VERSION ""

NS_ :

BS_:

BU_: BAP_Tester BedienDisp_vo BedienSG_hi CGS DDA Gateway Gateway_PAG GurtMikrofon OTA_FC ZR_High ZR_LIMU ZR_MIB_TOP_ab_Gen3 ZR_Standard

BO_ 987 Gateway_72: 8 Gateway_MQB
 SG_ BCM_01_Old : 0|1@1+ (1,0) [0|1] "" Airbag_MQB
 SG_ SMLS_01_Old : 1|1@1+ (1,0) [0|1] "" Motor_Diesel_MQB,Motor_Otto_MQB
 SG_ ZV_02_Old : 2|1@1+ (1,0) [0|1] "" Getriebe_DQ_Hybrid_MQB,Getriebe_DQ_MQB,Motor_Diesel_MQB,Motor_Hybrid_MQB,Motor_Otto_MQB
 SG_ Wiper_01_Old : 3|1@1+ (1,0) [0|1] "" Motor_Diesel_MQB,Motor_Hybrid_MQB,Motor_Otto_MQB
 SG_ Trailer_01_Old : 4|1@1+ (1,0) [0|1] "" Getriebe_DQ_Hybrid_MQB,Getriebe_DQ_MQB
 SG_ Climate_Sensor_02_Old : 5|1@1+ (1,0) [0|1] "" Getriebe_DQ_Hybrid_MQB,Getriebe_DQ_MQB,Motor_Diesel_MQB,Motor_Hybrid_MQB,Motor_Otto_MQB
 SG_ VSG_01_Old : 6|1@1+ (1,0) [0|1] "" Airbag_MQB
 SG_ Climate_01_Old : 7|1@1+ (1,0) [0|1] "" Vector__XXX
 SG_ WFS_01_Old : 8|1@1+ (1,0) [0|1] "" Vector__XXX
 SG_ Light_Req_01_Old : 9|1@1+ (1,0) [0|1] "" Vector__XXX
 SG_ ZV_HFS_Open : 20|1@1+ (1,0) [0|1] "" Vector__XXX
 SG_ ZV_HBFS_Open : 21|1@1+ (1,0) [0|1] "" Vector__XXX
 SG_ VS_VD_Open_ver : 22|1@1+ (1,0) [0|1] "" Airbag_MQB
 SG_ VS_VD_Closed_ver : 23|1@1+ (1,0) [0|1] "" Vector__XXX
 SG_ ZV_BT_Open : 24|1@1+ (1,0) [0|1] "" Vector__XXX
 SG_ BCM1_ReversingLight_Switch : 25|1@1+ (1,0) [0|1] "" Airbag_MQB
 SG_ ZV_FT_Open : 26|1@1+ (1,0) [0|1] "" Getriebe_DQ_Hybrid_MQB,Getriebe_DQ_MQB,Motor_Diesel_MQB,Motor_Hybrid_MQB,Motor_Otto_MQB
 SG_ Wiper_Front_Active : 27|1@1+ (1,0) [0|1] "" Motor_Diesel_MQB,Motor_Hybrid_MQB,Motor_Otto_MQB
 SG_ AAG_Trailer_Detected : 28|1@1+ (1,0) [0|1] "" Getriebe_DQ_Hybrid_MQB,Getriebe_DQ_MQB
 SG_ BCM1_MH_Switch : 29|1@1+ (1,0) [0|1] "" Vector__XXX
 SG_ ZV_HD_Open : 30|1@1+ (1,0) [0|1] "" Vector__XXX
 SG_ Wash_Front_Active : 31|1@1+ (1,0) [0|1] "" Vector__XXX
 SG_ TERM_ThermalManagement : 32|2@1+ (1,0) [0|3] "" Vector__XXX
 SG_ WFS_Key_DriveAuthorisation : 34|4@1+ (1,0) [0|15] "" Vector__XXX
 SG_ BCM1_RHeadlights_Veh_Req : 38|1@1+ (1,0) [0|1] "" Vector__XXX
 SG_ BCM1_RHeadlights_Ahg_Req : 39|1@1+ (1,0) [0|1] "" Vector__XXX
 SG_ BH_HighBeam : 49|1@1+ (1,0) [0|1] "" Vector__XXX
 SG_ BH_Indicator_Left : 50|1@1+ (1,0) [0|1] "" Motor_Diesel_MQB,Motor_Otto_MQB
 SG_ BH_Indicator_Right : 51|1@1+ (1,0) [0|1] "" Motor_Diesel_MQB,Motor_Otto_MQB
 SG_ BCM1_OBD_FStatus_ATemp : 52|4@1+ (1,0) [0|15] "" Getriebe_DQ_Hybrid_MQB,Getriebe_DQ_MQB,Motor_Diesel_MQB,Motor_Hybrid_MQB,Motor_Otto_MQB
 SG_ BCM1_Outside_Temp_Unfilt : 56|8@1+ (0.5,-50) [-50|76] "Unit_DegreCelsi" Getriebe_DQ_Hybrid_MQB,Getriebe_DQ_MQB,Motor_Diesel_MQB,Motor_Hybrid_MQB,Motor_Otto_MQB

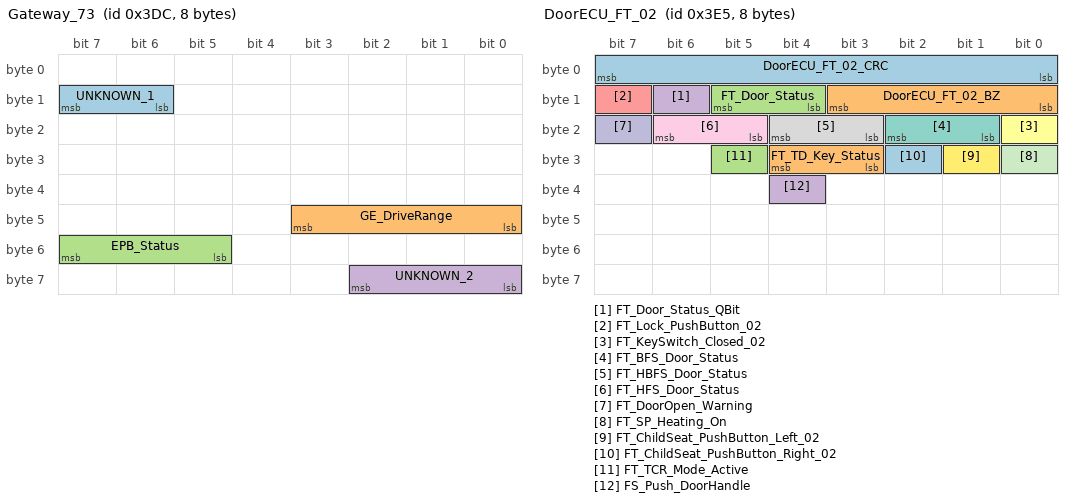
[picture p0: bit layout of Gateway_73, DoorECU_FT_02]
BO_ 988 Gateway_73: 8 XXX
 SG_ UNKNOWN_1 : 15|2@0+ (1,0) [0|3] "" XXX
 SG_ GE_DriveRange : 40|4@1+ (1,0) [0|15] "" XXX
 SG_ EPB_Status : 53|3@1+ (1,0) [0|7] "" XXX
 SG_ UNKNOWN_2 : 58|3@0+ (1,0) [0|7] "" XXX

BO_ 997 DoorECU_FT_02: 8 Gateway
 SG_ DoorECU_FT_02_CRC : 0|8@1+ (1,0) [0|255] "" Vector__XXX
 SG_ DoorECU_FT_02_BZ : 8|4@1+ (1,0) [0|15] "" Vector__XXX
 SG_ FT_Door_Status : 12|2@1+ (1,0) [0|3] "" OTA_FC,ZR_High
 SG_ FT_Door_Status_QBit : 14|1@1+ (1,0) [0|1] "" ZR_High
 SG_ FT_Lock_PushButton_02 : 15|1@1+ (1,0) [0|1] "" ZR_High
 SG_ FT_KeySwitch_Closed_02 : 16|1@1+ (1,0) [0|1] "" ZR_High
 SG_ FT_BFS_Door_Status : 17|2@1+ (1,0) [0|3] "" ZR_High
 SG_ FT_HBFS_Door_Status : 19|2@1+ (1,0) [0|3] "" ZR_High
 SG_ FT_HFS_Door_Status : 21|2@1+ (1,0) [0|3] "" ZR_High
 SG_ FT_DoorOpen_Warning : 23|1@1+ (1,0) [0|1] "" Vector__XXX
 SG_ FT_SP_Heating_On : 24|1@1+ (1,0) [0|1] "" Vector__XXX
 SG_ FT_ChildSeat_PushButton_Left_02 : 25|1@1+ (1,0) [0|1] "" ZR_High
 SG_ FT_ChildSeat_PushButton_Right_02 : 26|1@1+ (1,0) [0|1] "" ZR_High
 SG_ FT_TD_Key_Status : 27|2@1+ (1,0) [0|3] "" ZR_High
 SG_ FT_TCR_Mode_Active : 29|1@1+ (1,0) [0|1] "" Vector__XXX
 SG_ FS_Push_DoorHandle : 36|1@1+ (1,0) [0|1] "" Vector__XXX

BO_ 1004 MEB_TSK_01: 8 XXX
 SG_ TSK_State : 53|3@1+ (1,0) [0|7] "" XXX

BO_ 1031 PLA_04: 8 XXX

BO_ 1122 PSD_04: 8 ZR_High
 SG_ PSD_Segment_ID : 0|6@1+ (1,0) [2|63] "" Gateway,Gateway_PAG
 SG_ PSD_Predecessor_Segment_ID : 6|6@1+ (1,0) [2|63] "" Gateway,Gateway_PAG
 SG_ PSD_SegmentLength : 12|7@1+ (2,0) [0|254] "Unit_Meter" Gateway,Gateway_PAG,OTA_FC
 SG_ PSD_Strassenkategorie : 19|3@1+ (1,0) [0|7] "" Gateway,Gateway_PAG,OTA_FC
 SG_ PSD_EndCurvature : 22|8@1+ (1,0) [0|254] "Unit_None" Gateway,Gateway_PAG
 SG_ PSD_EndCurvature_Sign : 30|1@1+ (1,0) [0|1] "" Gateway,Gateway_PAG
 SG_ PSD_Idenditaets_ID : 31|6@1+ (1,0) [2|63] "" Gateway,Gateway_PAG
 SG_ PSD_ADAS_Quality : 37|1@1+ (1,0) [0|1] "" Gateway,Gateway_PAG
 SG_ PSD_MostLikely_Path : 38|1@1+ (1,0) [0|1] "" Gateway,Gateway_PAG
 SG_ PSD_Straightest_Path : 39|1@1+ (1,0) [0|1] "" Gateway,Gateway_PAG
 SG_ PSD_Lanes_Count : 40|3@1+ (1,0) [0|7] "" Gateway,Gateway_PAG,OTA_FC
 SG_ PSD_Bebauung : 43|1@1+ (1,0) [0|1] "" Gateway,Gateway_PAG
 SG_ PSD_Segment_Complete : 44|1@1+ (1,0) [0|1] "" Gateway,Gateway_PAG
 SG_ PSD_Ramp : 45|2@1+ (1,0) [0|3] "" Gateway,Gateway_PAG
 SG_ PSD_StartCurvature : 47|8@1+ (1,0) [0|254] "" Gateway,Gateway_PAG
 SG_ PSD_StartCurvature_Sign : 55|1@1+ (1,0) [0|1] "" Gateway,Gateway_PAG
 SG_ PSD_Abzweigerichtung : 56|1@1+ (1,0) [0|1] "" Gateway,Gateway_PAG
 SG_ PSD_Abzweigewinkel : 57|7@1+ (1.417323,0) [0|180.000021] "" Gateway,Gateway_PAG

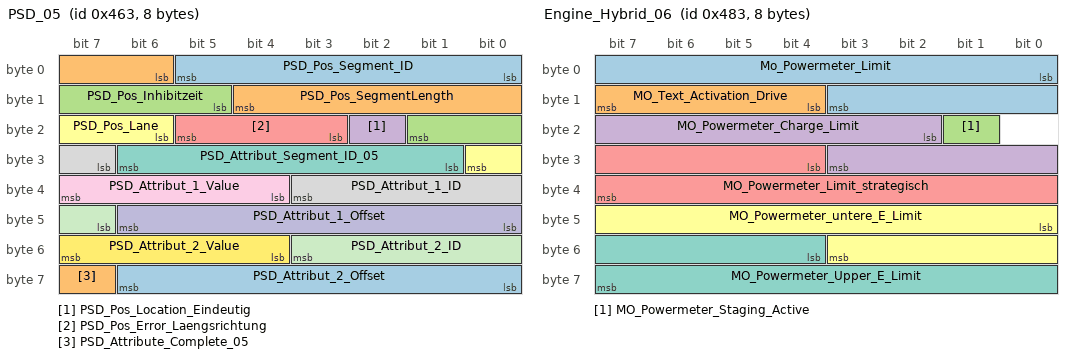
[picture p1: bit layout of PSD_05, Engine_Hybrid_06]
BO_ 1123 PSD_05: 8 ZR_High
 SG_ PSD_Pos_Segment_ID : 0|6@1+ (1,0) [2|63] "" Gateway,Gateway_PAG
 SG_ PSD_Pos_SegmentLength : 6|7@1+ (2,0) [0|254] "Unit_Meter" Gateway,Gateway_PAG
 SG_ PSD_Pos_Inhibitzeit : 13|5@1+ (10,0) [0|310] "Unit_MilliSecon" Gateway,Gateway_PAG
 SG_ PSD_Pos_Location_Eindeutig : 18|1@1+ (1,0) [0|1] "" Gateway,Gateway_PAG
 SG_ PSD_Pos_Error_Laengsrichtung : 19|3@1+ (1,0) [0|7] "" Gateway,Gateway_PAG
 SG_ PSD_Pos_Lane : 22|3@1+ (1,0) [0|7] "" Gateway,Gateway_PAG,OTA_FC
 SG_ PSD_Attribut_Segment_ID_05 : 25|6@1+ (1,0) [2|63] "" Gateway,Gateway_PAG
 SG_ PSD_Attribut_1_ID : 31|5@1+ (1,0) [1|31] "" Gateway,Gateway_PAG
 SG_ PSD_Attribut_1_Value : 36|4@1+ (1,0) [0|15] "" Gateway,Gateway_PAG
 SG_ PSD_Attribut_1_Offset : 40|7@1+ (2,0) [0|254] "Unit_Meter" Gateway,Gateway_PAG
 SG_ PSD_Attribut_2_ID : 47|5@1+ (1,0) [1|31] "" Gateway,Gateway_PAG
 SG_ PSD_Attribut_2_Value : 52|4@1+ (1,0) [0|15] "" Gateway,Gateway_PAG
 SG_ PSD_Attribut_2_Offset : 56|7@1+ (2,0) [0|254] "Unit_Meter" Gateway,Gateway_PAG
 SG_ PSD_Attribute_Complete_05 : 63|1@1+ (1,0) [0|1] "" Gateway,Gateway_PAG

BO_ 1124 PSD_06: 8 ZR_High
 SG_ PSD_06_Mux M : 0|3@1+ (1,0) [0|7] "" Gateway,Gateway_PAG
 SG_ PSD_Sys_Segment_ID m0 : 3|6@1+ (1,0) [2|63] "" Gateway,Gateway_PAG
 SG_ PSD_Sys_Laendercode m0 : 9|8@1+ (1,0) [0|255] "" Gateway,Gateway_PAG
 SG_ PSD_Sys_Speed_Unit m0 : 17|1@1+ (1,0) [0|1] "" Gateway,Gateway_PAG
 SG_ PSD_Sys_Verkehrsrichtung m0 : 18|1@1+ (1,0) [0|1] "" Gateway,Gateway_PAG
 SG_ PSD_Sys_Geometrieguete m0 : 19|2@1+ (1,0) [0|3] "" Gateway,Gateway_PAG
 SG_ PSD_Sys_Mapmatchingguete m0 : 21|2@1+ (1,0) [0|3] "" Gateway,Gateway_PAG
 SG_ PSD_Sys_Age_Map m0 : 23|3@1+ (1,0) [0|7] "" Gateway,Gateway_PAG
 SG_ PSD_Sys_RouteGuidance m0 : 26|1@1+ (1,0) [0|1] "" Gateway,Gateway_PAG,OTA_FC
 SG_ PSD_Sys_US_State m0 : 27|6@1+ (1,0) [0|63] "" Gateway,Gateway_PAG
 SG_ PSD_Sys_Quali_Geometrien m0 : 33|3@1+ (1,0) [0|7] "Unit_None" Gateway,Gateway_PAG
 SG_ PSD_Sys_Quali_LocationInfo m0 : 36|2@1+ (1,0) [0|3] "Unit_None" Gateway,Gateway_PAG
 SG_ PSD_Sys_Quali_Available m0 : 38|1@1+ (1,0) [0|1] "" Gateway,Gateway_PAG
 SG_ PSD_Sys_RouteGuidance_Changed m0 : 39|1@1+ (1,0) [0|1] "" Gateway,Gateway_PAG
 SG_ PSD_Sys_Geometrieguete_Extended m0 : 40|8@1+ (1,0) [0|255] "" Gateway,Gateway_PAG
 SG_ PSD_Sys_Quali_Other_Attribute m0 : 48|3@1+ (1,0) [0|7] "Unit_None" Gateway,Gateway_PAG
 SG_ PSD_Sys_Quali_Gradients m0 : 51|3@1+ (1,0) [0|7] "" Gateway,Gateway_PAG
 SG_ PSD_Sys_Quali_Strassenkennz m0 : 54|3@1+ (1,0) [0|7] "Unit_None" Gateway,Gateway_PAG
 SG_ PSD_Sys_Quali_Tempolimits m0 : 57|3@1+ (1,0) [0|7] "Unit_None" Gateway,Gateway_PAG
 SG_ PSD_Sys_Quali_BeforeJourneyControl m0 : 60|3@1+ (1,0) [0|7] "Unit_None" Gateway,Gateway_PAG
 SG_ PSD_Attribut_Segment_ID m1 : 3|6@1+ (1,0) [2|63] "" Gateway,Gateway_PAG
 SG_ PSD_Attribut_3_ID m1 : 9|5@1+ (1,0) [1|31] "" Gateway,Gateway_PAG
 SG_ PSD_Attribut_3_Offset m1 : 14|7@1+ (2,0) [0|254] "Unit_Meter" Gateway,Gateway_PAG
 SG_ PSD_Attribut_3_Value m1 : 21|4@1+ (1,0) [0|15] "" Gateway,Gateway_PAG
 SG_ PSD_Attribut_4_ID m1 : 25|5@1+ (1,0) [1|31] "" Gateway,Gateway_PAG
 SG_ PSD_Attribut_4_Value m1 : 30|4@1+ (1,0) [0|15] "" Gateway,Gateway_PAG
 SG_ PSD_Attribut_4_Offset m1 : 34|7@1+ (2,0) [0|254] "Unit_Meter" Gateway,Gateway_PAG
 SG_ PSD_Attribut_5_ID m1 : 41|5@1+ (1,0) [1|31] "" Gateway,Gateway_PAG
 SG_ PSD_Attribut_5_Offset m1 : 46|7@1+ (2,0) [0|254] "Unit_Meter" Gateway,Gateway_PAG
 SG_ PSD_Attribut_5_Value m1 : 53|4@1+ (1,0) [0|15] "" Gateway,Gateway_PAG
 SG_ PSD_Attribute_Complete_06 m1 : 57|1@1+ (1,0) [0|1] "" Gateway,Gateway_PAG
 SG_ PSD_Total_Segment_ID m2 : 3|6@1+ (1,0) [2|63] "" Gateway,Gateway_PAG
 SG_ PSD_Total_Offset m2 : 9|7@1+ (2,0) [0|254] "Unit_Meter" Gateway,Gateway_PAG
 SG_ PSD_Total_Speed m2 : 16|5@1+ (1,0) [0|31] "" Gateway,Gateway_PAG,OTA_FC
 SG_ PSD_Total_Type m2 : 21|2@1+ (1,0) [0|3] "" Gateway,Gateway_PAG
 SG_ PSD_Total_Lane_Speed_Limit m2 : 23|6@1+ (1,0) [0|63] "" Gateway,Gateway_PAG
 SG_ PSD_Total_Speed_TrailerCombo m2 : 29|2@1+ (1,0) [0|3] "" Gateway,Gateway_PAG
 SG_ PSD_Total_Speed_Witter m2 : 31|2@1+ (1,0) [0|3] "" Gateway,Gateway_PAG
 SG_ PSD_Total_Speed_Tag_Req m2 : 33|3@1+ (1,0) [0|7] "" Gateway,Gateway_PAG
 SG_ PSD_Total_Speed_Tag_End m2 : 36|3@1+ (1,0) [0|7] "" Gateway,Gateway_PAG
 SG_ PSD_Total_Speed_Std_Req m2 : 39|5@1+ (1,0) [0|24] "Unit_Hours" Gateway,Gateway_PAG
 SG_ PSD_Total_Speed_Std_End m2 : 44|5@1+ (1,0) [0|24] "Unit_Hours" Gateway,Gateway_PAG
 SG_ PSD_Total_NoOvertaking m2 : 49|2@1+ (1,0) [0|3] "" Gateway,Gateway_PAG
 SG_ PSD_Total_VariableTrafficSign m2 : 51|3@1+ (1,0) [0|7] "" Gateway,Gateway_PAG
 SG_ PSD_VariableTrafficSign_Type m2 : 54|2@1+ (1,0) [0|3] "" Gateway,Gateway_PAG
 SG_ PSD_Total_Gesetzlich_Kategorie m2 : 56|3@1+ (1,0) [0|7] "" Gateway,Gateway_PAG
 SG_ PSD_Total_Gesetzlich_Additional m2 : 59|2@1+ (1,0) [0|3] "" Gateway,Gateway_PAG
 SG_ PSD_Total_TrafficSign_Source m2 : 61|2@1+ (1,0) [0|3] "" Gateway,Gateway_PAG
 SG_ PSD_Total_Attribute_Complete m2 : 63|1@1+ (1,0) [0|1] "" Gateway,Gateway_PAG
 SG_ PSD_Tree_Length_VZ m3 : 3|1@1+ (1,0) [0|1] "" Gateway,Gateway_PAG
 SG_ PSD_Tree_Length m3 : 4|25@1+ (1e-05,0) [0|180] "Unit_DegreOfArc" Gateway,Gateway_PAG
 SG_ PSD_Tree_Width_VZ m3 : 29|1@1+ (1,0) [0|1] "" Gateway,Gateway_PAG
 SG_ PSD_Tree_Width m3 : 30|24@1+ (1e-05,0) [0|90] "Unit_DegreOfArc" Gateway,Gateway_PAG
 SG_ PSD_Tree_OffDirection m3 : 54|10@1+ (0.3515625,0) [0|359.6484375] "Unit_DegreOfArc" Gateway,Gateway_PAG
 SG_ PSD_Gradient_1_Segment_ID m4 : 3|6@1+ (1,0) [2|63] "" Gateway,Gateway_PAG
 SG_ PSD_Gradient_1_A_Gradient m4 : 9|7@1+ (0.12,0) [0|15] "Unit_PerCent" Gateway,Gateway_PAG
 SG_ PSD_Gradient_1_A_Sign m4 : 16|1@1+ (1,0) [0|1] "" Gateway,Gateway_PAG
 SG_ PSD_Gradient_1_A_Offset m4 : 17|7@1+ (2,0) [0|254] "Unit_Meter" Gateway,Gateway_PAG
 SG_ PSD_Gradient_1_B_Gradient m4 : 24|7@1+ (0.12,0) [0|15] "Unit_PerCent" Gateway,Gateway_PAG
 SG_ PSD_Gradient_1_B_Sign m4 : 31|1@1+ (1,0) [0|1] "" Gateway,Gateway_PAG
 SG_ PSD_Gradient_1_B_Offset m4 : 32|7@1+ (2,0) [0|254] "Unit_Meter" Gateway,Gateway_PAG
 SG_ PSD_Gradient_1_Attribute_kompl m4 : 39|1@1+ (1,0) [0|1] "" Gateway,Gateway_PAG
 SG_ PSD_Gradient_2_Segment_ID m4 : 40|6@1+ (1,0) [2|63] "" Gateway,Gateway_PAG
 SG_ PSD_Gradient_2_Gradient m4 : 46|7@1+ (0.12,0) [0|15] "Unit_PerCent" Gateway,Gateway_PAG
 SG_ PSD_Gradient_2_Sign m4 : 53|1@1+ (1,0) [0|1] "" Gateway,Gateway_PAG
 SG_ PSD_Gradient_2_Offset m4 : 54|7@1+ (2,0) [0|254] "Unit_Meter" Gateway,Gateway_PAG
 SG_ PSD_Gradient_2_Attribute_kompl m4 : 61|1@1+ (1,0) [0|1] "" Gateway,Gateway_PAG

BO_ 1153 MainUnit_01: 8 ZR_High
 SG_ ZR_LoGeWa_Event_ClusterWarning : 0|4@1+ (1,0) [0|15] "" Gateway,Gateway_PAG
 SG_ Nav_FoD_Status : 4|3@1+ (1,0) [0|7] "" Gateway,Gateway_PAG
 SG_ MIB_ToneAlternator_PH_Available : 9|3@1+ (1,0) [0|7] "" Gateway,Gateway_PAG
 SG_ MMI_Counter_Bedienevent : 12|4@1+ (1,0) [0|15] "" Gateway,Gateway_PAG
 SG_ DSSS_Warning : 16|5@1+ (1,0) [0|31] "" Gateway,Gateway_PAG
 SG_ ZR_Kindersicherung_RSE : 21|1@1+ (1,0) [0|1] "" Gateway,Gateway_PAG
 SG_ ZR_RSE_Activate : 22|1@1+ (1,0) [0|1] "" Gateway,Gateway_PAG
 SG_ MMI_SDS_Active : 23|1@1+ (1,0) [0|1] "" Gateway,Gateway_PAG
 SG_ MU_SecondDisplay : 24|3@1+ (1,0) [0|7] "" Gateway,Gateway_PAG
 SG_ MMI_Phone_Active : 27|1@1+ (1,0) [0|1] "" Gateway,Gateway_PAG
 SG_ MMI_Belt_Mic_ref : 28|1@1+ (1,0) [0|1] "" Gateway,Gateway_PAG,GurtMikrofon
 SG_ ZR_Status_Staging : 29|2@1+ (1,0) [0|3] "" Gateway,Gateway_PAG
 SG_ MMI_Gauges_active : 31|1@1+ (1,0) [0|1] "" BedienDisp_vo,Gateway,Gateway_PAG
 SG_ MU_Update_Time : 32|8@1+ (0.1,0) [0|25.5] "Unit_Hours" Gateway,Gateway_PAG
 SG_ ZR_MXB_Manoever_Announcement : 42|2@1+ (1,0) [0|3] "" Gateway,Gateway_PAG
 SG_ ZR_LAPP_SpecialMode_Status : 44|2@1+ (1,0) [0|3] "" DDA,Gateway,Gateway_PAG
 SG_ MMI_StartStop_Info : 46|2@1+ (1,0) [0|3] "" Gateway,Gateway_PAG
 SG_ ZR_Parking_SpecialMode : 48|4@1+ (1,0) [0|15] "" DDA,Gateway,Gateway_PAG
 SG_ ZR_Rundenbewertung : 52|4@1+ (1,0) [0|15] "" Gateway,Gateway_PAG
 SG_ ZR_Rundenfortschritt : 56|8@1+ (0.5,0) [0|100] "Unit_PerCent" Gateway,Gateway_PAG

BO_ 1155 Engine_Hybrid_06: 8 Gateway
 SG_ Mo_Powermeter_Limit : 0|12@1+ (1,0) [0|4092] "" ZR_High,ZR_LIMU,ZR_MIB_TOP_ab_Gen3
 SG_ MO_Text_Activation_Drive : 12|4@1+ (1,0) [0|15] "" Vector__XXX
 SG_ MO_Powermeter_Staging_Active : 17|1@1+ (1,0) [0|1] "" Vector__XXX
 SG_ MO_Powermeter_Charge_Limit : 18|10@1+ (1,0) [0|1021] "Unit_None" Vector__XXX
 SG_ MO_Powermeter_Limit_strategisch : 28|12@1+ (1,0) [0|4093] "Unit_None" Vector__XXX
 SG_ MO_Powermeter_untere_E_Limit : 40|12@1+ (1,0) [0|4093] "Unit_None" Vector__XXX
 SG_ MO_Powermeter_Upper_E_Limit : 52|12@1+ (1,0) [0|4093] "Unit_None" Vector__XXX

BO_ 1163 BEM_06: 8 XXX
 SG_ CRC : 0|8@1+ (1,0) [0|255] "" XXX
 SG_ CHK : 8|4@1+ (1,0) [0|15] "" XXX

BO_ 1175 ParkAssist_01: 8 Gateway
 SG_ PH_Visualisierung : 0|3@1+ (1,0) [0|7] "" AWC
 SG_ PDC_Tonausgabe_Front : 4|4@1+ (1,0) [0|15] "" Vector__XXX
 SG_ PDC_Tonausgabe_Rear : 8|4@1+ (1,0) [0|15] "" Vector__XXX
 SG_ PH_Retrofit_Stop_Req : 12|1@1+ (1,0) [0|1] "" Vector__XXX
 SG_ PH_ShutoffCause : 13|3@1+ (1,0) [0|7] "" AWC
 SG_ PH_Opt_Display_V_On : 16|1@1+ (1,0) [0|1] "" Vector__XXX
 SG_ PH_Opt_Display_H_On : 17|1@1+ (1,0) [0|1] "" Vector__XXX
 SG_ PH_Opt_Disp_V_Obstacle : 18|1@1+ (1,0) [0|1] "" Vector__XXX
 SG_ PH_Opt_Disp_H_Obstacle : 19|1@1+ (1,0) [0|1] "" Vector__XXX
 SG_ PH_ToneSender_V_Active : 20|1@1+ (1,0) [0|1] "" Vector__XXX
 SG_ PH_ToneSender_H_Active : 21|1@1+ (1,0) [0|1] "" Vector__XXX
 SG_ PH_ToneSender_Mute : 22|1@1+ (1,0) [0|1] "" Vector__XXX
 SG_ PH_Req_AudioDucking : 23|1@1+ (1,0) [0|1] "" Vector__XXX
 SG_ PH_ToneSender_H_Available : 24|1@1+ (1,0) [0|1] "" Vector__XXX
 SG_ PLA_Req_OpenShift_RVC : 25|1@1+ (1,0) [0|1] "" Vector__XXX
 SG_ PH_PushButton : 28|2@1+ (1,0) [0|3] "" Vector__XXX
 SG_ PH_Req_Roof : 30|2@1+ (1,0) [0|3] "" Vector__XXX
 SG_ PH_Frequency_Rear : 32|4@1+ (1,0) [0|15] "" Vector__XXX
 SG_ PH_Volume_Rear : 36|4@1+ (1,0) [0|15] "" Vector__XXX
 SG_ PH_Frequency_Front : 40|4@1+ (1,0) [0|15] "" Vector__XXX
 SG_ PH_Volume_Front : 44|4@1+ (1,0) [0|15] "" Vector__XXX
 SG_ PH_StartStop_Info : 49|2@1+ (1,0) [0|3] "" Vector__XXX
 SG_ PH_Stoermeldung : 52|4@1+ (1,0) [0|15] "" Vector__XXX
 SG_ PH_Defective : 56|1@1+ (1,0) [0|1] "" Vector__XXX
 SG_ PH_Disturbed : 57|1@1+ (1,0) [0|1] "" Vector__XXX
 SG_ PH_Systemzustand : 58|3@1+ (1,0) [0|7] "" AWC
 SG_ PH_Display_Kundenwunsch : 61|2@1+ (1,0) [0|3] "" Vector__XXX

BO_ 1283 HVK_01: 8 Gateway
 SG_ HVK_01_CRC : 0|8@1+ (1,0) [0|255] "" BMC_MLBevo,DCDC_800V_PAG,DCDC_HV,DCDC_HV_02,FCU_MLBevo_FCEV,Ladegeraet_2,Ladegeraet_Konzern,LE1,LE2,LE_MLBevo,TME
 SG_ HVK_01_BZ : 8|4@1+ (1,0) [0|15] "" BMC_MLBevo,DCDC_800V_PAG,DCDC_HV,DCDC_HV_02,FCU_MLBevo_FCEV,Ladegeraet_2,Ladegeraet_Konzern,LE1,LE2,LE_MLBevo,TME
 SG_ HVK_ActualMode_Req : 12|1@1+ (1,0) [0|1] "" BMC_MLBevo,DCDC_HV,FCU_MLBevo_FCEV,Ladegeraet_2,Ladegeraet_Konzern,LE1,LE2,LE_MLBevo
 SG_ HVK_TN1_TargetMode : 13|2@1+ (1,0) [0|3] "" DCDC_HV_02,FCU_MLBevo_FCEV
 SG_ HVK_MO_EmTargetState : 16|8@1+ (1,0) [0|255] "" FCU_MLBevo_FCEV
 SG_ HVK_BMS_TargetMode : 24|3@1+ (1,0) [0|7] "" BMC_MLBevo,FCU_MLBevo_FCEV
 SG_ HVK_DCDC_TargetMode : 27|3@1+ (1,0) [0|7] "" DCDC_800V_PAG,DCDC_HV,FCU_MLBevo_FCEV,LE_MLBevo
 SG_ HVK_EKK_TargetMode : 30|3@1+ (1,0) [0|7] "" FCU_MLBevo_FCEV,TME
 SG_ HVK_HVPTC_TargetMode : 33|3@1+ (1,0) [0|7] "" FCU_MLBevo_FCEV,TME
 SG_ HVK_HVLM_TargetMode : 36|3@1+ (1,0) [0|7] "" DCDC_HV_02,FCU_MLBevo_FCEV,Ladegeraet_Konzern
 SG_ HVK_HV_Network_Warnings : 39|2@1+ (1,0) [0|3] "" FCU_MLBevo_FCEV
 SG_ HV_VehicleElectrics_Active : 41|1@1+ (1,0) [0|1] "" DCDC_HV_02,FCU_MLBevo_FCEV,Ladegeraet_Konzern,LE1,LE2,LE_MLBevo
 SG_ HV_VehicleElectrics_Error : 42|1@1+ (1,0) [0|1] "" FCU_MLBevo_FCEV,Ladegeraet_Konzern,TME
 SG_ HVK_Gesamtst_Spgfreiheit : 43|2@1+ (1,0) [0|3] "" FCU_MLBevo_FCEV
 SG_ HVK_ActiveEntladung_Req : 45|1@1+ (1,0) [0|1] "" DCDC_800V_PAG,DCDC_HV,DCDC_HV_02,FCU_MLBevo_FCEV,LE1,LE2,LE_MLBevo
 SG_ HVK_Iso_Measurement_Start : 50|3@1+ (1,0) [0|7] "" BMC_MLBevo,FCU_MLBevo_FCEV
 SG_ HVK_DCDC_EKK_TargetMode : 62|2@1+ (1,0) [0|3] "" DCDC_800V_PAG,FCU_MLBevo_FCEV

BO_ 1312 Airbag_02: 8 Gateway
 SG_ LoGeWa_Event_ClusterWarning : 12|4@1+ (1,0) [0|15] "" ZR_High
 SG_ FROM_Request_eCall : 16|1@1+ (1,0) [0|1] "" ZR_High
 SG_ FROM_Impact_Side_Passenger : 17|1@1+ (1,0) [0|1] "" Vector__XXX
 SG_ FROM_Impact_Rollover : 18|1@1+ (1,0) [0|1] "" Vector__XXX
 SG_ FROM_Impact_FGS : 19|1@1+ (1,0) [0|1] "" Vector__XXX
 SG_ FROM_Impact_Front_Passenger : 20|1@1+ (1,0) [0|1] "" Vector__XXX
 SG_ FROM_Impact_Front_Driver : 21|1@1+ (1,0) [0|1] "" Vector__XXX
 SG_ FROM_Impact_Rear_Passenger : 22|1@1+ (1,0) [0|1] "" Vector__XXX
 SG_ FROM_Impact_Rear_Driver : 23|1@1+ (1,0) [0|1] "" Vector__XXX
 SG_ FROM_WrapFold_Row2_MI : 24|2@1+ (1,0) [0|3] "" Vector__XXX
 SG_ FROM_Occupancy_VB : 26|2@1+ (1,0) [0|3] "" BedienSG_hi,GurtMikrofon,ZR_High,ZR_LIMU,ZR_MIB_TOP_ab_Gen3
 SG_ FROM_ShutoffReq_SIH_BF : 28|1@1+ (1,0) [0|1] "" ZR_High
 SG_ FROM_Impact_Side_Driver : 29|1@1+ (1,0) [0|1] "" Vector__XXX
 SG_ SC_PAO_Schriftzug_Req : 30|2@1+ (1,0) [0|3] "" ZR_High
 SG_ SC_PAO_ON_Req : 32|2@1+ (1,0) [0|3] "" ZR_High
 SG_ SC_PAO_OFF_Req : 34|2@1+ (1,0) [0|3] "" ZR_High
 SG_ FROM_CrashSeverity : 36|3@1+ (1,0) [0|7] "" Vector__XXX
 SG_ FROM_Request_USM : 39|1@1+ (1,0) [0|1] "" ZR_Standard
 SG_ FROM_BeltBuckle_FA : 40|2@1+ (1,0) [0|3] "" BedienSG_hi,GurtMikrofon,ZR_High
 SG_ FROM_BeltBuckle_BF : 42|2@1+ (1,0) [0|3] "" BedienSG_hi,GurtMikrofon,ZR_High,ZR_LIMU,ZR_MIB_TOP_ab_Gen3
 SG_ FROM_BeltBuckle_Row2_FA : 44|2@1+ (1,0) [0|3] "" BedienSG_hi,ZR_High,ZR_LIMU,ZR_MIB_TOP_ab_Gen3
 SG_ FROM_BeltBuckle_Row2_MI : 46|2@1+ (1,0) [0|3] "" BedienSG_hi,ZR_High,ZR_LIMU,ZR_MIB_TOP_ab_Gen3
 SG_ FROM_BeltBuckle_Row2_BF : 48|2@1+ (1,0) [0|3] "" BedienSG_hi,ZR_High,ZR_LIMU,ZR_MIB_TOP_ab_Gen3
 SG_ FROM_BeltBuckle_Row3_FA : 50|2@1+ (1,0) [0|3] "" BedienSG_hi,ZR_High
 SG_ FROM_BeltBuckle_Row3_MI : 52|2@1+ (1,0) [0|3] "" BedienSG_hi,ZR_High
 SG_ FROM_BeltBuckle_Row3_BF : 54|2@1+ (1,0) [0|3] "" BedienSG_hi,ZR_High
 SG_ FROM_SeatPos_Sens_FA : 56|2@1+ (1,0) [0|3] "" ZR_High
 SG_ FROM_SeatPos_Sens_BF : 58|2@1+ (1,0) [0|3] "" ZR_High
 SG_ FROM_WrapFold_Row2_BF : 60|2@1+ (1,0) [0|3] "" ZR_High
 SG_ FROM_WrapFold_Row2_FA : 62|2@1+ (1,0) [0|3] "" ZR_High

BO_ 1349 Airbag_04: 8 Gateway
 SG_ FROM_BeltWarn_Row2_FA : 20|2@1+ (1,0) [0|3] "" Vector__XXX
 SG_ FROM_BeltWarn_Row2_BF : 22|2@1+ (1,0) [0|3] "" Vector__XXX
 SG_ AbstWarn_MV_FAS_Func_Status : 24|2@1+ (1,0) [0|3] "" ZR_High
 SG_ WarnBrake_Charisma_Status : 26|2@1+ (1,0) [0|3] "" Vector__XXX
 SG_ WarnBrake_Charisma_DrivePr : 28|4@1+ (1,0) [0|15] "" Vector__XXX
 SG_ FROM_BeltWarn_Row2_MI : 32|2@1+ (1,0) [0|3] "" Vector__XXX
 SG_ FROM_BeltWarn_Row3_FA : 34|2@1+ (1,0) [0|3] "" Vector__XXX
 SG_ FROM_BeltWarn_Row3_MI : 36|2@1+ (1,0) [0|3] "" Vector__XXX
 SG_ FROM_BeltWarn_Row3_BF : 38|2@1+ (1,0) [0|3] "" Vector__XXX
 SG_ LGI_FAS_Func_Status : 40|2@1+ (1,0) [0|3] "" ZR_High
 SG_ PreCrash_FAS_Func_Status : 42|3@1+ (1,0) [0|7] "" ZR_High
 SG_ FROM_SBR_Rear_Fitment : 48|2@1+ (1,0) [0|3] "" Vector__XXX
 SG_ AWV_OnPosition_System_ASG : 51|1@1+ (1,0) [0|1] "" Vector__XXX
 SG_ AWV_OnPosition_Warning_ASG : 52|3@1+ (1,0) [0|7] "" Vector__XXX
 SG_ SC_PreSense_Mode_Warning_NV : 55|3@1+ (1,0) [0|7] "" Vector__XXX
 SG_ SC_PreSense_Mode_Warning_MV : 58|3@1+ (1,0) [0|7] "" Vector__XXX
 SG_ SC_PreSense_Mode_System_MV : 61|1@1+ (1,0) [0|1] "" Vector__XXX
 SG_ SC_PreSense_Mode_System_NV : 62|1@1+ (1,0) [0|1] "" Vector__XXX
 SG_ SC_PreSense_Mode_System_KAS : 63|1@1+ (1,0) [0|1] "" Vector__XXX

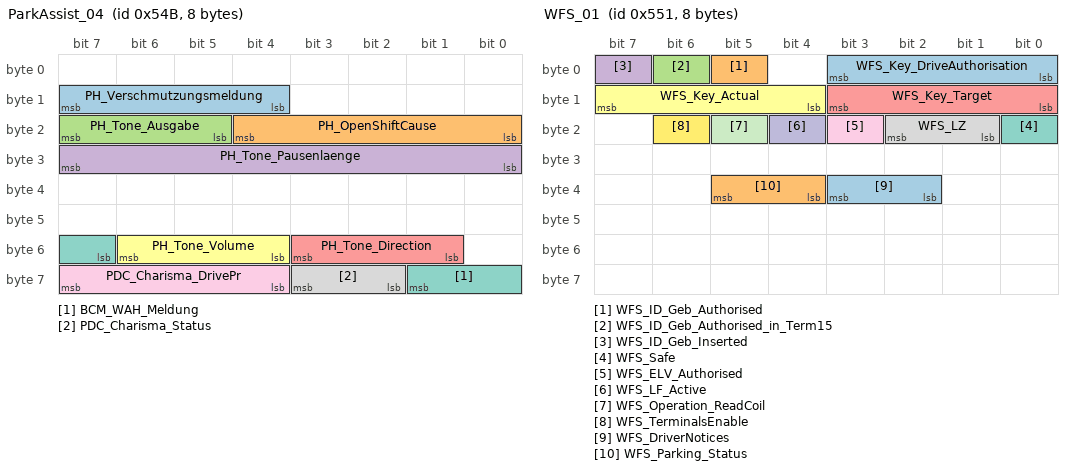
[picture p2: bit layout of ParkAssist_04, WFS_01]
BO_ 1355 ParkAssist_04: 8 Gateway
 SG_ PH_Verschmutzungsmeldung : 12|4@1+ (1,0) [0|15] "" Vector__XXX
 SG_ PH_OpenShiftCause : 16|5@1+ (1,0) [0|31] "" AWC
 SG_ PH_Tone_Ausgabe : 21|3@1+ (1,0) [0|7] "" Vector__XXX
 SG_ PH_Tone_Pausenlaenge : 24|8@1+ (1,0) [0|255] "" Vector__XXX
 SG_ PH_Tone_Direction : 49|3@1+ (1,0) [0|7] "" Vector__XXX
 SG_ PH_Tone_Volume : 52|3@1+ (1,0) [0|7] "" Vector__XXX
 SG_ BCM_WAH_Meldung : 55|3@1+ (1,0) [0|7] "" Vector__XXX
 SG_ PDC_Charisma_Status : 58|2@1+ (1,0) [0|3] "" Vector__XXX
 SG_ PDC_Charisma_DrivePr : 60|4@1+ (1,0) [0|15] "" Vector__XXX

BO_ 1361 WFS_01: 8 Gateway
 SG_ WFS_Key_DriveAuthorisation : 0|4@1+ (1,0) [0|15] "" ZR_High,ZR_LIMU,ZR_MIB_TOP_ab_Gen3,ZR_Standard
 SG_ WFS_ID_Geb_Authorised : 5|1@1+ (1,0) [0|1] "" ZR_High
 SG_ WFS_ID_Geb_Authorised_in_Term15 : 6|1@1+ (1,0) [0|1] "" Vector__XXX
 SG_ WFS_ID_Geb_Inserted : 7|1@1+ (1,0) [0|1] "" ZR_High
 SG_ WFS_Key_Target : 8|4@1+ (1,0) [0|15] "" ZR_High,ZR_LIMU,ZR_MIB_TOP_ab_Gen3,ZR_Standard
 SG_ WFS_Key_Actual : 12|4@1+ (1,0) [0|15] "" ZR_High,ZR_LIMU,ZR_MIB_TOP_ab_Gen3,ZR_Standard
 SG_ WFS_Safe : 16|1@1+ (1,0) [0|1] "" Vector__XXX
 SG_ WFS_LZ : 17|2@1+ (1,0) [0|3] "" Vector__XXX
 SG_ WFS_ELV_Authorised : 19|1@1+ (1,0) [0|1] "" Vector__XXX
 SG_ WFS_LF_Active : 20|1@1+ (1,0) [0|1] "" Vector__XXX
 SG_ WFS_Operation_ReadCoil : 21|1@1+ (1,0) [0|1] "" Vector__XXX
 SG_ WFS_TerminalsEnable : 22|1@1+ (1,0) [0|1] "" Vector__XXX
 SG_ WFS_DriverNotices : 34|2@1+ (1,0) [0|3] "" Vector__XXX
 SG_ WFS_Parking_Status : 36|2@1+ (1,0) [0|3] "" Vector__XXX

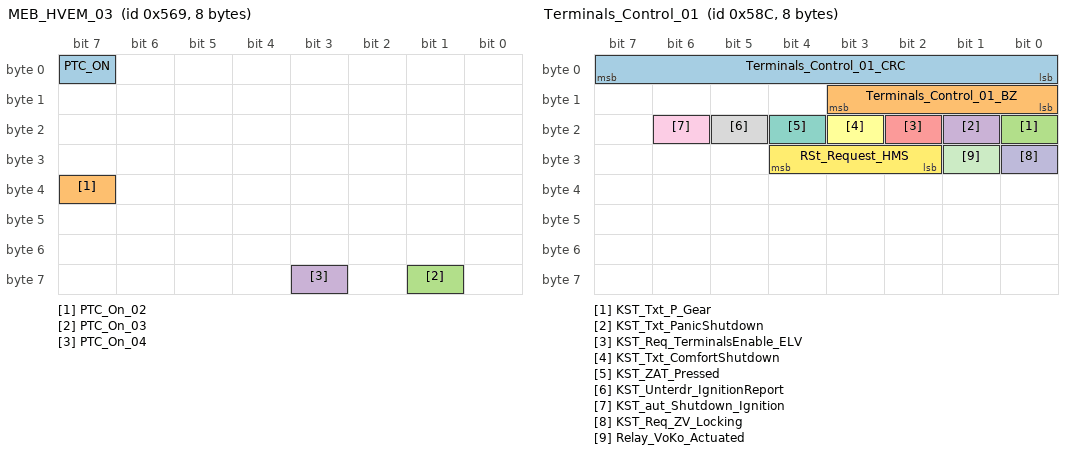
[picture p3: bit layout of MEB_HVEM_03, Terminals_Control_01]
BO_ 1385 MEB_HVEM_03: 8 XXX
 SG_ PTC_ON : 7|1@0+ (1,0) [0|1] "" XXX
 SG_ PTC_On_02 : 39|1@0+ (1,0) [0|1] "" XXX
 SG_ PTC_On_03 : 57|1@0+ (1,0) [0|1] "" XXX
 SG_ PTC_On_04 : 59|1@0+ (1,0) [0|1] "" XXX

BO_ 1411 ZV_02: 8 Gateway
 SG_ BCM_FH_Enable : 12|1@1+ (1,0) [0|1] "" BedienDisp_vo
 SG_ BCM_ComfortFunc_Enable : 13|1@1+ (1,0) [0|1] "" Vector__XXX
 SG_ BCM_HSK_Enable : 14|1@1+ (1,0) [0|1] "" Vector__XXX
 SG_ BCM_Roof_Enable : 15|1@1+ (1,0) [0|1] "" ZR_High
 SG_ ZV_Locked_Internal_Actual : 16|1@1+ (1,0) [0|1] "" DDA,OTA_FC,ZR_High
 SG_ ZV_Locked_External_Actual : 17|1@1+ (1,0) [0|1] "" DDA,OTA_FC,ZR_High
 SG_ ZV_Locked_Internal_Target : 18|1@1+ (1,0) [0|1] "" ZR_High
 SG_ ZV_Locked_External_Target : 19|1@1+ (1,0) [0|1] "" OTA_FC,ZR_High,ZR_LIMU,ZR_MIB_TOP_ab_Gen3,ZR_Standard
 SG_ ZV_Safed_External_Actual : 20|1@1+ (1,0) [0|1] "" ZR_High
 SG_ ZV_Safed_External_Target : 21|1@1+ (1,0) [0|1] "" ZR_High,ZR_LIMU,ZR_MIB_TOP_ab_Gen3
 SG_ ZV_Einzeltuerentriegelung : 22|1@1+ (1,0) [0|1] "" Vector__XXX
 SG_ ZV_Heckeinzelentriegelung : 23|1@1+ (1,0) [0|1] "" Vector__XXX
 SG_ ZV_FT_Open : 24|1@1+ (1,0) [0|1] "" DDA,OTA_FC,ZR_High,ZR_LIMU,ZR_MIB_TOP_ab_Gen3,ZR_Standard
 SG_ ZV_BT_Open : 25|1@1+ (1,0) [0|1] "" DDA,OTA_FC,ZR_High,ZR_LIMU,ZR_MIB_TOP_ab_Gen3,ZR_Standard
 SG_ ZV_HFS_Open : 26|1@1+ (1,0) [0|1] "" DDA,OTA_FC,ZR_High,ZR_LIMU,ZR_MIB_TOP_ab_Gen3,ZR_Standard
 SG_ ZV_HBFS_Open : 27|1@1+ (1,0) [0|1] "" DDA,OTA_FC,ZR_High,ZR_LIMU,ZR_MIB_TOP_ab_Gen3,ZR_Standard
 SG_ ZV_HD_Open : 28|1@1+ (1,0) [0|1] "" DDA,OTA_FC,ZR_High,ZR_LIMU,ZR_MIB_TOP_ab_Gen3,ZR_Standard
 SG_ ZV_HS_Open : 29|1@1+ (1,0) [0|1] "" OTA_FC,ZR_High
 SG_ IRUE_Active : 30|1@1+ (1,0) [0|1] "" ZR_High
 SG_ DWA_Active : 31|1@1+ (1,0) [0|1] "" ZR_High
 SG_ HD_MainDetent : 32|1@1+ (1,0) [0|1] "" OTA_FC,ZR_High
 SG_ HD_PreDetent : 33|1@1+ (1,0) [0|1] "" OTA_FC,ZR_High
 SG_ FFB_CarFinder : 38|1@1+ (1,0) [0|1] "" Vector__XXX
 SG_ FFB_ComfortOpen : 39|1@1+ (1,0) [0|1] "" Vector__XXX
 SG_ FFB_ComfortClose : 40|1@1+ (1,0) [0|1] "" Vector__XXX
 SG_ ZV_Key_Zugang : 42|4@1+ (1,0) [0|15] "" ZR_High
 SG_ ZV_SafeFunction_Active : 46|1@1+ (1,0) [0|1] "" ZR_High
 SG_ FBS_Warn_Key_Batt : 47|1@1+ (1,0) [0|1] "" ZR_High
 SG_ ZV_OpeningMode : 48|2@1+ (1,0) [0|3] "" Vector__XXX
 SG_ HFS_Locked : 50|1@1+ (1,0) [0|1] "" OTA_FC
 SG_ HFS_Safed : 51|1@1+ (1,0) [0|1] "" Vector__XXX
 SG_ HBFS_Locked : 52|1@1+ (1,0) [0|1] "" OTA_FC
 SG_ HBFS_Safed : 53|1@1+ (1,0) [0|1] "" Vector__XXX
 SG_ ZV_Actual_State_Available : 54|1@1+ (1,0) [0|1] "" OTA_FC,ZR_High
 SG_ IRUE_PushButton_Fkts_LED : 55|1@1+ (1,0) [0|1] "" ZR_High
 SG_ ZV_FuelFlap_Open : 56|1@1+ (1,0) [0|1] "" ZR_High
 SG_ ZV_Blind_Open : 57|1@1+ (1,0) [0|1] "" ZR_High
 SG_ ZV_Blind_Closed : 58|1@1+ (1,0) [0|1] "" ZR_High
 SG_ ZV_SAD_Open : 59|1@1+ (1,0) [0|1] "" ZR_High
 SG_ ZV_SAD_Closed : 60|1@1+ (1,0) [0|1] "" ZR_High
 SG_ BCM_FuelFlapActuator_Error : 61|1@1+ (1,0) [0|1] "" ZR_High
 SG_ ZV_Locked_Target : 62|2@1+ (1,0) [0|3] "" Vector__XXX

BO_ 1413 SystemInfo_01: 8 Gateway
 SG_ SI_Collective_ECU_Error : 0|6@1+ (1,0) [0|60] "" ZR_High,ZR_LIMU,ZR_MIB_TOP_ab_Gen3,ZR_Standard
 SG_ SI_Diagnostics_Active : 7|1@1+ (1,0) [0|1] "" ZR_High,ZR_LIMU,ZR_MIB_TOP_ab_Gen3,ZR_Standard
 SG_ SI_QRS_Mode : 8|1@1+ (1,0) [0|1] "" BedienSG_hi,ZR_High,ZR_LIMU,ZR_MIB_TOP_ab_Gen3,ZR_Standard
 SG_ SI_T_Mode : 9|1@1+ (1,0) [0|1] "" BedienDisp_vo,BedienSG_hi,DDA,ZR_High,ZR_LIMU,ZR_MIB_TOP_ab_Gen3,ZR_Standard
 SG_ SI_NWDF : 10|1@1+ (1,0) [0|1] "" BedienDisp_vo,BedienSG_hi,DDA,ZR_High,ZR_LIMU,ZR_MIB_TOP_ab_Gen3,ZR_Standard
 SG_ SI_NWDF_Valid : 11|1@1+ (1,0) [0|1] "" BedienDisp_vo,BedienSG_hi,DDA,ZR_High,ZR_LIMU,ZR_MIB_TOP_ab_Gen3,ZR_Standard
 SG_ SI_GeneralFault : 12|1@1+ (1,0) [0|1] "" ZR_High,ZR_LIMU,ZR_MIB_TOP_ab_Gen3,ZR_Standard
 SG_ GW_KD_Error : 13|1@1+ (1,0) [0|1] "" ZR_High,ZR_MIB_TOP_ab_Gen3,ZR_Standard
 SG_ SI_T_Protection : 14|1@1+ (1,0) [0|1] "" BedienSG_hi,ZR_High,ZR_LIMU,ZR_MIB_TOP_ab_Gen3,ZR_Standard
 SG_ SI_BUS_01 : 16|1@1+ (1,0) [0|1] "" ZR_High,ZR_LIMU,ZR_MIB_TOP_ab_Gen3,ZR_Standard
 SG_ SI_BUS_02 : 17|1@1+ (1,0) [0|1] "" ZR_High,ZR_LIMU,ZR_MIB_TOP_ab_Gen3,ZR_Standard
 SG_ SI_BUS_03 : 18|1@1+ (1,0) [0|1] "" BedienSG_hi,DDA,ZR_High,ZR_LIMU,ZR_MIB_TOP_ab_Gen3,ZR_Standard
 SG_ SI_BUS_04 : 19|1@1+ (1,0) [0|1] "" BedienSG_hi,ZR_High,ZR_LIMU,ZR_MIB_TOP_ab_Gen3,ZR_Standard
 SG_ SI_BUS_05 : 20|1@1+ (1,0) [0|1] "" ZR_High,ZR_LIMU,ZR_MIB_TOP_ab_Gen3,ZR_Standard
 SG_ SI_BUS_06 : 21|1@1+ (1,0) [0|1] "" ZR_High,ZR_LIMU,ZR_MIB_TOP_ab_Gen3,ZR_Standard
 SG_ SI_BUS_07 : 22|1@1+ (1,0) [0|1] "" ZR_High,ZR_LIMU,ZR_MIB_TOP_ab_Gen3,ZR_Standard
 SG_ SI_BUS_08 : 23|1@1+ (1,0) [0|1] "" ZR_High,ZR_LIMU,ZR_MIB_TOP_ab_Gen3,ZR_Standard
 SG_ SI_BUS_09 : 24|1@1+ (1,0) [0|1] "" ZR_High,ZR_LIMU,ZR_MIB_TOP_ab_Gen3,ZR_Standard
 SG_ SI_BUS_10 : 25|1@1+ (1,0) [0|1] "" BedienSG_hi,DDA,ZR_High,ZR_LIMU,ZR_MIB_TOP_ab_Gen3,ZR_Standard
 SG_ SI_BUS_11 : 26|1@1+ (1,0) [0|1] "" ZR_High,ZR_LIMU,ZR_MIB_TOP_ab_Gen3,ZR_Standard
 SG_ SI_BUS_12 : 27|1@1+ (1,0) [0|1] "" DDA,ZR_High,ZR_LIMU,ZR_MIB_TOP_ab_Gen3,ZR_Standard
 SG_ SI_BUS_13 : 28|1@1+ (1,0) [0|1] "" ZR_High,ZR_LIMU,ZR_MIB_TOP_ab_Gen3,ZR_Standard
 SG_ SI_BUS_14 : 29|1@1+ (1,0) [0|1] "" ZR_High,ZR_LIMU,ZR_MIB_TOP_ab_Gen3,ZR_Standard
 SG_ SI_BUS_15 : 30|1@1+ (1,0) [0|1] "" ZR_High,ZR_LIMU,ZR_MIB_TOP_ab_Gen3,ZR_Standard
 SG_ SI_Bus_Identifikation : 32|8@1+ (1,0) [0|255] "" OTA_FC,ZR_High,ZR_LIMU,ZR_MIB_TOP_ab_Gen3,ZR_Standard
 SG_ SI_CAB : 40|24@1+ (1,0) [0|16777215] "" BedienSG_hi,OTA_FC,ZR_High,ZR_LIMU,ZR_MIB_TOP_ab_Gen3,ZR_Standard

BO_ 1420 Terminals_Control_01: 8 Gateway
 SG_ Terminals_Control_01_CRC : 0|8@1+ (1,0) [0|255] "" Vector__XXX
 SG_ Terminals_Control_01_BZ : 8|4@1+ (1,0) [0|15] "" Vector__XXX
 SG_ KST_Txt_P_Gear : 16|1@1+ (1,0) [0|1] "" Vector__XXX
 SG_ KST_Txt_PanicShutdown : 17|1@1+ (1,0) [0|1] "" Vector__XXX
 SG_ KST_Req_TerminalsEnable_ELV : 18|1@1+ (1,0) [0|1] "" Vector__XXX
 SG_ KST_Txt_ComfortShutdown : 19|1@1+ (1,0) [0|1] "" Vector__XXX
 SG_ KST_ZAT_Pressed : 20|1@1+ (1,0) [0|1] "" ZR_High
 SG_ KST_Unterdr_IgnitionReport : 21|1@1+ (1,0) [0|1] "" Vector__XXX
 SG_ KST_aut_Shutdown_Ignition : 22|1@1+ (1,0) [0|1] "" Vector__XXX
 SG_ KST_Req_ZV_Locking : 24|1@1+ (1,0) [0|1] "" Vector__XXX
 SG_ Relay_VoKo_Actuated : 25|1@1+ (1,0) [0|1] "" Vector__XXX
 SG_ RSt_Request_HMS : 26|3@1+ (1,0) [0|7] "" Vector__XXX

BO_ 1426 Kessy_04: 8 XXX

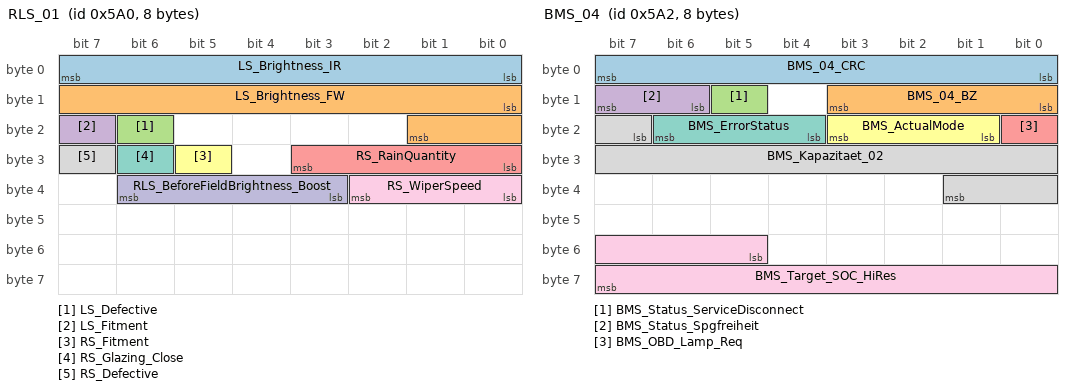
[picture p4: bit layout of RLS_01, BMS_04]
BO_ 1440 RLS_01: 8 Gateway
 SG_ LS_Brightness_IR : 0|8@1+ (400,0) [0|101200] "Unit_Lux" ZR_High
 SG_ LS_Brightness_FW : 8|10@1+ (6,0) [0|6126] "Unit_Lux" ZR_High
 SG_ LS_Defective : 22|1@1+ (1,0) [0|1] "" ZR_High
 SG_ LS_Fitment : 23|1@1+ (1,0) [0|1] "" ZR_High
 SG_ RS_RainQuantity : 24|4@1+ (10,0) [0|100] "Unit_PerCent" OTA_FC,ZR_High
 SG_ RS_Fitment : 29|1@1+ (1,0) [0|1] "" ZR_High
 SG_ RS_Glazing_Close : 30|1@1+ (1,0) [0|1] "" ZR_High
 SG_ RS_Defective : 31|1@1+ (1,0) [0|1] "" ZR_High
 SG_ RS_WiperSpeed : 32|3@1+ (1,0) [0|7] "" OTA_FC,ZR_High
 SG_ RLS_BeforeFieldBrightness_Boost : 35|4@1+ (1,0) [0|15] "" ZR_High

BO_ 1442 BMS_04: 8 BMC_MLBevo
 SG_ BMS_04_CRC : 0|8@1+ (1,0) [0|255] "" Gateway,Gateway_PAG,Sub_Gateway
 SG_ BMS_04_BZ : 8|4@1+ (1,0) [0|15] "" Gateway,Gateway_PAG,Sub_Gateway
 SG_ BMS_Status_ServiceDisconnect : 13|1@1+ (1,0) [0|1] "" DCDC_800V_PAG,DCDC_HV,Gateway,Gateway_PAG,Sub_Gateway
 SG_ BMS_Status_Spgfreiheit : 14|2@1+ (1,0) [0|3] "" Gateway,Gateway_PAG,Sub_Gateway
 SG_ BMS_OBD_Lamp_Req : 16|1@1+ (1,0) [0|1] "" Gateway,Gateway_PAG,Sub_Gateway
 SG_ BMS_ActualMode : 17|3@1+ (1,0) [0|7] "" AWC,Gateway,Gateway_PAG,Ladegeraet_Konzern,LE1,LE2,LE2_3_MLBevo_LB,Sub_Gateway,TME
 SG_ BMS_ErrorStatus : 20|3@1+ (1,0) [0|7] "" AWC,DCDC_800V_PAG,DCDC_HV,Gateway,Gateway_PAG,Ladegeraet_Konzern,Sub_Gateway
 SG_ BMS_Kapazitaet_02 : 23|11@1+ (0.2,0) [0|409.2] "Unit_AmperHour" Gateway,Gateway_PAG,Ladegeraet_Konzern,Sub_Gateway
 SG_ BMS_Target_SOC_HiRes : 53|11@1+ (0.05,0) [0|100] "Unit_PerCent" Gateway,Gateway_PAG,Sub_Gateway

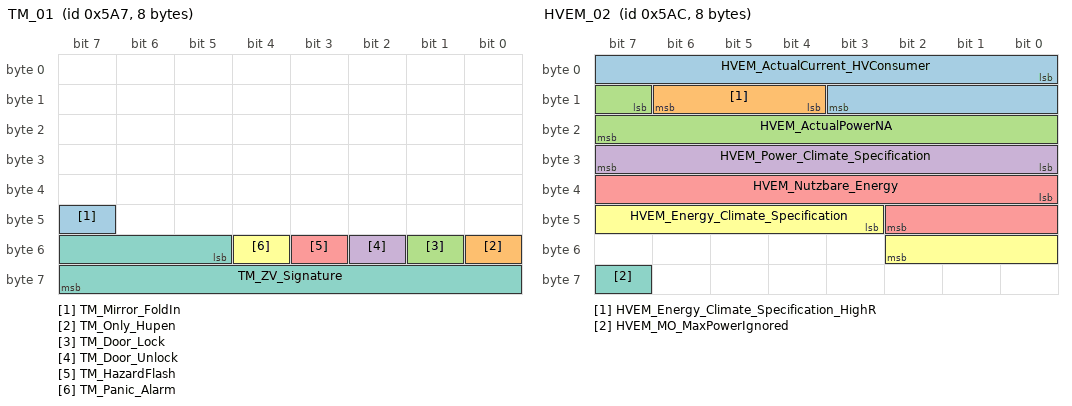
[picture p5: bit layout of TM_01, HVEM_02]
BO_ 1447 TM_01: 8 Gateway
 SG_ TM_Mirror_FoldIn : 47|1@1+ (1,0) [0|1] "" ZR_High
 SG_ TM_Only_Hupen : 48|1@1+ (1,0) [0|1] "" ZR_High
 SG_ TM_Door_Lock : 49|1@1+ (1,0) [0|1] "" Vector__XXX
 SG_ TM_Door_Unlock : 50|1@1+ (1,0) [0|1] "" Vector__XXX
 SG_ TM_HazardFlash : 51|1@1+ (1,0) [0|1] "" ZR_High
 SG_ TM_Panic_Alarm : 52|1@1+ (1,0) [0|1] "" ZR_High
 SG_ TM_ZV_Signature : 53|11@1+ (1,0) [1|2047] "Unit_None" Vector__XXX

BO_ 1452 HVEM_02: 8 Gateway
 SG_ HVEM_ActualCurrent_HVConsumer : 0|12@1+ (0.1,-204.7) [-204.7|204.6] "Unit_Amper" Vector__XXX
 SG_ HVEM_Energy_Climate_Specification_HighR : 12|3@1+ (10,0) [0|50] "Unit_WattHour" TME
 SG_ HVEM_ActualPowerNA : 15|9@1+ (50,0) [0|25450] "Unit_Watt" Vector__XXX
 SG_ HVEM_Power_Climate_Specification : 24|8@1+ (50,0) [0|12650] "Unit_Watt" TME
 SG_ HVEM_Nutzbare_Energy : 32|11@1+ (50,0) [0|102200] "Unit_WattHour" Ladegeraet_Konzern
 SG_ HVEM_Energy_Climate_Specification : 43|8@1+ (50,0) [0|12650] "Unit_WattHour" TME
 SG_ HVEM_MO_MaxPowerIgnored : 63|1@1+ (1,0) [0|1] "" Vector__XXX

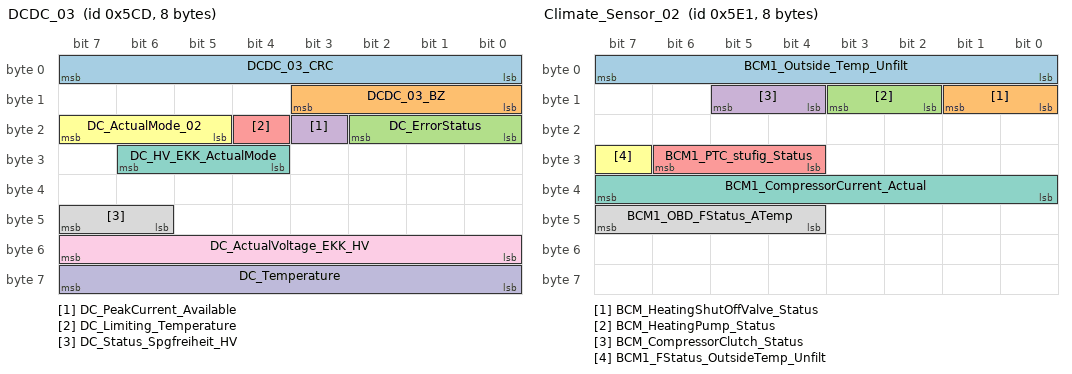
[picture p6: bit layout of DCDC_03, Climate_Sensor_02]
BO_ 1485 DCDC_03: 8 DCDC_800V_PAG
 SG_ DCDC_03_CRC : 0|8@1+ (1,0) [0|255] "" Gateway,Gateway_PAG,Sub_Gateway
 SG_ DCDC_03_BZ : 8|4@1+ (1,0) [0|15] "" Gateway,Gateway_PAG,Sub_Gateway
 SG_ DC_ErrorStatus : 16|3@1+ (1,0) [0|7] "" Gateway,Gateway_PAG,Sub_Gateway
 SG_ DC_PeakCurrent_Available : 19|1@1+ (1,0) [0|1] "" Gateway,Gateway_PAG,Sub_Gateway
 SG_ DC_Limiting_Temperature : 20|1@1+ (1,0) [0|1] "" Gateway_PAG,Sub_Gateway,TME
 SG_ DC_ActualMode_02 : 21|3@1+ (1,0) [0|7] "" DCDC_HV_02,Gateway,Gateway_PAG,Ladegeraet_Konzern,Sub_Gateway,TME
 SG_ DC_HV_EKK_ActualMode : 28|3@1+ (1,0) [0|7] "" Gateway,Gateway_PAG,Sub_Gateway,TME
 SG_ DC_Status_Spgfreiheit_HV : 46|2@1+ (1,0) [0|3] "" Gateway,Gateway_PAG,Sub_Gateway
 SG_ DC_ActualVoltage_EKK_HV : 48|8@1+ (2,0) [0|508] "Unit_Volt" Gateway,Gateway_PAG,Sub_Gateway
 SG_ DC_Temperature : 56|8@1+ (1,-40) [-40|213] "Unit_DegreCelsi" Gateway,Gateway_PAG,Sub_Gateway,TME

BO_ 1505 Climate_Sensor_02: 8 Gateway
 SG_ BCM1_Outside_Temp_Unfilt : 0|8@1+ (0.5,-50) [-50|76] "Unit_DegreCelsi" BMC_MLBevo,BMS_NV,FCU_MLBevo_FCEV,Ladegeraet_Konzern,TME
 SG_ BCM_HeatingShutOffValve_Status : 8|2@1+ (1,0) [0|3] "" Vector__XXX
 SG_ BCM_HeatingPump_Status : 10|2@1+ (1,0) [0|3] "" Vector__XXX
 SG_ BCM_CompressorClutch_Status : 12|2@1+ (1,0) [0|3] "" Vector__XXX
 SG_ BCM1_PTC_stufig_Status : 28|3@1+ (1,0) [0|7] "" Vector__XXX
 SG_ BCM1_FStatus_OutsideTemp_Unfilt : 31|1@1+ (1,0) [0|1] "" TME
 SG_ BCM1_CompressorCurrent_Actual : 32|8@1+ (4,0) [0|1000] "Unit_MilliAmper" Vector__XXX
 SG_ BCM1_OBD_FStatus_ATemp : 44|4@1+ (1,0) [0|15] "" BMC_MLBevo,Ladegeraet_Konzern,TME

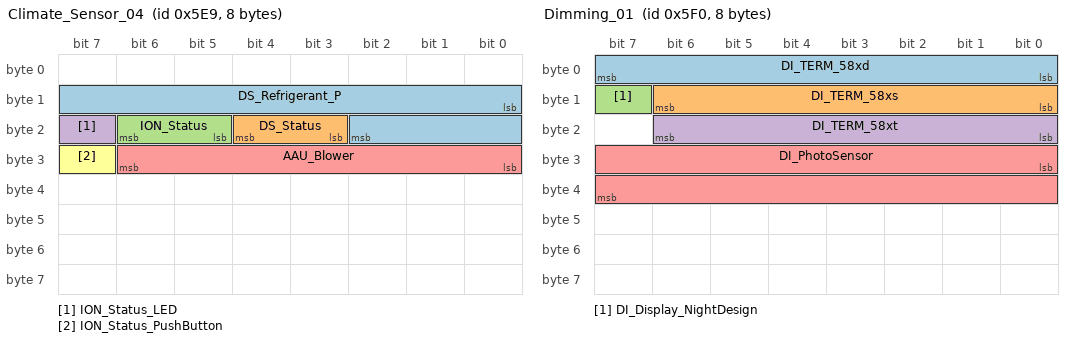
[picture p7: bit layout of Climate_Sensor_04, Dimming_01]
BO_ 1513 Climate_Sensor_04: 8 Gateway
 SG_ DS_Refrigerant_P : 8|11@1+ (0.0161,0) [0|32.9245] "Unit_Bar" TME
 SG_ DS_Status : 19|2@1+ (1,0) [0|3] "" TME
 SG_ ION_Status : 21|2@1+ (1,0) [0|3] "" Vector__XXX
 SG_ ION_Status_LED : 23|1@1+ (1,0) [0|1] "" Vector__XXX
 SG_ AAU_Blower : 24|7@1+ (1,0) [0|100] "Unit_PerCent" Vector__XXX
 SG_ ION_Status_PushButton : 31|1@1+ (1,0) [0|1] "" Vector__XXX

BO_ 1520 Dimming_01: 8 Gateway_MQB
 SG_ DI_TERM_58xd : 0|8@1+ (1,0) [0|253] "" Airbag_MQB
 SG_ DI_TERM_58xs : 8|7@1+ (1,0) [0|100] "Unit_PerCent" Vector__XXX
 SG_ DI_Display_NightDesign : 15|1@1+ (1,0) [0|1] "" Vector__XXX
 SG_ DI_TERM_58xt : 16|7@1+ (1,0) [0|100] "Unit_PerCent" Vector__XXX
 SG_ DI_PhotoSensor : 24|16@1+ (1,0) [0|65535] "" Vector__XXX

BO_ 1524 InsideLight_11: 8 Gateway
 SG_ IL_Dimming_V_Tuerkontur : 0|8@1+ (1,0) [0|100] "Unit_PerCent" ZR_High
 SG_ IL_Dimming_H_Tuerkontur : 8|8@1+ (1,0) [0|100] "Unit_PerCent" ZR_High
 SG_ IL_Dimming_DoorInsideHandle : 16|8@1+ (1,0) [0|100] "Unit_PerCent" ZR_High
 SG_ IL_Dimming_Umfeldbel : 24|8@1+ (1,0) [0|100] "Unit_PerCent" ZR_High
 SG_ IL_Bel_FS_Exit : 32|1@1+ (1,0) [0|1] "" ZR_High
 SG_ IL_Bel_BFS_Exit : 33|1@1+ (1,0) [0|1] "" ZR_High
 SG_ IL_Bel_HFS_Exit : 34|1@1+ (1,0) [0|1] "" ZR_High
 SG_ IL_Bel_HBFS_Exit : 35|1@1+ (1,0) [0|1] "" ZR_High
 SG_ BCM1_InsideLight_gedimmt_V : 36|1@1+ (1,0) [0|1] "" ZR_High
 SG_ BCM1_InsideLight_gedimmt_H : 37|1@1+ (1,0) [0|1] "" ZR_High
 SG_ IL_InsideLight_Active : 38|1@1+ (1,0) [0|1] "" ZR_High
 SG_ IL_Terminal_30G_Active : 39|1@1+ (1,0) [0|1] "" Vector__XXX
 SG_ BCM1_DI_Ramp_InsideLight : 40|1@1+ (1,0) [0|1] "" ZR_High
 SG_ BCM1_DI_Ramp_ReadingLight : 41|1@1+ (1,0) [0|1] "" ZR_High
 SG_ BCM1_InsideLight_H : 42|1@1+ (1,0) [0|1] "" ZR_High
 SG_ BCM1_InsideLight_V : 43|1@1+ (1,0) [0|1] "" ZR_High
 SG_ BCM1_ReadingLight_Req_hl : 44|1@1+ (1,0) [0|1] "" ZR_High
 SG_ BCM1_ReadingLight_Req_hr : 45|1@1+ (1,0) [0|1] "" ZR_High
 SG_ BCM1_ReadingLight_Req_vl : 46|1@1+ (1,0) [0|1] "" ZR_High
 SG_ BCM1_ReadingLight_Req_vr : 47|1@1+ (1,0) [0|1] "" ZR_High
 SG_ BCM1_Leuchten_Off : 48|1@1+ (1,0) [0|1] "" ZR_High
 SG_ AMB_Charisma_DrivePr : 49|4@1+ (1,0) [0|15] "" Vector__XXX
 SG_ AMB_Charisma_Status : 53|2@1+ (1,0) [0|3] "" Vector__XXX
 SG_ IL_Dimming_Lautspr : 56|8@1+ (1,0) [0|100] "Unit_PerCent" ZR_High

BO_ 1600 Engine_07: 8 Motor_Diesel_MQB
 SG_ MO_QBit_IntakeAir_Temp : 0|1@1+ (1,0) [0|1] "" Gateway_MQB
 SG_ MO_QBit_Oil_Temp : 1|1@1+ (1,0) [0|1] "" Gateway_MQB,Getriebe_DQ_Hybrid_MQB,Getriebe_DQ_MQB
 SG_ MO_QBit_Coolant_Temp : 2|1@1+ (1,0) [0|1] "" Gateway_MQB,Getriebe_DQ_Hybrid_MQB,Getriebe_DQ_MQB,LEH_MQB
 SG_ MO_ActuatorTest_SoundActuator : 3|1@1+ (1,0) [0|1] "" Gateway_MQB
 SG_ MO_HYB_Error_HV_Network : 4|1@1+ (1,0) [0|1] "" Gateway_MQB
 SG_ MO_Active_GearboxHeat : 5|1@1+ (1,0) [0|1] "" Gateway_MQB,Getriebe_DQ_Hybrid_MQB,Getriebe_DQ_MQB
 SG_ MO_ShutOffValve_Open : 6|2@1+ (1,0) [0|3] "" Gateway_MQB
 SG_ MO_IntakeAir_Temp : 8|8@1+ (0.75,-48) [-48|141.75] "Unit_DegreCelsi" Gateway_MQB
 SG_ MO_Oil_Temp : 16|8@1+ (1,-60) [-60|192] "Unit_DegreCelsi" Gateway_MQB,Getriebe_DQ_Hybrid_MQB,Getriebe_DQ_MQB
 SG_ MO_Coolant_Temp : 24|8@1+ (0.75,-48) [-48|141.75] "Unit_DegreCelsi" Gateway_MQB,Getriebe_DQ_Hybrid_MQB,Getriebe_DQ_MQB,LEH_MQB
 SG_ MO_AltitudeInfo : 32|8@1+ (0.00781,0) [0|1.98374] "" Gateway_MQB,Getriebe_DQ_Hybrid_MQB,Getriebe_DQ_MQB
 SG_ MO_Kennfeldk : 40|1@1+ (1,0) [0|1] "" Gateway_MQB
 SG_ MO_VersionInfo : 41|6@1+ (1,0) [0|63] "" Gateway_MQB
 SG_ MO_Gearbox_Cool : 47|1@1+ (1,0) [0|1] "" Gateway_MQB,Getriebe_DQ_Hybrid_MQB,Getriebe_DQ_MQB
 SG_ MO_Torque_Inertia_02 : 48|5@1+ (0.01,0) [0|0.31] "Unit_KiloGramMeterSquar" Gateway_MQB,Getriebe_DQ_Hybrid_MQB,Getriebe_DQ_MQB
 SG_ MO_HeatingPumpActuation : 53|4@1+ (10,0) [0|100] "Unit_PerCent" Gateway_MQB
 SG_ MO_VoltageReq : 57|1@1+ (1,0) [0|1] "" Gateway_MQB
 SG_ MO_RunOnTime_HeatingPump : 58|6@1+ (15,0) [0|945] "Unit_Secon" Gateway_MQB

BO_ 1601 Engine_Code_01: 8 Motor_Diesel_MQB
 SG_ Engine_Code_01_CRC : 0|8@1+ (1,0) [0|255] "" Gateway_MQB
 SG_ Engine_Code_01_BZ : 8|4@1+ (1,0) [0|15] "" Gateway_MQB
 SG_ MO_Factor_Torques_02 : 12|2@1+ (1,0) [0|3] "" Gateway_MQB,Getriebe_DQ_Hybrid_MQB,Getriebe_DQ_MQB
 SG_ MO_HybridVehicle : 14|2@1+ (1,0) [0|3] "" Gateway_MQB
 SG_ MO_Code : 16|8@1+ (1,0) [0|255] "" Gateway_MQB,SAK_MQB
 SG_ MO_Gearbox_Code : 24|6@1+ (1,0) [0|63] "" Gateway_MQB
 SG_ MO_StartStop_Coded : 30|1@1+ (1,0) [0|1] "" Gateway_MQB
 SG_ MO_Count_Cyl : 32|4@1+ (1,0) [0|15] "" Gateway_MQB
 SG_ MO_FuelType : 36|4@1+ (1,0) [0|15] "" Gateway_MQB,Getriebe_DQ_Hybrid_MQB,Getriebe_DQ_MQB
 SG_ MO_Displacement : 40|7@1+ (0.1,0) [0|12.7] "Unit_Liter" Gateway_MQB
 SG_ MO_IntakeSystem : 47|1@1+ (1,0) [0|1] "" Gateway_MQB
 SG_ MO_Power : 48|9@1+ (1,0) [0|511] "Unit_KiloWatt" Gateway_MQB
 SG_ MO_ExhaustType_EOBD : 57|1@1+ (1,0) [0|1] "" BMS_MQB,Gateway_MQB,LEH_MQB
 SG_ MO_ExhaustType_OBD : 58|1@1+ (1,0) [0|1] "" BMS_MQB,Gateway_MQB,LEH_MQB
 SG_ MO_DPF_Fitted : 59|1@1+ (1,0) [0|1] "" Gateway_MQB
 SG_ TSK_Coding : 60|3@1+ (1,0) [0|7] "" Gateway_MQB,Getriebe_DQ_Hybrid_MQB,Getriebe_DQ_MQB
 SG_ MO_InjectionType : 63|1@1+ (1,0) [0|1] "" Gateway_MQB

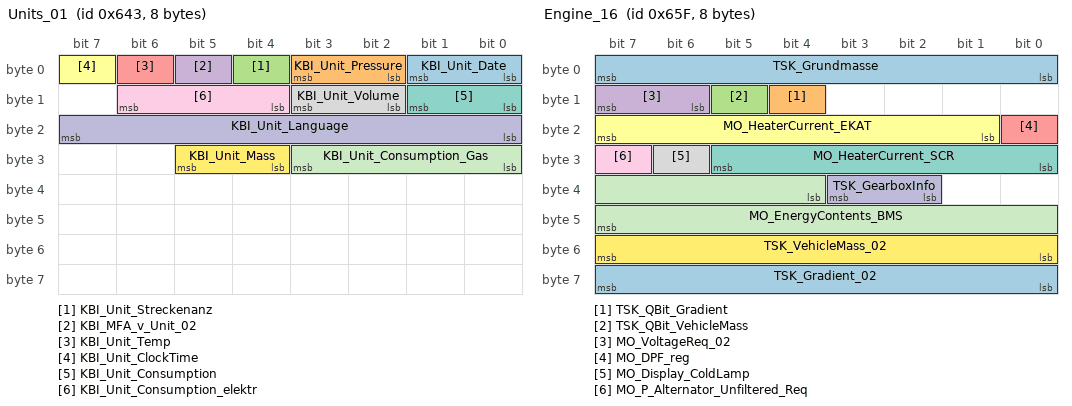
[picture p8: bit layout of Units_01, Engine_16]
BO_ 1603 Units_01: 8 Gateway
 SG_ KBI_Unit_Date : 0|2@1+ (1,0) [0|3] "" Vector__XXX
 SG_ KBI_Unit_Pressure : 2|2@1+ (1,0) [0|3] "" Vector__XXX
 SG_ KBI_Unit_Streckenanz : 4|1@1+ (1,0) [0|1] "" Ladegeraet_Konzern
 SG_ KBI_MFA_v_Unit_02 : 5|1@1+ (1,0) [0|1] "" Vector__XXX
 SG_ KBI_Unit_Temp : 6|1@1+ (1,0) [0|1] "" TME
 SG_ KBI_Unit_ClockTime : 7|1@1+ (1,0) [0|1] "" Ladegeraet_Konzern
 SG_ KBI_Unit_Consumption : 8|2@1+ (1,0) [0|3] "" Vector__XXX
 SG_ KBI_Unit_Volume : 10|2@1+ (1,0) [0|3] "" Vector__XXX
 SG_ KBI_Unit_Consumption_elektr : 12|3@1+ (1,0) [0|7] "" Vector__XXX
 SG_ KBI_Unit_Language : 16|8@1+ (1,0) [0|255] "" Vector__XXX
 SG_ KBI_Unit_Consumption_Gas : 24|4@1+ (1,0) [0|15] "" Vector__XXX
 SG_ KBI_Unit_Mass : 28|2@1+ (1,0) [0|3] "" Vector__XXX

BO_ 1622 ELV_01: 8 Gateway
 SG_ ELV_01_CRC : 0|8@1+ (1,0) [0|255] "" Vector__XXX
 SG_ ELV_01_BZ : 8|4@1+ (1,0) [0|15] "" Vector__XXX
 SG_ ELV_Req_Terminal_S : 12|1@1+ (1,0) [0|1] "" Vector__XXX
 SG_ ELV_Req_Terminal_15 : 13|1@1+ (1,0) [0|1] "" Vector__XXX
 SG_ ELV_Req_Terminal_50 : 14|1@1+ (1,0) [0|1] "" Vector__XXX
 SG_ ELV_01_SendStatus : 15|1@1+ (1,0) [0|1] "" Vector__XXX
 SG_ ELV_Locked : 16|1@1+ (1,0) [0|1] "" ZR_High
 SG_ ELV_Unlocked : 17|1@1+ (1,0) [0|1] "" ZR_High
 SG_ ELV_ZAT_Pressed : 18|1@1+ (1,0) [0|1] "" Vector__XXX
 SG_ ELV_LifeState : 19|1@1+ (1,0) [0|1] "" Vector__XXX
 SG_ ELV_Anlernmodus : 20|1@1+ (1,0) [0|1] "" Vector__XXX
 SG_ ELV_TerminalsEnable : 22|1@1+ (1,0) [0|1] "" Vector__XXX
 SG_ ELV_Abort_Req_TerminalsEnable : 23|1@1+ (1,0) [0|1] "" Vector__XXX
 SG_ ELV_LED_Red : 24|1@1+ (1,0) [0|1] "" ZR_High
 SG_ ELV_LED_Yellow : 25|1@1+ (1,0) [0|1] "" Vector__XXX
 SG_ ELV_Txt_PanicShutdown : 27|1@1+ (1,0) [0|1] "" Vector__XXX
 SG_ ELV_Txt_Lkg_Bewegen : 28|1@1+ (1,0) [0|1] "" ZR_High
 SG_ ELV_Txt_Workshop : 29|1@1+ (1,0) [0|1] "" ZR_High
 SG_ ELV_Txt_Defective : 30|1@1+ (1,0) [0|1] "" ZR_High
 SG_ ELV_Txt_P_Gear : 31|1@1+ (1,0) [0|1] "" Vector__XXX
 SG_ ELV_Txt_PN_Gear : 32|1@1+ (1,0) [0|1] "" Vector__XXX
 SG_ ELV_Txt_Clutch : 33|1@1+ (1,0) [0|1] "" Vector__XXX
 SG_ ELV_Txt_Brake : 34|1@1+ (1,0) [0|1] "" Vector__XXX
 SG_ ELV_P_Locked : 35|1@1+ (1,0) [0|1] "" Vector__XXX

BO_ 1624 Light_Front_01: 8 Gateway
 SG_ Light_Front_01_CRC : 0|8@1+ (1,0) [0|255] "" Vector__XXX
 SG_ Light_Front_01_BZ : 8|4@1+ (1,0) [0|15] "" Vector__XXX
 SG_ LV_SideLight_Display : 12|1@1+ (1,0) [0|1] "" OTA_FC,ZR_High
 SG_ LV_LowBeam_Display : 13|1@1+ (1,0) [0|1] "" OTA_FC,ZR_High
 SG_ LV_HighBeam_Display : 14|1@1+ (1,0) [0|1] "" OTA_FC,ZR_High
 SG_ LV_FogLight_Display : 15|1@1+ (1,0) [0|1] "" OTA_FC,ZR_High
 SG_ LV_RearFogLight_Display : 16|1@1+ (1,0) [0|1] "" OTA_FC,ZR_High
 SG_ LV_DaytimeRunningLight_Display : 17|1@1+ (1,0) [0|1] "" BedienSG_hi,OTA_FC,ZR_High
 SG_ LV_AFL_Active_Display : 18|1@1+ (1,0) [0|1] "" BedienSG_hi,OTA_FC,ZR_High
 SG_ LV_AFL_Defective : 19|1@1+ (1,0) [0|1] "" ZR_High
 SG_ LV_Indicator_Left_def : 20|1@1+ (1,0) [0|1] "" ZR_High
 SG_ LV_SideLight_Left_def : 21|1@1+ (1,0) [0|1] "" ZR_High
 SG_ LV_LowBeam_Left_def : 22|1@1+ (1,0) [0|1] "" ZR_High
 SG_ LV_HighBeam_Left_def : 23|1@1+ (1,0) [0|1] "" ZR_High
 SG_ LV_FogLight_Left_def : 24|1@1+ (1,0) [0|1] "" ZR_High
 SG_ LV_Blk_Left_Side_def : 25|1@1+ (1,0) [0|1] "" ZR_High
 SG_ LV_DaytimeRunningLight_Left_def : 26|1@1+ (1,0) [0|1] "" ZR_High
 SG_ LV_FLA_Active_Display : 27|1@1+ (1,0) [0|1] "" OTA_FC,ZR_High
 SG_ LV_FLA_Defective : 28|1@1+ (1,0) [0|1] "" ZR_High
 SG_ LV_FLA_Sensor_Blocked : 29|1@1+ (1,0) [0|1] "" OTA_FC,ZR_High
 SG_ LV_Indicator_Right_def : 30|1@1+ (1,0) [0|1] "" ZR_High
 SG_ LV_SideLight_Right_def : 31|1@1+ (1,0) [0|1] "" ZR_High
 SG_ LV_LowBeam_Right_def : 32|1@1+ (1,0) [0|1] "" ZR_High
 SG_ LV_HighBeam_Right_def : 33|1@1+ (1,0) [0|1] "" ZR_High
 SG_ LV_FogLight_Right_def : 34|1@1+ (1,0) [0|1] "" ZR_High
 SG_ LV_Blk_Right_Side_def : 35|1@1+ (1,0) [0|1] "" ZR_High
 SG_ LV_DaytimeRunningLight_Right_def : 36|1@1+ (1,0) [0|1] "" ZR_High
 SG_ LV_OutsideLight_def : 37|1@1+ (1,0) [0|1] "" ZR_High
 SG_ LV_LowBeam_TFL_Left_def : 38|1@1+ (1,0) [0|1] "" ZR_High
 SG_ LV_FogLight_TFL_Left_def : 39|1@1+ (1,0) [0|1] "" ZR_High
 SG_ LV_SideLight_TFL_Left_def : 40|1@1+ (1,0) [0|1] "" ZR_High
 SG_ LV_Abblend_HighBeam_Left_def : 41|1@1+ (1,0) [0|1] "" ZR_High
 SG_ LV_LowBeam_TFL_Right_def : 42|1@1+ (1,0) [0|1] "" ZR_High
 SG_ LV_FogLight_TFL_Right_def : 43|1@1+ (1,0) [0|1] "" ZR_High
 SG_ LV_SideLight_TFL_Right_def : 44|1@1+ (1,0) [0|1] "" ZR_High
 SG_ LV_Abblend_HighBeam_Right_def : 45|1@1+ (1,0) [0|1] "" ZR_High
 SG_ LV_TurnLight_Left_def : 46|1@1+ (1,0) [0|1] "" Vector__XXX
 SG_ LV_TurnLight_Right_def : 47|1@1+ (1,0) [0|1] "" Vector__XXX
 SG_ BCM1_LeftHandTraffic : 48|1@1+ (1,0) [0|1] "" OTA_FC,ZR_High
 SG_ BCM1_Light_Darkness_Active : 49|1@1+ (1,0) [0|1] "" OTA_FC,ZR_High
 SG_ LV_LED_Scheinwerfer_Left_def : 50|1@1+ (1,0) [0|1] "" Vector__XXX
 SG_ LV_LED_Scheinwerfer_Right_def : 51|1@1+ (1,0) [0|1] "" Vector__XXX
 SG_ LV_Indicator_VL_Active : 52|1@1+ (1,0) [0|1] "" OTA_FC,ZR_High
 SG_ LV_Indicator_VR_Active : 53|1@1+ (1,0) [0|1] "" OTA_FC,ZR_High
 SG_ LV_MXB_Status_Display : 54|2@1+ (1,0) [0|3] "" Vector__XXX

BO_ 1629 ESP_20: 8 Gateway
 SG_ ESP_20_CRC : 0|8@1+ (1,0) [0|255] "" Vector__XXX
 SG_ ESP_20_BZ : 8|4@1+ (1,0) [0|15] "" Vector__XXX
 SG_ BR_SystemType : 12|2@1+ (1,0) [0|3] "" Vector__XXX
 SG_ ESP_VoltageReq_02 : 14|2@1+ (1,0) [0|3] "" Vector__XXX
 SG_ ESP_ToothCount : 16|8@1+ (1,0) [0|255] "" Vector__XXX
 SG_ ESP_Charisma_DrivePr : 24|4@1+ (1,0) [0|15] "" Vector__XXX
 SG_ ESP_Charisma_Status : 28|2@1+ (1,0) [0|3] "" Vector__XXX
 SG_ ESP_Restart_Disp_01 : 30|1@1+ (1,0) [0|1] "" Vector__XXX
 SG_ ESP_Restart_Disp_02 : 31|1@1+ (1,0) [0|1] "" Vector__XXX
 SG_ ESP_Restart_Disp_03 : 32|1@1+ (1,0) [0|1] "" Vector__XXX
 SG_ ESP_Restart_Disp_04 : 33|1@1+ (1,0) [0|1] "" Vector__XXX
 SG_ ESP_StopInhibit_Disp_01 : 34|1@1+ (1,0) [0|1] "" Vector__XXX
 SG_ ESP_StopInhibit_Disp_02 : 35|1@1+ (1,0) [0|1] "" Vector__XXX
 SG_ ESP_StopInhibit_Disp_03 : 36|1@1+ (1,0) [0|1] "" Vector__XXX
 SG_ ESP_StopInhibit_Disp_04 : 37|1@1+ (1,0) [0|1] "" Vector__XXX
 SG_ ESP_StopInhibit_Disp_05 : 38|1@1+ (1,0) [0|1] "" Vector__XXX
 SG_ ESP_StopInhibit_Disp_06 : 39|1@1+ (1,0) [0|1] "" Vector__XXX
 SG_ ESP_StopInhibit_Disp_07 : 40|1@1+ (1,0) [0|1] "" Vector__XXX
 SG_ ESP_StopInhibit_Disp_Std : 41|1@1+ (1,0) [0|1] "" Vector__XXX
 SG_ ESP_Dachrelingsensor : 42|2@1+ (1,0) [0|3] "" Vector__XXX
 SG_ ESP_StopInhibit_Disp_08 : 44|1@1+ (1,0) [0|1] "" Vector__XXX
 SG_ HDC_Charisma_DrivePr : 45|4@1+ (1,0) [0|15] "" Vector__XXX
 SG_ HDC_Charisma_Status : 49|2@1+ (1,0) [0|3] "" Vector__XXX
 SG_ BR_QBit_TyreCircumference : 51|1@1+ (1,0) [0|1] "" AWC
 SG_ BR_TyreCircumference : 52|12@1+ (1,0) [0|4095] "Unit_MilliMeter" AWC

BO_ 1631 Engine_16: 8 Gateway
 SG_ TSK_Grundmasse : 0|8@1+ (32,0) [0|8128] "Unit_KiloGram" ZR_High
 SG_ TSK_QBit_Gradient : 12|1@1+ (1,0) [0|1] "" Vector__XXX
 SG_ TSK_QBit_VehicleMass : 13|1@1+ (1,0) [0|1] "" ZR_High
 SG_ MO_VoltageReq_02 : 14|2@1+ (1,0) [0|3] "" Vector__XXX
 SG_ MO_DPF_reg : 16|1@1+ (1,0) [0|1] "" ZR_High
 SG_ MO_HeaterCurrent_EKAT : 17|7@1+ (1,0) [0|126] "Unit_Amper" Vector__XXX
 SG_ MO_HeaterCurrent_SCR : 24|6@1+ (1,0) [0|62] "Unit_Amper" Vector__XXX
 SG_ MO_Display_ColdLamp : 30|1@1+ (1,0) [0|1] "" Vector__XXX
 SG_ MO_P_Alternator_Unfiltered_Req : 31|1@1+ (1,0) [0|1] "" Vector__XXX
 SG_ TSK_GearboxInfo : 34|2@1+ (1,0) [0|3] "" Vector__XXX
 SG_ MO_EnergyContents_BMS : 36|12@1+ (25,0) [0|102325] "Unit_WattHour" Vector__XXX
 SG_ TSK_VehicleMass_02 : 48|8@1+ (32,0) [0|8128] "Unit_KiloGram" OTA_FC,ZR_High
 SG_ TSK_Gradient_02 : 56|8@1+ (0.8,-101.6) [-100.8|101.6] "Unit_PerCent" OTA_FC

BO_ 1640 Climate_12: 8 Gateway
 SG_ TERM_LRH_PushButton : 0|1@1+ (1,0) [0|1] "" Vector__XXX
 SG_ TERM_LRH_Stage : 1|2@1+ (1,0) [0|3] "" Vector__XXX
 SG_ HSH_PushButton : 3|2@1+ (1,0) [0|3] "" Vector__XXX
 SG_ FSH_PushButton : 5|1@1+ (1,0) [0|1] "" Vector__XXX
 SG_ TERM_AuxHeater_Enable : 6|1@1+ (1,0) [0|1] "" TME
 SG_ TERM_FoggingRisk : 7|1@1+ (1,0) [0|1] "" TME
 SG_ TERM_SIH_Target_Left : 8|3@1+ (1,0) [0|7] "" TME
 SG_ TERM_SIH_Target_Right : 11|3@1+ (1,0) [0|7] "" TME
 SG_ KRH_Target_Left : 14|2@1+ (1,0) [0|3] "" Vector__XXX
 SG_ TERM_SIL_Target_Left : 16|3@1+ (1,0) [0|7] "" TME
 SG_ TERM_SIL_Target_Right : 19|3@1+ (1,0) [0|7] "" TME
 SG_ KRH_Target_Right : 22|2@1+ (1,0) [0|3] "" Vector__XXX
 SG_ TERM_Geblspng_Target : 24|8@1+ (0.05,1.45) [1.5|14] "Unit_Volt" Vector__XXX
 SG_ TERM_Geblspng_Fond_Target : 32|8@1+ (0.05,1.45) [1.5|14] "Unit_Volt" Vector__XXX
 SG_ TERM_I_Blower : 40|8@1+ (0.25,0) [0|63.5] "Unit_Amper" Vector__XXX
 SG_ TERM_CompressorCurrent_Target : 48|10@1+ (1,0) [0|1021] "" TME
 SG_ TERM_RecirculationFlap_Status : 58|4@1+ (1,0) [0|15] "" TME
 SG_ TERM_PTC_FitmentInfo : 62|2@1+ (1,0) [0|3] "" Vector__XXX

BO_ 1648 Engine_18: 8 Gateway
 SG_ MO_max_BoostPressure : 0|6@1+ (0.1,0) [0|6.3] "Unit_Bar" Sub_Gateway
 SG_ MO_ANC_Map_Req : 6|2@1+ (1,0) [0|3] "" Sub_Gateway
 SG_ MO_BrakeLight_Recup : 8|1@1+ (1,0) [0|1] "" Sub_Gateway
 SG_ MO_StartStop_PopUp : 9|2@1+ (1,0) [0|3] "" Sub_Gateway
 SG_ MO1_Lock_Info_WFS : 11|1@1+ (1,0) [0|1] "" Sub_Gateway
 SG_ MO1_Enable_Info_WFS : 12|1@1+ (1,0) [0|1] "" Sub_Gateway
 SG_ MO_EPCL : 13|3@1+ (1,0) [0|7] "" Sub_Gateway
 SG_ MO_CylDeact_Texte_02 : 16|4@1+ (1,0) [0|15] "" Sub_Gateway
 SG_ MO_VehicleType : 20|3@1+ (1,0) [0|7] "" BMS_NV,Sub_Gateway
 SG_ MO_NMAX_ShiftDisplay : 23|9@1+ (25,0) [0|12775] "Unit_MinutInver" Sub_Gateway
 SG_ MO_ParkedTime : 32|8@1+ (8,0) [0|2024] "Unit_Minut" BMS_NV,Sub_Gateway,TME
 SG_ MO_ParkedTime_Status : 40|2@1+ (1,0) [0|3] "" BMS_NV,Sub_Gateway,TME
 SG_ MO1_Enable_ExpiryInfo_WFS : 42|1@1+ (1,0) [0|1] "" Sub_Gateway
 SG_ MO_Hybrid_StartStop_LED : 43|2@1+ (1,0) [0|3] "" Sub_Gateway
 SG_ MO_Error_CylDeact : 45|2@1+ (1,0) [0|3] "" Sub_Gateway
 SG_ MO_Count_Abgesch_Cyl : 47|3@1+ (1,0) [0|7] "" Sub_Gateway
 SG_ MO_CylDeact_Texte : 50|2@1+ (1,0) [0|3] "" Sub_Gateway
 SG_ MO_Ethanol_BS_Texte : 52|3@1+ (1,0) [0|7] "" Sub_Gateway
 SG_ MO_Rpm_Warning : 55|1@1+ (1,0) [0|1] "" Sub_Gateway
 SG_ MO_Upper_RpmLimit : 56|8@1+ (50,0) [50|12750] "Unit_MinutInver" Sub_Gateway

BO_ 1710 Mirror_01: 8 Gateway
 SG_ SP_FT_Top : 0|1@1+ (1,0) [0|1] "" OTA_FC,ZR_High
 SG_ SP_FT_Bottom : 1|1@1+ (1,0) [0|1] "" OTA_FC,ZR_High
 SG_ SP_FT_Left : 2|1@1+ (1,0) [0|1] "" OTA_FC,ZR_High
 SG_ SP_FT_Right : 3|1@1+ (1,0) [0|1] "" OTA_FC,ZR_High
 SG_ SP_BT_Top : 4|1@1+ (1,0) [0|1] "" OTA_FC,ZR_High
 SG_ SP_BT_Bottom : 5|1@1+ (1,0) [0|1] "" OTA_FC,ZR_High
 SG_ SP_BT_Left : 6|1@1+ (1,0) [0|1] "" OTA_FC,ZR_High
 SG_ SP_BT_Right : 7|1@1+ (1,0) [0|1] "" OTA_FC,ZR_High
 SG_ SP_FoldDown : 8|1@1+ (1,0) [0|1] "" OTA_FC,ZR_High
 SG_ SP_FoldIn : 9|1@1+ (1,0) [0|1] "" OTA_FC,ZR_High
 SG_ SP_normieren : 10|1@1+ (1,0) [0|1] "" OTA_FC,ZR_High
 SG_ SP_Hzg_PushButton : 12|1@1+ (1,0) [0|1] "" OTA_FC,ZR_High
 SG_ SP_S_Top : 16|1@1+ (1,0) [0|1] "" ZR_High
 SG_ SP_S_Bottom : 17|1@1+ (1,0) [0|1] "" ZR_High
 SG_ SP_S_Left : 18|1@1+ (1,0) [0|1] "" ZR_High
 SG_ SP_S_Right : 19|1@1+ (1,0) [0|1] "" ZR_High
 SG_ SP_Selection_Left : 20|1@1+ (1,0) [0|1] "" ZR_High
 SG_ SP_Selection_Right : 21|1@1+ (1,0) [0|1] "" ZR_High
 SG_ SP_ARA_Status : 22|1@1+ (1,0) [0|1] "" ZR_High
 SG_ SP_S_Fold : 23|1@1+ (1,0) [0|1] "" ZR_High
 SG_ SP_Verstellschalter_Error : 24|1@1+ (1,0) [0|1] "" ZR_High

BO_ 1711 Rear_View_01: 8 Gateway
 SG_ RV_Video_on : 0|1@1+ (1,0) [0|1] "" ZR_High,ZR_Standard
 SG_ RV_Dark_Screen : 1|1@1+ (1,0) [0|1] "" ZR_High,ZR_Standard
 SG_ RV_HMI_Mode : 2|2@1+ (1,0) [0|3] "" ZR_High,ZR_Standard
 SG_ RV_GL_side : 4|2@1+ (1,0) [0|3] "" ZR_High,ZR_Standard
 SG_ RV_System_Active : 6|1@1+ (1,0) [0|1] "" ZR_High,ZR_Standard
 SG_ RV_Reinigung_Req : 7|1@1+ (1,0) [0|1] "" OTA_FC,ZR_High
 SG_ RV_Settings_enabled : 8|1@1+ (1,0) [0|1] "" ZR_High
 SG_ RV_Menu_Item : 9|2@1+ (1,0) [0|3] "" ZR_High
 SG_ SV_Video_on : 11|1@1+ (1,0) [0|1] "" ZR_High,ZR_Standard
 SG_ RV_Calib_Error : 12|1@1+ (1,0) [0|1] "" ZR_High
 SG_ RV_GL_Trailer_connect : 13|1@1+ (1,0) [0|1] "" ZR_High,ZR_Standard
 SG_ RV_GL_Trunk_open : 14|1@1+ (1,0) [0|1] "" ZR_High,ZR_Standard
 SG_ RV_GL_LWS_Error : 15|1@1+ (1,0) [0|1] "" ZR_High
 SG_ RV_Brightness : 16|7@1+ (1,0) [0|100] "Unit_PerCent" ZR_High,ZR_Standard
 SG_ ZFAS_Umfeldbeleuchtung_Req : 23|1@1+ (1,0) [0|1] "" Vector__XXX
 SG_ RV_Kontrast : 24|7@1+ (1,0) [0|100] "Unit_PerCent" ZR_High,ZR_Standard
 SG_ RV_Colour : 32|7@1+ (1,0) [0|100] "Unit_PerCent" ZR_High,ZR_Standard

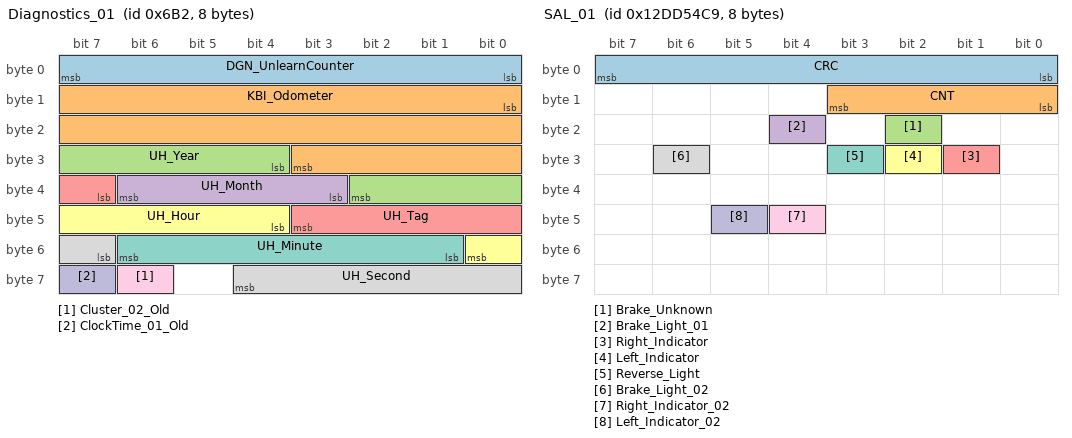
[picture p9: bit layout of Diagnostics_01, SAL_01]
BO_ 1714 Diagnostics_01: 8 Gateway_MQB
 SG_ DGN_UnlearnCounter : 0|8@1+ (1,0) [0|254] "" Airbag_MQB,BMS_MQB,Getriebe_DQ_Hybrid_MQB,Getriebe_DQ_MQB,LEH_MQB,SAK_MQB
 SG_ KBI_Odometer : 8|20@1+ (1,0) [0|1048573] "Unit_KiloMeter" Airbag_MQB,BMS_MQB,Getriebe_DQ_Hybrid_MQB,Getriebe_DQ_MQB,LEH_MQB,Motor_Diesel_MQB,Motor_Hybrid_MQB,Motor_Otto_MQB,SAK_MQB
 SG_ UH_Year : 28|7@1+ (1,2000) [2000|2127] "Unit_Year" Airbag_MQB,BMS_MQB,Getriebe_DQ_Hybrid_MQB,Getriebe_DQ_MQB,LEH_MQB,Motor_Diesel_MQB,Motor_Hybrid_MQB,Motor_Otto_MQB,SAK_MQB
 SG_ UH_Month : 35|4@1+ (1,0) [1|12] "Unit_Month" Airbag_MQB,BMS_MQB,Getriebe_DQ_Hybrid_MQB,Getriebe_DQ_MQB,LEH_MQB,Motor_Diesel_MQB,Motor_Hybrid_MQB,Motor_Otto_MQB,SAK_MQB
 SG_ UH_Tag : 39|5@1+ (1,0) [1|31] "Unit_Day" Airbag_MQB,BMS_MQB,Getriebe_DQ_Hybrid_MQB,Getriebe_DQ_MQB,LEH_MQB,Motor_Diesel_MQB,Motor_Hybrid_MQB,Motor_Otto_MQB,SAK_MQB
 SG_ UH_Hour : 44|5@1+ (1,0) [0|23] "Unit_Hours" Airbag_MQB,BMS_MQB,Getriebe_DQ_Hybrid_MQB,Getriebe_DQ_MQB,LEH_MQB,Motor_Diesel_MQB,Motor_Hybrid_MQB,Motor_Otto_MQB,SAK_MQB
 SG_ UH_Minute : 49|6@1+ (1,0) [0|59] "Unit_Minut" Airbag_MQB,BMS_MQB,Getriebe_DQ_Hybrid_MQB,Getriebe_DQ_MQB,LEH_MQB,Motor_Diesel_MQB,Motor_Hybrid_MQB,Motor_Otto_MQB,SAK_MQB
 SG_ UH_Second : 55|6@1+ (1,0) [0|59] "Unit_Secon" Airbag_MQB,BMS_MQB,Getriebe_DQ_Hybrid_MQB,Getriebe_DQ_MQB,LEH_MQB,Motor_Diesel_MQB,Motor_Hybrid_MQB,Motor_Otto_MQB,SAK_MQB
 SG_ Cluster_02_Old : 62|1@1+ (1,0) [0|1] "" Airbag_MQB,BMS_MQB,LEH_MQB
 SG_ ClockTime_01_Old : 63|1@1+ (1,0) [0|1] "" Airbag_MQB,BMS_MQB,LEH_MQB

BO_ 1716 VIN_01: 8 Gateway_MQB
 SG_ VIN_01_MUX M : 0|2@1+ (1,0) [0|3] "" Airbag_MQB
 SG_ KS_Secret_1 m0 : 8|8@1+ (1,0) [0|255] "" Vector__XXX
 SG_ KS_Secret_2 m0 : 16|8@1+ (1,0) [0|255] "" Vector__XXX
 SG_ KS_Secret_3 m0 : 24|8@1+ (1,0) [0|255] "" Vector__XXX
 SG_ KS_Secret_4 m0 : 32|8@1+ (1,0) [0|255] "" Vector__XXX
 SG_ VIN_1 m0 : 40|8@1+ (1,0) [0|255] "" Airbag_MQB
 SG_ VIN_2 m0 : 48|8@1+ (1,0) [0|255] "" Airbag_MQB
 SG_ VIN_3 m0 : 56|8@1+ (1,0) [0|255] "" Airbag_MQB
 SG_ VIN_4 m1 : 8|8@1+ (1,0) [0|255] "" Airbag_MQB
 SG_ VIN_5 m1 : 16|8@1+ (1,0) [0|255] "" Airbag_MQB
 SG_ VIN_6 m1 : 24|8@1+ (1,0) [0|255] "" Airbag_MQB
 SG_ VIN_7 m1 : 32|8@1+ (1,0) [0|255] "" Airbag_MQB
 SG_ VIN_8 m1 : 40|8@1+ (1,0) [0|255] "" Airbag_MQB
 SG_ VIN_9 m1 : 48|8@1+ (1,0) [0|255] "" Airbag_MQB
 SG_ VIN_10 m1 : 56|8@1+ (1,0) [0|255] "" Airbag_MQB
 SG_ VIN_11 m2 : 8|8@1+ (1,0) [0|255] "" Airbag_MQB
 SG_ VIN_12 m2 : 16|8@1+ (1,0) [0|255] "" Airbag_MQB
 SG_ VIN_13 m2 : 24|8@1+ (1,0) [0|255] "" Airbag_MQB
 SG_ VIN_14 m2 : 32|8@1+ (1,0) [0|255] "" Airbag_MQB
 SG_ VIN_15 m2 : 40|8@1+ (1,0) [0|255] "" Airbag_MQB
 SG_ VIN_16 m2 : 48|8@1+ (1,0) [0|255] "" Airbag_MQB
 SG_ VIN_17 m2 : 56|8@1+ (1,0) [0|255] "" Airbag_MQB

BO_ 316495015 VZE_04: 32 XXX
 SG_ VZE_DisplayMode : 0|2@1+ (1,0) [0|3] "" ZR_High,ZR_LIMU,ZR_MIB_TOP_ab_Gen3
 SG_ Detected_01 : 8|1@0+ (1,0) [0|1] "" XXX
 SG_ VZE_DisplaySuppress_Sign_3 : 9|1@1+ (1,0) [0|1] "" Vector__XXX
 SG_ VZE_DisplaySuppress_Sign_2 : 10|1@1+ (1,0) [0|1] "" Vector__XXX
 SG_ VZE_TrafficSign_1 : 11|8@1+ (5,0) [1|520] "" OTA_FC,ZR_High,ZR_LIMU,ZR_MIB_TOP_ab_Gen3
 SG_ VZE_TrafficSign_2 : 19|8@1+ (5,0) [1|255] "" OTA_FC,ZR_High,ZR_LIMU,ZR_MIB_TOP_ab_Gen3
 SG_ VZE_TrafficSign_3 : 27|8@1+ (5,0) [1|255] "" OTA_FC,ZR_High,ZR_LIMU,ZR_MIB_TOP_ab_Gen3
 SG_ VZE_Warning_TrafficSign_1 : 35|1@1+ (1,0) [0|1] "" ZR_High,ZR_LIMU,ZR_MIB_TOP_ab_Gen3
 SG_ VZE_Warning_TrafficSign_2 : 36|1@1+ (1,0) [0|1] "" ZR_High,ZR_LIMU,ZR_MIB_TOP_ab_Gen3
 SG_ VZE_Warning_TrafficSign_3 : 37|1@1+ (1,0) [0|1] "" ZR_High,ZR_LIMU,ZR_MIB_TOP_ab_Gen3
 SG_ VZE_SupplementarySign_1 : 38|4@1+ (1,0) [1|15] "" ZR_High,ZR_LIMU,ZR_MIB_TOP_ab_Gen3
 SG_ VZE_SupplementarySign_2 : 42|4@1+ (1,0) [1|15] "" ZR_High,ZR_LIMU,ZR_MIB_TOP_ab_Gen3
 SG_ VZE_SupplementarySign_3 : 46|4@1+ (1,0) [1|15] "" ZR_High,ZR_LIMU,ZR_MIB_TOP_ab_Gen3
 SG_ VZE_DisplaySuppress_Sign_1 : 50|1@1+ (1,0) [0|1] "" Vector__XXX
 SG_ VZE_Sign_01_CameraWied : 51|1@1+ (1,0) [0|1] "" ZR_High,ZR_LIMU,ZR_MIB_TOP_ab_Gen3
 SG_ VZE_Sign_02_CameraWied : 52|1@1+ (1,0) [0|1] "" ZR_High,ZR_LIMU,ZR_MIB_TOP_ab_Gen3
 SG_ VZE_Sign_03_CameraWied : 53|1@1+ (1,0) [0|1] "" ZR_High,ZR_LIMU,ZR_MIB_TOP_ab_Gen3
 SG_ VZE_Sign_01_Camera : 54|1@1+ (1,0) [0|1] "" ZR_High,ZR_LIMU,ZR_MIB_TOP_ab_Gen3
 SG_ VZE_Sign_01_Map : 55|1@1+ (1,0) [0|1] "" ZR_High,ZR_LIMU,ZR_MIB_TOP_ab_Gen3
 SG_ VZE_Sign_01_Law : 56|1@1+ (1,0) [0|1] "" ZR_High,ZR_LIMU,ZR_MIB_TOP_ab_Gen3
 SG_ VZE_Sign_02_Camera : 57|1@1+ (1,0) [0|1] "" ZR_High,ZR_LIMU,ZR_MIB_TOP_ab_Gen3
 SG_ VZE_Sign_02_Map : 58|1@1+ (1,0) [0|1] "" ZR_High,ZR_LIMU,ZR_MIB_TOP_ab_Gen3
 SG_ VZE_Sign_02_Law : 59|1@1+ (1,0) [0|1] "" ZR_High,ZR_LIMU,ZR_MIB_TOP_ab_Gen3
 SG_ VZE_Sign_03_Camera : 60|1@1+ (1,0) [0|1] "" ZR_High,ZR_LIMU,ZR_MIB_TOP_ab_Gen3
 SG_ VZE_Sign_03_Map : 61|1@1+ (1,0) [0|1] "" ZR_High,ZR_LIMU,ZR_MIB_TOP_ab_Gen3
 SG_ VZE_Sign_03_Law : 62|1@1+ (1,0) [0|1] "" ZR_High,ZR_LIMU,ZR_MIB_TOP_ab_Gen3
 SG_ VZE_Chime : 63|1@1+ (1,0) [0|1] "" ZR_High,ZR_LIMU,ZR_MIB_TOP_ab_Gen3
 SG_ VZE_TrafficSign_4 : 75|8@1+ (1,0) [0|31] "" XXX
 SG_ VZE_TrafficSign_6 : 92|7@1+ (1,0) [0|7] "" XXX
 SG_ VZE_Roadworks : 110|1@0+ (1,0) [0|1] "" XXX

BO_ 316495049 SAL_01: 8 XXX
 SG_ CRC : 0|8@1+ (1,0) [0|255] "" XXX
 SG_ CNT : 8|4@1+ (1,0) [0|15] "" XXX
 SG_ Brake_Unknown : 18|1@0+ (1,0) [0|1] "" XXX
 SG_ Brake_Light_01 : 20|1@0+ (1,0) [0|1] "" XXX
 SG_ Right_Indicator : 25|1@0+ (1,0) [0|1] "" XXX
 SG_ Left_Indicator : 26|1@1+ (1,0) [0|3] "" XXX
 SG_ Reverse_Light : 27|1@0+ (1,0) [0|1] "" XXX
 SG_ Brake_Light_02 : 30|1@0+ (1,0) [0|1] "" XXX
 SG_ Right_Indicator_02 : 44|1@1+ (1,0) [0|3] "" XXX
 SG_ Left_Indicator_02 : 45|1@0+ (1,0) [0|1] "" XXX

BO_ 316495056 Charging_Dynamics: 8 XXX
 SG_ Max_Charge_Power : 51|13@1+ (0.1,0) [0|819.1] "kW" XXX
 SG_ Max_Charge_Current : 25|13@1+ (0.2,0) [0|1638.2] "A" XXX

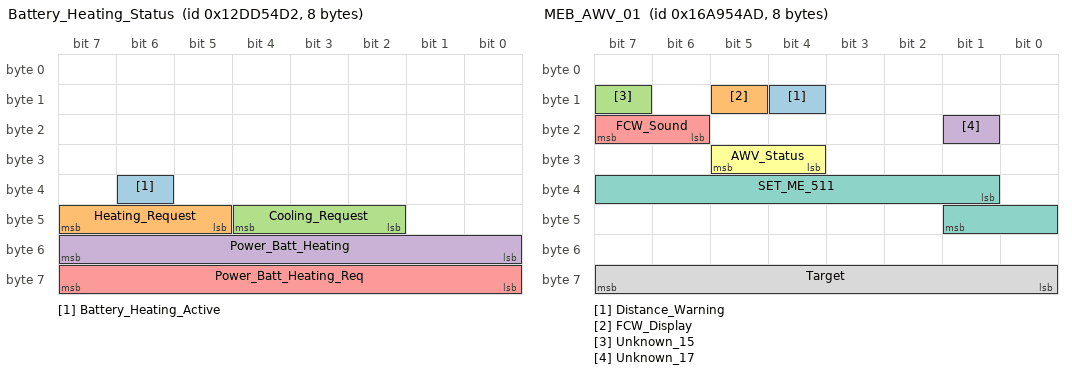
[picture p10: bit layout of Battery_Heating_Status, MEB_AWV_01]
BO_ 316495058 Battery_Heating_Status: 8 XXX
 SG_ Battery_Heating_Active : 38|1@1+ (1,0) [0|1] "" XXX
 SG_ Heating_Request : 45|3@1+ (1,0) [0|7] "" XXX
 SG_ Cooling_Request : 42|3@1+ (1,0) [0|7] "" XXX
 SG_ Power_Batt_Heating : 48|8@1+ (1,0) [0|255] "W" XXX
 SG_ Power_Batt_Heating_Req : 56|8@1+ (1,0) [0|255] "W" XXX

BO_ 316495081 MEB_Camera_05: 8 XXX

BO_ 316495106 AAA_01: 8 XXX
 SG_ CRC : 0|8@1+ (1,0) [0|255] "" XXX
 SG_ CHK : 8|4@1+ (1,0) [0|15] "" XXX

BO_ 316495140 MEB_Camera_06: 64 XXX

BO_ 316495165 HVL_01: 8 XXX
 SG_ CRC : 0|8@1+ (1,0) [0|255] "" XXX
 SG_ CHK : 8|4@1+ (1,0) [0|15] "" XXX

BO_ 380195935 IPA_02: 8 XXX

BO_ 380196006 Battery_Temperatures: 8 XXX
 SG_ Battery_Max_Temp : 24|8@1+ (0.5,-40) [-40|87.5] "degC" XXX
 SG_ Battery_Min_Temp : 32|8@1+ (0.5,-40) [-40|87.5] "degC" XXX

BO_ 380196013 MEB_AWV_01: 8 XXX
 SG_ Distance_Warning : 12|1@0+ (1,0) [0|1] "" XXX
 SG_ FCW_Display : 13|1@0+ (1,0) [0|1] "" XXX
 SG_ Unknown_15 : 15|1@0+ (1,0) [0|1] "" XXX
 SG_ Unknown_17 : 17|1@0+ (1,0) [0|1] "" XXX
 SG_ FCW_Sound : 22|2@1+ (1,0) [0|3] "" XXX
 SG_ AWV_Status : 28|2@1+ (1,0) [0|3] "" XXX
 SG_ SET_ME_511 : 33|9@1+ (1,0) [0|127] "" XXX
 SG_ Target : 56|8@1+ (1,0) [0|255] "" XXX

BO_ 380196019 MEB_Camera_07: 16 XXX

BO_ 380196034 MEB_Radar_Unknown_01: 8 XXX

BO_ 380196036 MEB_Camera_08: 8 XXX

BO_ 389241616 MEB_Camera_09: 8 XXX

BO_ 389241617 MEB_Camera_10: 8 XXX

BO_ 401604687 MEB_Camera_11: 8 XXX

BO_ 401604695 MEB_PACC_01: 8 XXX
 SG_ Dynamic_in_Drive : 63|1@0+ (1,0) [0|1] "" XXX

BO_ 402522959 MEB_Camera_14: 8 XXX

BO_ 441800001 EML_02: 8 XXX
 SG_ CRC : 0|8@1+ (1,0) [0|255] "" XXX
 SG_ CHK : 8|4@1+ (1,0) [0|15] "" XXX

BO_ 441800082 MEB_Camera_12: 8 XXX

BO_ 441800114 Charging_Optimization: 8 XXX
 SG_ Temperature_Status_Charge : 15|3@1+ (1,0) [0|7] "" XXX

BO_ 452984911 MEB_Camera_13: 8 XXX

BO_ 452984919 MEB_Unknown_01: 8 XXX

CM_ SG_ 380196013 AWV_Status "Mirrors AWV_03.AWV_Unavailable, at a higher rate";
CM_ BO_ 1622 "Steuergerät für Lenkungsverriegelung";
CM_ BO_ 316495165 "Steuergerät ICAS1";
CM_ BO_ 441800001 "Steuergerät für Fahrzeugbewegung";
VAL_ 190 Engine_Status 1 "Ready" 2 "Online";
VAL_ 267 TSK_Status 0 "init" 1 "disabled" 2 "enabled" 3 "regulating" 4 "accel_pedal_override" 5 "brake_only" 6 "temp_fault" 7 "perm_fault";
VAL_ 496 EA_Texte 0 "No_Display" 1 "EmergencyStopAssist_fehlende_DriverActivity" 2 "EmergencyStopAssist_Active_Fahrzeugfuehrung_TakeOver" 3 "EmergencyStopAssist_automatischer_Nothalt_Is_Performed" 4 "EmergencyStopAssist_automatischer_Nothalt_Performed" 5 "EmergencyStopAssist_Verbindung_To_Notruf_Is_aufgebaut" 6 "EmergencyStopAssist_Deactivated" 7 "EmergencyStopAssist_Intervention_Aborted" 8 "EmergencyStopAssist_fehlende_DriverActivity_2" 9 "Sekundenschlaf_Detected" 10 "LaneAssist_Steering_TakeOver" 11 "ACA_Fahrzeugfuehrung_TakeOver" 12 "EA_Drive_Standstreifenwechsel" 14 "EmergencyStopAssist_Not_Available_Reversible" 15 "EmergencyStopAssist_Malfunction_Irreversible";
VAL_ 496 ACF_Lamp_Hands_Off 0 "No_Display" 1 "Hands_Off_Detected";
VAL_ 496 EA_Infotainment_Req 0 "Init" 1 "No_Lowering" 2 "Lowering" 3 "Mute";
VAL_ 496 EA_Doors_Req 0 "No_Request" 1 "Doors_entriegeln";
VAL_ 496 EA_Innenraumlicht_Req 0 "Innenraumbeleuchtung_SwitchOff" 1 "Innenraumbeleuchtung_SwitchOn";
VAL_ 496 zFAS_HazardFlash 0 "Off" 1 "Static" 2 "PushButton" 3 "Static_Without_WBT";
VAL_ 496 STP_PrimaryDisplay 0 "No_Display" 1 "Available" 2 "Active" 3 "Uebernahme" 4 "Active_Warning" 5 "Not_Available";
VAL_ 496 EA_BrakeLightFlash 0 "No_Flash" 1 "Request_BrakeLightFlash";
VAL_ 496 EA_Flash 0 "No_Flash" 1 "Wechselblinken_Left" 2 "Wechselblinken_Right" 3 "HazardFlash" 4 "HazardFlash_PushButton";
VAL_ 619 Travel_Assist_Status 4 "enabled" 0 "disabled" 2 "ready" 3 "pre_ready";
VAL_ 619 Travel_Assist_Request 4 "enable" 3 "disable" 0 "no_request" 1 "error";
VAL_ 619 Travel_Assist_Available 0 "not_available" 1 "available";
VAL_ 768 ACC_SpeedLimit 0 "No_Display" 1 "5_AllowedMaxSpeed" 2 "7_AllowedMaxSpeed" 3 "10_AllowedMaxSpeed" 4 "15_AllowedMaxSpeed" 5 "20_AllowedMaxSpeed" 6 "25_AllowedMaxSpeed" 7 "30_AllowedMaxSpeed" 8 "35_AllowedMaxSpeed" 9 "40_AllowedMaxSpeed" 10 "45_AllowedMaxSpeed" 11 "50_AllowedMaxSpeed" 12 "55_AllowedMaxSpeed" 13 "60_AllowedMaxSpeed" 14 "65_AllowedMaxSpeed" 15 "70_AllowedMaxSpeed" 16 "75_AllowedMaxSpeed" 17 "80_AllowedMaxSpeed" 18 "85_AllowedMaxSpeed" 19 "90_AllowedMaxSpeed" 20 "95_AllowedMaxSpeed" 21 "100_AllowedMaxSpeed" 22 "110_AllowedMaxSpeed" 23 "120_AllowedMaxSpeed" 24 "130_AllowedMaxSpeed" 25 "140_AllowedMaxSpeed" 26 "150_AllowedMaxSpeed" 27 "160_AllowedMaxSpeed" 28 "200_AllowedMaxSpeed" 30 "250_AllowedMaxSpeed" 31 "End_AllowedMaxSpeed";
VAL_ 768 ACC_SetSpeed_Colour 0 "Grundfarbe" 1 "Colour_1";
VAL_ 768 ACC_Warning_TrafficSign_1 0 "No_Warning_InitialValue" 1 "Warning";
VAL_ 768 ACA_LateralGuidance 0 "No_Display_Or_init" 1 "Passive" 2 "Active" 3 "Warning";
VAL_ 768 ACC_Control_AIO 0 "Control_TrafficLight_Not_Active" 1 "Control_TrafficLight_Active";
VAL_ 768 ACC_SetSpeed_02 1023 "No_Display";
VAL_ 768 ACC_DistanceIndex_02 0 "Audi (Init), VW (Passive/Active_FreeJourney)" 1022 "Off_Passive" 1023 "Active_FreeJourney";
VAL_ 768 ACC_Display_Prio 0 "Highest_Prio" 1 "Average_Prio" 2 "Low_Prio" 3 "No_Prio";
VAL_ 768 ACC_rel_Object_AuxDisplay 0 "No Display" 1 "Relevant_Object_Detected" 2 "Relevant_Object_DistanceWarning";
VAL_ 768 ACC_Set_TimeGap 0 "No_Display" 1 "TimeGap_1" 2 "TimeGap_2" 3 "TimeGap_3" 4 "TimeGap_4" 5 "TimeGap_5" 6 "Not_Defined" 7 "Not_Defined";
VAL_ 768 ACC_Optical_DriverNotice 0 "Optical_DriverNotice_OFF" 1 "Optical_DriverNotice_ON";
VAL_ 768 ACC_WarningNote 0 "No_WarningNote" 1 "WarningNote";
VAL_ 768 ACC_EGO_Vehicle 0 "No_Display" 1 "Active" 2 "Warning" 3 "Active_stop" 4 "Passive";
VAL_ 768 ACC_Relevant_Object_02 0 "No_Display" 1 "Relevant_Object_Detected" 2 "Relevant_Object_Warning" 3 "Passive";
VAL_ 768 ACC_SetSpeed_Reached 0 "SetSpeed_Not_Reached" 1 "SetSpeed_Reached";
VAL_ 768 ACC_Display_TimeGap 0 "Display_TimeGap_Not_Requested" 1 "Display_TimeGap_Requested";
VAL_ 768 ACC_Texte_PrimaryDisplay_02 0 "No Display" 1 "VDA_ACC_Symbol_YYY_kmh_mph" 2 "Kurven_Symbol_YYY_kmh_mph" 3 "SpeedLimit_Symbol_YYY_kmh_mph" 4 "ACC_PullAwayReady" 5 "eingestellte_TimeGap" 6 "Door Open !" 7 "Stationary Object Ahead" 8 "o  o  o" 9 "ACC Off" 10 "ACC Starting" 11 "ACC Sensor View !" 12 "ACC Not Available" 13 "ACC Error" 14 "ESP Intervention" 15 "ESP Passive !" 16 "ParkingBrake !" 17 "SpeedLimit" 18 "SelectorLeverPosition !" 19 "Driver BeltBuckle Open !" 20 "ShiftLeverPosition !" 21 "Rpm !" 22 "HDC Active" 23 "Clutch Pressed" 24 "Gear Engage !" 25 "Brake Overheated !" 26 "Gradient_Downgrade_Closed_Large" 27 "Distance" 28 "RightOvertake_Prevented" 29 "LeftOvertake_Prevented" 30 "Kreuzungs_Symbol" 31 "Roundabout_Symbol" 32 "Downgrade_Symbol" 33 "SpeedLimit_CurveAssist_On" 34 "CurveAssist_On" 35 "SpeedLimitAssist_On" 36 "Caution_SpeedExceedance" 37 "SpeedLimit_And_CurveAssist_Not_Available" 38 "SpeedLimit_Not_Available" 39 "CurveAssist_Not_Available" 40 "MotorwayOffJourney_Symbol" 41 "TrafficJamEnd_Symbol" 42 "Engstelle_Symbol" 43 "STP_Available" 44 "TrafficLight_vertikal" 45 "TrafficLight_horizontal" 46 "Status_Available";
VAL_ 768 ACC_Texte_AuxDisplay_02 0 "No_Display" 1 "ACC_OFF" 2 "Standby" 3 "Override" 4 "Distance" 5 "Distance_1" 6 "Distance_2" 7 "Distance_3" 8 "Distance_4" 9 "Distance_5" 10 "Distance_1__Dyn" 11 "Distance_2__Dyn" 12 "Distance_3__Dyn" 13 "Distance_4__Dyn" 14 "Distance_5__Dyn" 15 "Distance_1__comf" 16 "Distance_2__comf" 17 "Distance_3__comf" 18 "Distance_4__comf" 19 "Distance_5__comf" 20 "Distance_1__efficiency" 21 "Distance_2__efficiency" 22 "Distance_3__efficiency" 23 "Distance_4__efficiency" 24 "Distance_5__efficiency" 25 "Distance_1__TrafficJam" 26 "Distance_2__TrafficJam" 27 "Distance_3__TrafficJam" 28 "Distance_4__TrafficJam" 29 "Distance_5__TrafficJam" 30 "Caution" 31 "DistanceDisplay" 32 "DistanceDisplay_Warning_Activated" 33 "Status_Available" 34 "Engstelle" 35 "RUV_Active_RightHandTraffic" 36 "RUV_Active_LeftHandTraffic" 37 "STP_Available" 38 "AW_WarnThreshold_1" 39 "AW_WarnThreshold_2" 40 "AW_WarnThreshold_3" 41 "AW_Warning_1" 42 "AW_Warning_2" 43 "AW_Warning_3";
VAL_ 768 Status_PrimaryDisplay 0 "No_Display" 1 "Status_standby" 2 "Status_Active" 3 "Status_Warning";
VAL_ 768 Heartbeat 1 "ACC_Init_Low" 420 "ACC_Init_High" 221 "ACC_Available_Low" 360 "ACC_Available_High";
VAL_ 768 ACC_Status_ACC 0 "ACC_OFF_MainSwitch_Off" 1 "ACC_INIT" 2 "ACC_STANDBY" 3 "ACC_Active_Controls" 4 "ACC_OVERRIDE" 5 "ACC_ShutdownReaction" 6 "Reversible_Error_In_ACC_System" 7 "Irreversible_Error_In_ACC_System";
VAL_ 768 Lead_Type_Detected 1 "Lead_Detected" 0 "No_Lead_Detected";
VAL_ 768 Lead_Type 5 "Bicycle" 3 "Car" 0 "None" 2 "Truck" 4 "Motorcycle";
VAL_ 768 TimeGap_1 0 "No Display";
VAL_ 768 TimeGap_2 0 "No Display" 32 "Minimum";
VAL_ 768 TimeGap_3 0 "No Display";
VAL_ 768 TimeGap_4 0 "No Display" 40 "Minimum";
VAL_ 768 TimeGap_5 0 "No Display";
VAL_ 988 EPB_Status 0 "Open" 1 "Closed_Parking" 2 "PartlyTensioned_Hold" 3 "In_Run_Open" 4 "In_Run_Close" 5 "tbd" 6 "Init" 7 "Unknown";
VAL_ 988 GE_DriveRange 0 "BetweenPosition" 1 "Init" 5 "P" 6 "R" 7 "N" 8 "D" 9 "D" 10 "E" 13 "T" 14 "T" 15 "Error";
VAL_ 997 FT_Door_Status 0 "Init" 1 "Door_Closed" 2 "Door_Open" 3 "Error";
VAL_ 997 FT_Door_Status_QBit 0 "Status_DoorContact_Safe" 1 "Status_DoorContact_Uncertain";
VAL_ 997 FT_Lock_PushButton_02 0 "Not_Pressed" 1 "Pressed";
VAL_ 997 FT_KeySwitch_Closed_02 0 "Not_Pressed" 1 "Pressed";
VAL_ 997 FT_BFS_Door_Status 0 "Init" 1 "Door_Closed" 2 "Door_Open" 3 "Error";
VAL_ 997 FT_HBFS_Door_Status 0 "Init" 1 "Door_Closed" 2 "Door_Open" 3 "Error";
VAL_ 997 FT_HFS_Door_Status 0 "Init" 1 "Door_Closed" 2 "Door_Open" 3 "Error";
VAL_ 997 FT_DoorOpen_Warning 0 "DoorWarning_Not_Active" 1 "DoorWarning_Active";
VAL_ 997 FT_SP_Heating_On 0 "Off" 1 "On";
VAL_ 997 FT_ChildSeat_PushButton_Left_02 0 "Not_Pressed" 1 "Pressed";
VAL_ 997 FT_ChildSeat_PushButton_Right_02 0 "Not_Pressed" 1 "Pressed";
VAL_ 997 FT_TD_Key_Status 0 "No_Error" 1 "ShortCircuit_After_Minus" 2 "ShortCircuit_After_Plus" 3 "WireBreak";
VAL_ 997 FT_TCR_Mode_Active 0 "TCR_Mode_Deactivated" 1 "TCR_Mode_Active";
VAL_ 997 FS_Push_DoorHandle 0 "Not_Detected" 1 "Detected";
VAL_ 1004 TSK_State 0 "init" 1 "disabled" 2 "enabled" 3 "regulating" 4 "accel_pedal_override" 5 "brake_only" 6 "temp_fault" 7 "perm_fault";
VAL_ 1122 PSD_Segment_ID 0 "No SegmentInfo Present" 1 "ErrorValue";
VAL_ 1122 PSD_Predecessor_Segment_ID 0 "No SegmentInformation Present" 1 "ErrorValue";
VAL_ 1122 PSD_Strassenkategorie 0 "Rest_FieldTrack_Schotterweg_PrivateRoad" 1 "LocationRoadߥ" 2 "CircuitRoadߥ" 3 "Landstraߥ" 4 "Bundesstraߥ" 5 "Motorway" 7 "Init";
VAL_ 1122 PSD_EndCurvature 255 "Straight";
VAL_ 1122 PSD_EndCurvature_Sign 0 "Curvature_Positive" 1 "Curvature_Negative";
VAL_ 1122 PSD_Idenditaets_ID 0 "No_Segment_Information_Present" 1 "Error";
VAL_ 1122 PSD_ADAS_Quality 0 "No_ADAS_Quality" 1 "ADAS_Quality";
VAL_ 1122 PSD_MostLikely_Path 0 "Path_With_Lower_Probability" 1 "MostLikely_Path";
VAL_ 1122 PSD_Straightest_Path 0 "Not_Straightest_Path" 1 "Straightest_Path";
VAL_ 1122 PSD_Lanes_Count 0 "OneWayStreet_in_falsche_Direction" 1 "A_Lane" 2 "Two_Lanes" 3 "Three_Lanes" 4 "vier_Lanes" 5 "fuenf_Lanes" 6 "sechs_Lanes" 7 "More_As_sechs_Lanes";
VAL_ 1122 PSD_Bebauung 0 "Outside_bebauten_Gebietes" 1 "Within_bebauten_Gebietes";
VAL_ 1122 PSD_Segment_Complete 0 "Segment_Attribute_Not_Complete" 1 "Segment_Attribute_Complete";
VAL_ 1122 PSD_Ramp 0 "Road_With_OncomingTraffic" 1 "OpenJourney_OneWayStreet" 2 "Exit_OneWayStreet" 3 "OneWayStreet";
VAL_ 1122 PSD_StartCurvature 255 "Straight";
VAL_ 1122 PSD_StartCurvature_Sign 0 "Positive" 1 "Negative";
VAL_ 1122 PSD_Abzweigerichtung 0 "rects_Branching_Road" 1 "Left_Branching_Road";
VAL_ 1123 PSD_Pos_Segment_ID 0 "No Position gegeben" 1 "ErrorValue";
VAL_ 1123 PSD_Pos_Location_Eindeutig 0 "mehrdeutiger_Location" 1 "eindeutiger_Location";
VAL_ 1123 PSD_Pos_Error_Laengsrichtung 0 "Init" 1 "< 2m" 2 "< 5m" 3 "< 10m" 4 "< 20m" 5 "< 50m" 6 "> 50m" 7 "Off-Road";
VAL_ 1123 PSD_Pos_Lane 0 "Unknown" 1 "First_Lane_From_Right" 2 "Zweite_Lane_From_Right" 3 "Dritte_Lane_From_Right" 4 "Vierte_Lane_From_Right" 5 "Fuenfte_Lane_From_Right" 6 "Sechte_Lane_From_Right" 7 "Siebte_Or_Further_Lane_From_Right";
VAL_ 1123 PSD_Attribut_Segment_ID_05 0 "No_Segment_Information" 1 "Error";
VAL_ 1123 PSD_Attribut_1_ID 0 "No_Information";
VAL_ 1123 PSD_Attribut_2_ID 0 "No_Information";
VAL_ 1123 PSD_Attribute_Complete_05 0 "Attribute_Not_Complete" 1 "Attribute_Complete";
VAL_ 1124 PSD_06_Mux 0 "Init";
VAL_ 1124 PSD_Sys_Segment_ID 0 "No SegmentInfo Present" 1 "Not Permitted";
VAL_ 1124 PSD_Sys_Speed_Unit 0 "km/h" 1 "mph";
VAL_ 1124 PSD_Sys_Verkehrsrichtung 0 "RightHandTraffic" 1 "LeftHandTraffic";
VAL_ 1124 PSD_Sys_Geometrieguete 0 "Low_Quality" 1 "tbd" 2 "tbd" 3 "High_Quality";
VAL_ 1124 PSD_Sys_Mapmatchingguete 0 "Low_Quality" 1 "res" 2 "res" 3 "High_Quality";
VAL_ 1124 PSD_Sys_Age_Map 0 "Smaller_1_Year" 1 "1_Year" 2 "2_Years" 3 "3_Years" 4 "4_Years" 5 "5_Years" 6 "6_Years" 7 "Greater_7_Years";
VAL_ 1124 PSD_Sys_RouteGuidance 0 "RouteGuidance Not Active" 1 "RouteGuidance Active";
VAL_ 1124 PSD_Sys_US_State 0 "No_US_State" 1 "Alabama" 2 "Alaska" 3 "Arkansas" 4 "Arizona" 5 "California" 6 "Colorado" 7 "Conneticut" 8 "District_of_Columbia" 9 "Delaware" 10 "Florida" 11 "Georgia" 12 "Hawaii" 13 "Idaho" 14 "Illinois" 15 "Iowa" 16 "Indiana" 17 "Kansas" 18 "Kentucky" 19 "Louisiana" 20 "Massachusetts" 21 "Maryland" 22 "Maine" 23 "Michigan" 24 "Minnesota" 25 "Missouri" 26 "Mississippi" 27 "Montana" 28 "North_Carolina" 29 "North_Dakota" 30 "Nebraska" 31 "Nevada" 32 "New_Hampshire" 33 "New_Jersey" 34 "New_Mexico" 35 "New_York" 36 "Ohio" 37 "Oklahoma" 38 "Oregon" 39 "Pennsylvania" 40 "Puerto_Rico" 41 "Rhode_Island" 42 "South_Carolina" 43 "South_Dakota" 44 "Tennessee" 45 "Texas" 46 "Utah" 47 "Virginia" 48 "Virgin_Islands" 49 "Vermont" 50 "Washington" 51 "Wisconsin" 52 "West_Virginia" 53 "Wyoming";
VAL_ 1124 PSD_Sys_Quali_Available 0 "Qualitaetskriterien_Not_Available" 1 "Qualitaetskriterien_Available";
VAL_ 1124 PSD_Sys_RouteGuidance_Changed 0 "RouteGuidance_Not_Changed" 1 "RouteGuidance_Changed";
VAL_ 1124 PSD_Sys_Geometrieguete_Extended 0 "Init";
VAL_ 1124 PSD_Attribut_Segment_ID 0 "No_Segment_Information_Present" 1 "Error";
VAL_ 1124 PSD_Attribut_3_ID 0 "No_Information";
VAL_ 1124 PSD_Attribut_4_ID 0 "No_Information";
VAL_ 1124 PSD_Attribut_5_ID 0 "No_Information";
VAL_ 1124 PSD_Attribute_Complete_06 0 "Attribute_Not_Complete" 1 "Attribute_Complete";
VAL_ 1124 PSD_Total_Segment_ID 0 "No SegmentInfo Present" 1 "Not Permitted";
VAL_ 1124 PSD_Total_Speed 0 "No SpeedRequirement" 1 "0 km/h < v_max <  5 km/h" 2 "5 km/h < v_max < 10km/h" 3 "10 km/h < v_max < 15 km/h" 4 "15 km/h < v_max < 20 km/h" 5 "20 km/h < v_max < 25 km/h" 6 "25 km/h < v_max < 30 km/h" 7 "30 km/h < v_max < 35 km/h" 8 "35 km/h < v_max < 40 km/h" 9 "40 km/h < v_max < 45 km/h" 10 "45 km/h < v_max < 50 km/h" 11 "50 km/h < v_max < 60 km/h" 12 "60 km/h < v_max < 70 km/h" 13 "70 km/h < v_max < 80 km/h" 14 "80 km/h < v_max < 90 km/h" 15 "90 km/h < v_max < 100 km/h" 16 "100 km/h < v_max < 110 km/h" 17 "110 km/h < v_max < 120 km/h" 18 "120 km/h < v_max < 130 km/h" 19 "130 km/h < v_max < 140 km/h" 20 "140 km/h < v_max < 150 km/h" 21 "150 km/h < v_max < 160 km/h" 22 "160 km/h < v_max" 23 "SpeedRequirement Cancelled" 24 "..0x1F Invalid";
VAL_ 1124 PSD_Total_Type 0 "Speed_Class_Of_Kartendatensuppliers" 1 "Explicit_abgeleiteten_Limit" 2 "By_Gesetzg_vorgeg_allgem_Requirement_For_uebertr_Rahmenbed" 3 "Init";
VAL_ 1124 PSD_Total_Lane_Speed_Limit 0 "Requirement_For_All_spuren_Valid";
VAL_ 1124 PSD_Total_Speed_TrailerCombo 0 "All Vehicles" 1 "CAR With TrailerCombo" 2 "Truck, Buses, etc.";
VAL_ 1124 PSD_Total_Speed_Witter 0 "Witterungsunabh䮧ig" 1 "N䳳e, Rain, Precipitation" 2 "Gl䴴e" 3 "Fog";
VAL_ 1124 PSD_Total_Speed_Tag_Req 0 "No Start Defined" 1 "Monday" 2 "Tuesday" 3 "Wednesday" 4 "Thursday" 5 "Friday" 6 "Saturday" 7 "Sunday";
VAL_ 1124 PSD_Total_Speed_Tag_End 0 "No End Defined" 1 "Monday" 2 "Tuesday" 3 "Wednesday" 4 "Thursday" 5 "Friday" 6 "Saturday" 7 "Sunday";
VAL_ 1124 PSD_Total_Speed_Std_Req 25 "No Start For Hourly Restrict䮫ungen";
VAL_ 1124 PSD_Total_Speed_Std_End 25 "No End For Hourly Restrict䮫ungen";
VAL_ 1124 PSD_Total_NoOvertaking 0 "No ܢerholverbot" 1 "All Vehicles" 2 "ܢerholverbot For CAR With TrailerCombo" 3 "ܢerholverbot For Truck, Buses, etc.";
VAL_ 1124 PSD_Total_VariableTrafficSign 0 "No VariableTrafficSign" 1 "VariableTrafficSign Left" 2 "VariableTrafficSign Right" 3 "VariableTrafficSign Left And Right" 4 "Wechselverkerhszeichen Over The Road";
VAL_ 1124 PSD_VariableTrafficSign_Type 0 "No_VariableTrafficSign" 1 "LED_VariableTrafficSign" 2 "Not_LED_VariableTrafficSign";
VAL_ 1124 PSD_Total_Gesetzlich_Kategorie 0 "No_legales_Inhibit" 1 "innerorts" 2 "ausserorts" 3 "Motorway";
VAL_ 1124 PSD_Total_Gesetzlich_Additional 0 "No_Additional_Closed_legalem_Requirement" 1 "Trailer_Class_1" 2 "Trailer_Class_2";
VAL_ 1124 PSD_Total_TrafficSign_Source 0 "VZA_No_Onlinedienst" 1 "Only_VZA" 2 "Only_VZO" 3 "VZA_And_VZO";
VAL_ 1124 PSD_Total_Attribute_Complete 0 "Attribute_Not_Complete" 1 "Attribute_Complete";
VAL_ 1124 PSD_Tree_Length_VZ 0 "Ost" 1 "West";
VAL_ 1124 PSD_Tree_Width_VZ 0 "Nord" 1 "Sued";
VAL_ 1124 PSD_Gradient_1_Segment_ID 0 "No_Segment_Information_Present" 1 "Error";
VAL_ 1124 PSD_Gradient_1_A_Gradient 126 "More_As_15_Percent" 127 "Gradient_Unknown";
VAL_ 1124 PSD_Gradient_1_A_Sign 0 "Downgrade" 1 "Gradient";
VAL_ 1124 PSD_Gradient_1_B_Gradient 126 "More_As_15_Percent" 127 "Gradient_Unknown";
VAL_ 1124 PSD_Gradient_1_B_Sign 0 "Downgrade" 1 "Gradient";
VAL_ 1124 PSD_Gradient_1_Attribute_kompl 0 "Gradients_Not_Complete" 1 "Gradients_Complete";
VAL_ 1124 PSD_Gradient_2_Segment_ID 0 "No_Segment_Information_Present" 1 "Error";
VAL_ 1124 PSD_Gradient_2_Gradient 126 "More_As_15_Percent" 127 "Gradient_Unknown";
VAL_ 1124 PSD_Gradient_2_Sign 0 "Downgrade" 1 "Gradient";
VAL_ 1124 PSD_Gradient_2_Attribute_kompl 0 "Gradients_Not_Complete" 1 "Gradients_Complete";
VAL_ 1153 ZR_LoGeWa_Event_ClusterWarning 0 "Init" 1 "Unfall" 2 "Traktionsverlust" 3 "Panne" 4 "Sichtbehinderung" 5 "Aquaplaning" 6 "EEBL" 7 "SEF_Status" 8 "SEF_Dyn_allgemein" 9 "SEF_Dyn_Front" 10 "SEF_Dyn_Rear" 11 "SEF_Dyn_Left" 12 "SEF_Dyn_Right" 13 "TrafficJamEnd";
VAL_ 1153 Nav_FoD_Status 0 "Init" 1 "Nav_permanently_available" 2 "FoD_Nav_not_activated" 3 "FoD_Nav_activated" 4 "R4N_Nav_not_activated";
VAL_ 1153 MIB_ToneAlternator_PH_Available 0 "ToneAlternator_Not_Available" 1 "ToneAlternator_Front_Available" 2 "ToneAlternator_Rear_Available" 3 "ToneAlternator_Total_Available" 4 "ToneAlternator_In_AMP";
VAL_ 1153 DSSS_Warning 0 "No_Warning" 1 "Red_traffic_light_guidance" 2 "Stop_Sign_warning" 3 "Rear_end_collision_avoidance_warning" 4 "Intersection_collision_avoidance_warning_right" 5 "Intersection_collision_avoidance_warning_left" 6 "turn_right_collision_avoidance" 7 "turn_left_collision_avoidance" 8 "pedestrian_crossing_right" 9 "pedestrian_crossing_left" 10 "bicycle_collision_right" 11 "bicycle_collision_left";
VAL_ 1153 ZR_Kindersicherung_RSE 0 "Inactive" 1 "Active";
VAL_ 1153 ZR_RSE_Activate 0 "Inactive" 1 "Active";
VAL_ 1153 MMI_SDS_Active 0 "Inactive" 1 "Active";
VAL_ 1153 MU_SecondDisplay 0 "Init" 1 "gueltige_Map" 2 "ungueltiges_Signal" 3 "Not_Fitted";
VAL_ 1153 MMI_Phone_Active 0 "Telefongespraech_Not_Active" 1 "Telefongespraech_Active";
VAL_ 1153 MMI_Belt_Mic_ref 0 "Downlink_Inactive" 1 "Downlink_Active";
VAL_ 1153 ZR_Status_Staging 0 "Init" 1 "Staging_Deactivated" 2 "Staging_Start" 3 "Staging_Stop";
VAL_ 1153 MMI_Gauges_active 0 "gauges_inactive" 1 "gauges_active";
VAL_ 1153 ZR_MXB_Manoever_Announcement 0 "No_Announcement" 1 "Announcement_Without_Direction" 2 "Announcement_Right_Direction" 3 "Announcement_Left_Direction";
VAL_ 1153 ZR_LAPP_SpecialMode_Status 0 "No_Request" 1 "SpecialMode_Active" 2 "Activation_Not_Possible";
VAL_ 1153 MMI_StartStop_Info 0 "StopEnable" 1 "StopInhibit" 2 "StartRequest" 3 "Error";
VAL_ 1153 ZR_Parking_SpecialMode 0 "Init" 1 "SpecialMode_Active" 2 "SpecialMode_Not_Available" 3 "WLAN_Off" 4 "WLAN_OffCoded" 15 "No_WLAN_HW";
VAL_ 1153 ZR_Rundenbewertung 0 "Bewertung_Not_Active" 1 "langsamer" 2 "Equal_Fast" 3 "Faster" 4 "Reserved" 5 "Reserved" 6 "Reserved" 7 "Reserved" 8 "Reserved" 9 "Reserved" 10 "Reserved" 11 "Reserved" 12 "Reserved" 13 "Reserved" 14 "Init" 15 "Function_Not_Fitted";
VAL_ 1153 ZR_Rundenfortschritt 254 "Init" 255 "Function_Not_Fitted";
VAL_ 1155 Mo_Powermeter_Limit 4093 "OFF";
VAL_ 1155 MO_Text_Activation_Drive 0 "No_Display" 1 "ChargePlug_Not_DriveReady" 2 "erneute_Activation_Required" 3 "Warten_Drive_Is_Activated" 4 "To_Drive_Brake_And_DriveRange" 5 "h2_FuelFlap_Not_DriveReady" 6 "To_Start_Brake_Press" 7 "To_Start_Clutch_Press" 15 "Init";
VAL_ 1155 MO_Powermeter_Staging_Active 0 "No_Display" 1 "Staging_Active";
VAL_ 1155 MO_Powermeter_Charge_Limit 1022 "Init" 1023 "Error";
VAL_ 1155 MO_Powermeter_Limit_strategisch 4094 "Init" 4095 "Error";
VAL_ 1155 MO_Powermeter_untere_E_Limit 4094 "Init" 4095 "Error";
VAL_ 1155 MO_Powermeter_Upper_E_Limit 4094 "Init" 4095 "Error";
VAL_ 1175 PH_Visualisierung 0 "Off" 1 "Angefragt" 2 "InDisplay" 3 "Abgefordert" 6 "Init" 7 "Error";
VAL_ 1175 PDC_Tonausgabe_Front 0 "No_Tone" 1 "IntervalTone_1" 2 "IntervalTone_2" 3 "IntervalTone_3" 4 "IntervalTone_4" 5 "IntervalTone_5" 6 "DurationTone" 7 "ErrorTone" 8 "RCTATone";
VAL_ 1175 PDC_Tonausgabe_Rear 0 "No_Tone" 1 "IntervalTone_1" 2 "IntervalTone_2" 3 "IntervalTone_3" 4 "IntervalTone_4" 5 "IntervalTone_5" 6 "DurationTone" 7 "ErrorTone" 8 "Erstwarnton_Rear" 9 "RCTATone";
VAL_ 1175 PH_Retrofit_Stop_Req 0 "Not_Requested" 1 "Requested";
VAL_ 1175 PH_ShutoffCause 0 "No, bzw. System Active" 1 "Shutdown By Herausnahme R-Gear" 2 "Shutdown Over Speed" 3 "Shutdown Over PDC-PushButton" 4 "Shutdown DueTo PLA" 5 "Shutdown By TERM 15 Bit = 0" 6 "tbd." 7 "Error-/Disturbed State, System Yet Active";
VAL_ 1175 PH_Opt_Display_V_On 0 "Optical Display Front Not Active" 1 "Optical Display Front Activated";
VAL_ 1175 PH_Opt_Display_H_On 0 "Optical Display Off" 1 "Optical Display Rear Activated";
VAL_ 1175 PH_Opt_Disp_V_Obstacle 0 "Optical Display Front Reports No Obstacle" 1 "Optical Display Front Reports Obstacle In WarnRange";
VAL_ 1175 PH_Opt_Disp_H_Obstacle 0 "Optical Display Rear Reports No Obstacle" 1 "Optical Display Rear Reports Obstacle In WarnRange";
VAL_ 1175 PH_ToneSender_V_Active 0 "ToneSender Front Not Active" 1 "ToneSender Front  Active";
VAL_ 1175 PH_ToneSender_H_Active 0 "ToneSender Rear Not Active" 1 "ToneSender Rear Active";
VAL_ 1175 PH_ToneSender_Mute 0 "ToneSender Not stummgeschaltet" 1 "ToneSender stummgeschaltet";
VAL_ 1175 PH_Req_AudioDucking 0 "No_AudioDucking" 1 "Request_AudioDucking";
VAL_ 1175 PH_ToneSender_H_Available 0 "Not Available" 1 "Available";
VAL_ 1175 PLA_Req_OpenShift_RVC 0 "No_RVC_OpenShiftReq" 1 "RVC_OpenShiftRequest";
VAL_ 1175 PH_PushButton 0 "PushButton_Not_Pressed" 1 "PushButton_Pressed" 2 "Reserved" 3 "Error";
VAL_ 1175 PH_Req_Roof 0 "RoofOperation_Enabled" 1 "RoofOperation_sperren" 2 "Reserved" 3 "Reserved";
VAL_ 1175 PH_StartStop_Info 0 "EngineRunning_Not_Necessary_(StopEnable)" 1 "EngineStartUp_Not_Mandatory_Necessary_(StopInhibit,No_StartRequest)" 2 "EngineStartUp_Mandatory_Necessary_(StartRequest)" 3 "SystemError";
VAL_ 1175 PH_Stoermeldung 0 "No_Display_No_Chime" 1 "TextMessage_PDC_Rear_Disturbed_With_Chime" 2 "TextMessage_PDC_Rear_Disturbed_Without_Chime" 3 "TextMessage_PDC_Front_Disturbed_With_Chime" 4 "TextMessage_PDC_Front_Disturbed_Without_Chime" 5 "TextMessage_PDC_Disturbed_With_Chime" 6 "TextMessage_PDC_Disturbed_Without_Chime" 7 "TextMessage_PDC_Lateral_Disturbed_With_Chime" 8 "TextMessage_PDC_Lateral_Disturbed_Without_Chime";
VAL_ 1175 PH_Defective 0 "PH Active" 1 "PH Was DueTo eines Defektes Deactivated";
VAL_ 1175 PH_Disturbed 0 "PH Active" 1 "PH Was Open Grund A Malfunction tempraer Deactivated";
VAL_ 1175 PH_Systemzustand 0 "System Off" 1 "System By Engage R-Gear Activated" 2 "System Manual By PushButton Activated" 3 "System Automatic Activated" 4 "System By ARA Activated" 6 "Init - Initialisierungsphase After Term. 15 On / Reset" 7 "Error-/Disturbed State, System Yet Active";
VAL_ 1175 PH_Display_Kundenwunsch 0 "Display Off" 1 "Grafik" 2 "Rear View" 3 "Automatic";
VAL_ 1283 HVK_ActualMode_Req 0 "Not_Requested" 1 "Requested";
VAL_ 1283 HVK_TN1_TargetMode 0 "HV_Off" 1 "HV_On" 2 "Reserved" 3 "Initialisation";
VAL_ 1283 HVK_MO_EmTargetState 0 "HvOff" 1 "HvStbyReq" 2 "HvStbyWait" 3 "HvBattOnReq" 4 "HvBattOnWait" 10 "HvOnIdle" 18 "HvOnDrvReq" 19 "HvOnDrvWait" 20 "HvOnDrvRdy" 28 "HvStepUpReq" 29 "HvStepUpWait" 30 "HvStepUp" 38 "HvStepDownReq" 39 "HvStepDownWait" 40 "HvStepDown" 46 "HvAcChPreReq" 47 "HvAcChPreWait" 48 "HvAcChReq" 49 "HvAcChWait" 50 "HvAcCh" 56 "HvDcChPreReq" 57 "HvDcChPreWait" 58 "HvDcChReq" 59 "HvDcChWait" 60 "HvDcCh" 67 "HvChOffReq" 68 "HvChOffWait" 69 "HvOnIdleReq" 70 "HvOnIdleWait" 96 "HvCpntOffReq" 97 "HvCpntOffWait" 98 "HvBattOffReq" 99 "HvBattOffWait" 109 "HvDcDcFailOffReq" 110 "HvDcDcFail" 119 "HvElmOffReq" 120 "HvElmOff" 126 "HvFailCpntOffReq" 127 "HvFailCpntOffWait" 128 "HvFailBattOffReq" 129 "HvFailBattOffWait" 130 "HvFailBattOff" 138 "HvFailUCtlReq" 139 "HvFailUCtlWait" 140 "HvFailUCtl" 150 "HvEmgcyOff" 255 "Init";
VAL_ 1283 HVK_BMS_TargetMode 0 "HV_Off" 1 "HV_On" 3 "AC_Charging_Ext" 4 "AC_Charging" 6 "DC_Charging" 7 "Init";
VAL_ 1283 HVK_DCDC_TargetMode 0 "Standby" 1 "HV_On_BeforeCharging" 2 "Lower" 3 "HighSet" 4 "Pruefpuls_12V" 7 "Initialisation";
VAL_ 1283 HVK_EKK_TargetMode 0 "No_Enable" 1 "Enable" 2 "Enable_ausgesetzt" 7 "Init";
VAL_ 1283 HVK_HVPTC_TargetMode 0 "No_Enable" 1 "Enable" 2 "Enable_ausgesetzt" 7 "Init";
VAL_ 1283 HVK_HVLM_TargetMode 0 "No_Enable" 1 "Enable_Lademanager" 2 "BeforeCharge_AC_Path" 7 "Init";
VAL_ 1283 HVK_HV_Network_Warnings 0 "No_Warning" 1 "WarningText_HV_Network_Req" 2 "Fehlertext_HV_Network_Req" 3 "Warning_No_Restart_Possible";
VAL_ 1283 HV_VehicleElectrics_Active 0 "Inactive" 1 "Active";
VAL_ 1283 HV_VehicleElectrics_Error 0 "No_Error" 1 "Error";
VAL_ 1283 HVK_Gesamtst_Spgfreiheit 0 "Function_Init__Without_Function" 1 "HV_System_VoltageFree" 2 "HV_System_Not_VoltageFree" 3 "Error";
VAL_ 1283 HVK_ActiveEntladung_Req 0 "Not_Requested" 1 "Requested";
VAL_ 1283 HVK_Iso_Measurement_Start 0 "No_Measurement" 1 "Measurement_HV_Network_1" 2 "Measurement_HV_Network_2" 4 "Deactivated";
VAL_ 1283 HVK_DCDC_EKK_TargetMode 0 "Off" 1 "On" 2 "Reserved" 3 "Init";
VAL_ 1312 LoGeWa_Event_ClusterWarning 0 "Init" 1 "Unfall" 2 "Traktionsverlust" 3 "Panne" 4 "Sichtbehinderung" 5 "Aquaplaning";
VAL_ 1312 FROM_Request_eCall 0 "No_Request" 1 "Request";
VAL_ 1312 FROM_Impact_Side_Passenger 0 "No_Impact" 1 "Impact_Detected";
VAL_ 1312 FROM_Impact_Rollover 0 "No_Impact" 1 "Impact_Detected";
VAL_ 1312 FROM_Impact_FGS 0 "No_Impact" 1 "Impact_Detected";
VAL_ 1312 FROM_Impact_Front_Passenger 0 "No_Impact" 1 "Impact_Detected";
VAL_ 1312 FROM_Impact_Front_Driver 0 "No_Impact" 1 "Impact_Detected";
VAL_ 1312 FROM_Impact_Rear_Passenger 0 "No_Impact" 1 "Impact_Detected";
VAL_ 1312 FROM_Impact_Rear_Driver 0 "No_Impact" 1 "Impact_Detected";
VAL_ 1312 FROM_WrapFold_Row2_MI 0 "Not_Fitted" 1 "Not_Available__Error_Or_Init" 2 "Not_Locked" 3 "Locked";
VAL_ 1312 FROM_Occupancy_VB 0 "Not_Available" 1 "Error" 2 "Not_Occupied" 3 "Occupied";
VAL_ 1312 FROM_ShutoffReq_SIH_BF 0 "NormalOperation" 1 "Shutdown_Requested";
VAL_ 1312 FROM_Impact_Side_Driver 0 "No_Impact" 1 "Impact_Detected";
VAL_ 1312 SC_PAO_Schriftzug_Req 0 "LED Off" 1 "LED On" 2 "LED Flash" 3 "Reserved";
VAL_ 1312 SC_PAO_ON_Req 0 "LED Off" 1 "LED On" 2 "LED Flash" 3 "Reserved";
VAL_ 1312 SC_PAO_OFF_Req 0 "LED Off" 1 "LED On" 2 "LED Flash" 3 "Reserved";
VAL_ 1312 FROM_CrashSeverity 0 "No_Ereignis" 1 "CrashSeverity_1" 2 "CrashSeverity_2" 3 "CrashSeverity_3" 4 "CrashSeverity_4" 5 "CrashSeverity_5" 6 "CrashSeverity_2_To_5" 7 "Error";
VAL_ 1312 FROM_Request_USM 0 "No_Request" 1 "Request";
VAL_ 1312 FROM_BeltBuckle_FA 0 "Not_Fitted" 1 "Not_Available (Error Or Init)" 2 "Not_Inserted" 3 "Inserted";
VAL_ 1312 FROM_BeltBuckle_BF 0 "Not_Fitted" 1 "Not_Available (Error Or Init)" 2 "Not_Inserted" 3 "Inserted";
VAL_ 1312 FROM_BeltBuckle_Row2_FA 0 "Not_Fitted" 1 "Not_Available (Error Or Init)" 2 "Not_Inserted" 3 "Inserted";
VAL_ 1312 FROM_BeltBuckle_Row2_MI 0 "Not_Fitted" 1 "Not_Available (Error Or Init)" 2 "Not_Inserted" 3 "Inserted";
VAL_ 1312 FROM_BeltBuckle_Row2_BF 0 "Not_Fitted" 1 "Not_Available (Error Or Init)" 2 "Not_Inserted" 3 "Inserted";
VAL_ 1312 FROM_BeltBuckle_Row3_FA 0 "Not_Fitted" 1 "Not_Available (Error Or Init)" 2 "Not_Inserted" 3 "Inserted";
VAL_ 1312 FROM_BeltBuckle_Row3_MI 0 "Not_Fitted" 1 "Not_Available (Error Or Init)" 2 "Not_Inserted" 3 "Inserted";
VAL_ 1312 FROM_BeltBuckle_Row3_BF 0 "Not_Fitted" 1 "Not_Available (Error Or Init)" 2 "Not_Inserted" 3 "Inserted";
VAL_ 1312 FROM_SeatPos_Sens_FA 0 "Not Available" 1 "Error" 2 "Seat Not Front" 3 "Seat Front";
VAL_ 1312 FROM_SeatPos_Sens_BF 0 "Not Available" 1 "Error" 2 "Seat Not Front" 3 "Seat Front";
VAL_ 1312 FROM_WrapFold_Row2_BF 0 "Not_Fitted" 1 "Not_Available__Error_Or_Init" 2 "Not_Locked" 3 "Locked";
VAL_ 1312 FROM_WrapFold_Row2_FA 0 "Not_Fitted" 1 "Not_Available__Error_Or_Init" 2 "Not_Locked" 3 "Locked";
VAL_ 1349 FROM_BeltWarn_Row2_FA 0 "Not_Fitted" 1 "No_BeltWarning_Seat_Empty" 2 "No_BeltWarning_Seat_Occupied" 3 "BeltWarning_Seat_Occupied";
VAL_ 1349 FROM_BeltWarn_Row2_BF 0 "Not_Fitted" 1 "No_BeltWarning_Seat_Empty" 2 "No_BeltWarning_Seat_Occupied" 3 "BeltWarning_Seat_Occupied";
VAL_ 1349 AbstWarn_MV_FAS_Func_Status 0 "Init" 1 "Function_Actual_On" 2 "Function_Actual_Off" 3 "Error";
VAL_ 1349 WarnBrake_Charisma_Status 0 "Init" 1 "Available" 2 "Not Available" 3 "Asynchronous By DriverDemand";
VAL_ 1349 WarnBrake_Charisma_DrivePr 0 "No_Function" 1 "Programm_1" 2 "Programm_2" 3 "Programm_3" 4 "Programm_4" 5 "Programm_5" 6 "Programm_6" 7 "Programm_7" 8 "Programm_8" 9 "Programm_9" 10 "Programm_10" 11 "Programm_11" 12 "Programm_12" 13 "Programm_13" 14 "Programm_14" 15 "Programm_15";
VAL_ 1349 FROM_BeltWarn_Row2_MI 0 "Not_Fitted" 1 "No_BeltWarning_Seat_Empty" 2 "No_BeltWarning_Seat_Occupied" 3 "BeltWarning_Seat_Occupied";
VAL_ 1349 FROM_BeltWarn_Row3_FA 0 "Not_Fitted" 1 "No_BeltWarning_Seat_Empty" 2 "No_BeltWarning_Seat_Occupied" 3 "BeltWarning_Seat_Occupied";
VAL_ 1349 FROM_BeltWarn_Row3_MI 0 "Not_Fitted" 1 "No_BeltWarning_Seat_Empty" 2 "No_BeltWarning_Seat_Occupied" 3 "BeltWarning_Seat_Occupied";
VAL_ 1349 FROM_BeltWarn_Row3_BF 0 "Not_Fitted" 1 "No_BeltWarning_Seat_Empty" 2 "No_BeltWarning_Seat_Occupied" 3 "BeltWarning_Seat_Occupied";
VAL_ 1349 LGI_FAS_Func_Status 0 "Init" 1 "Function_Actual_On" 2 "Function_Actual_Off" 3 "Error";
VAL_ 1349 PreCrash_FAS_Func_Status 0 "Init" 1 "Function_Actual_On" 2 "Function_Actual_Off" 3 "Error";
VAL_ 1349 FROM_SBR_Rear_Fitment 0 "Without_SBR_Rear" 1 "With_SBR_Rear" 2 "Not_Defined" 3 "Init";
VAL_ 1349 AWV_OnPosition_System_ASG 0 "Deactivated" 1 "Activated";
VAL_ 1349 AWV_OnPosition_Warning_ASG 0 "Off" 1 "Setting_2" 2 "Setting_3" 3 "Setting_4" 4 "Setting_5" 5 "On";
VAL_ 1349 SC_PreSense_Mode_Warning_NV 0 "Off" 1 "Setting_2" 2 "Setting_3" 3 "Setting_4" 4 "Setting_5" 5 "On";
VAL_ 1349 SC_PreSense_Mode_Warning_MV 0 "Off" 1 "Setting_2" 2 "Setting_3" 3 "Setting_4" 4 "Setting_5" 5 "On";
VAL_ 1349 SC_PreSense_Mode_System_MV 0 "Deactivated" 1 "Activated";
VAL_ 1349 SC_PreSense_Mode_System_NV 0 "Deactivated" 1 "Activated";
VAL_ 1349 SC_PreSense_Mode_System_KAS 0 "Deactivated" 1 "Activated";
VAL_ 1355 PH_Verschmutzungsmeldung 0 "No_Display_No_Chime" 1 "TextMessage_PDC_Rear_Dirty_With_Chime" 2 "TextMessage_PDC_Rear_Dirty_Without_Chime" 3 "TextMessage_PDC_Front_Dirty_With_Chime" 4 "TextMessage_PDC_Front_Dirty_Without_Chime" 5 "TextMessage_PDC_Dirty_With_Chime" 6 "TextMessage_PDC_Dirty_Without_Chime" 7 "TextMessage_PDC_Lateral_Dirty_With_Chime" 8 "TextMessage_PDC_Lateral_Dirty_Without_Chime";
VAL_ 1355 PH_OpenShiftCause 0 "System Off" 1 "System By Engage R-Gear Activated" 2 "System Manual By PushButton Activated" 3 "System Automatic Activated" 4 "System By ARA Activated" 5 "RollBack" 6 "System_By_PLA_Activated" 7 "System_By_IPA_Activated" 8 "System_By_FA_Activated" 9 "System_By_RBF_Or_MA_Activated" 10 "System_By_Smartphone_Activated" 11 "System_By_Jokertaste_Activated" 12 "System_By_Favoritentasten_Activated" 13 "System_By_SideViewPushButton_Activated" 14 "System_By_RCTA_Activated" 15 "System_By_KAS_Activated" 16 "System_By_AWC_Activated" 30 "Init_Initialisierungsphase_After_Term_15_On_Or_Reset" 31 "Error_gestoerter_State_System_Yet_Active";
VAL_ 1355 PH_Tone_Ausgabe 0 "Init" 1 "IntervalTone_Front" 2 "IntervalTone_Rear" 3 "DurationTone_Front" 4 "DurationTone_Rear" 5 "Quittierungston" 6 "Reserved" 7 "Error";
VAL_ 1355 PH_Tone_Pausenlaenge 0 "Init" 1 "Pause_5ms" 2 "Pause_10ms" 3 "Pause_15ms" 100 "Pause_500ms" 101 "Reserved" 126 "Reserved" 127 "Error";
VAL_ 1355 PH_Tone_Direction 0 "Front" 1 "Front_Right" 2 "Right" 3 "Right_Rear" 4 "Rear" 5 "Rear_Left" 6 "Left" 7 "Front_Left";
VAL_ 1355 PH_Tone_Volume 0 "Minimallautstaerke" 1 "Volume_1" 2 "Volume_2" 3 "Volume_3" 4 "Volume_4" 5 "Volume_5" 6 "Volume_6" 7 "MaximumVolume";
VAL_ 1355 BCM_WAH_Meldung 0 "Init" 1 "Fehlermeldung_At_NotAvailability_With_Chime" 2 "Fehlermeldung_At_NotAvailability_Without_Chime" 3 "Display_dass_Vehicle_Detected_Was_And_Function_Active_Actual" 4 "Wiederanfahrhinweis_With_Chime" 5 "Wiederanfahrhinweis_Without_Chime";
VAL_ 1355 PDC_Charisma_Status 0 "Init" 1 "Available" 2 "Not_Available" 3 "Asynchronous_By_DriverDemand";
VAL_ 1355 PDC_Charisma_DrivePr 0 "No_Function" 1 "Programm_1" 2 "Programm_2" 3 "Programm_3" 4 "Programm_4" 5 "Programm_5" 6 "Programm_6" 7 "Programm_7" 8 "Programm_8" 9 "Programm_9" 10 "Programm_10" 11 "Programm_11" 12 "Programm_12" 13 "Programm_13" 14 "Programm_14" 15 "Programm_15";
VAL_ 1361 WFS_Key_DriveAuthorisation 0 "No Authorised Key Detected" 1 "Active_RemoteKey_Nr_01" 2 "Active_RemoteKey_Nr_02" 3 "Active_RemoteKey_Nr_03" 4 "Active_RemoteKey_Nr_04" 5 "Active_RemoteKey_Nr_05" 6 "Active_RemoteKey_Nr_06" 7 "Active_RemoteKey_Nr_07" 8 "Active_RemoteKey_Nr_08" 9 "Invalid_09" 10 "Invalid_10" 11 "Invalid_11" 12 "Invalid_12" 13 "Invalid_13" 14 "Invalid_14" 15 "digitaler_Key_Active";
VAL_ 1361 WFS_ID_Geb_Authorised 0 "Key_Not_Authorised" 1 "Key Authorised";
VAL_ 1361 WFS_ID_Geb_Authorised_in_Term15 0 "Not_Authorised_in_Term15" 1 "Authorised_in_Term15";
VAL_ 1361 WFS_ID_Geb_Inserted 0 "No_Key_In_IgnitionLock" 1 "Key Inserted In IgnitionLock";
VAL_ 1361 WFS_Key_Target 0 "Init";
VAL_ 1361 WFS_Key_Actual 0 "Init";
VAL_ 1361 WFS_Safe 0 "Init" 1 "WFS Not Deactivated";
VAL_ 1361 WFS_LZ 0 "Not def." 1 "LZ 1" 2 "LZ 2" 3 "LZ 3";
VAL_ 1361 WFS_ELV_Authorised 0 "ELV_Not_Authorised" 1 "ELV_Authorised";
VAL_ 1361 WFS_LF_Active 0 "Funktempfang_Not_Active" 1 "LF_RadioReception_Active";
VAL_ 1361 WFS_Operation_ReadCoil 0 "No_KeyComm_ReadCoil" 1 "KeyComm_ReadCoil";
VAL_ 1361 WFS_TerminalsEnable 0 "No_Enable" 1 "Enable";
VAL_ 1361 WFS_DriverNotices 0 "No_DisplayRequest" 1 "Schuessel_Auth_niO" 2 "LimpHome_Active" 3 "Key_Kessy_Not_gefunden";
VAL_ 1361 WFS_Parking_Status 0 "Limitation_Inactive" 1 "Limitation_Active" 2 "Abort";
VAL_ 1411 BCM_FH_Enable 1 "FunctionEnable WindowLifter";
VAL_ 1411 BCM_ComfortFunc_Enable 0 "ComfortFunction Locked" 1 "globale Enable The ComfortFunction erteilt";
VAL_ 1411 BCM_HSK_Enable 0 "erlauben" 1 "sperren";
VAL_ 1411 BCM_Roof_Enable 0 "RoofOperation Not Allowed" 1 "RoofOperation Allowed";
VAL_ 1411 ZV_Locked_Internal_Actual 1 "Fahrzeug innen verriegelt; Istzustand";
VAL_ 1411 ZV_Locked_External_Actual 1 "Vehicle_Outside_Locked_ActualState";
VAL_ 1411 ZV_Locked_Internal_Target 1 "Fahrzeug verriegelt intern; Sollzusstand";
VAL_ 1411 ZV_Locked_External_Target 1 "Fahrzeug verriegelt extern; Sollzusstand";
VAL_ 1411 ZV_Safed_External_Actual 1 "Fahrzeug aussen gesafet; Istzustand";
VAL_ 1411 ZV_Safed_External_Target 1 "Vehicle_Outside_Safed_TargetState";
VAL_ 1411 ZV_Einzeltuerentriegelung 1 "Vehicle On Einzeltuer Unlocked";
VAL_ 1411 ZV_Heckeinzelentriegelung 1 "Heckdeckeleinzelentriegelung";
VAL_ 1411 ZV_FT_Open 0 "FT_Closed" 1 "FT_Opened";
VAL_ 1411 ZV_BT_Open 0 "BT_Closed" 1 "BT_Opened";
VAL_ 1411 ZV_HFS_Open 0 "Closed" 1 "Open";
VAL_ 1411 ZV_HBFS_Open 0 "Closed" 1 "Open";
VAL_ 1411 ZV_HD_Open 1 "Tailgate_Open";
VAL_ 1411 ZV_HS_Open 0 "RearWindow_Closed" 1 "RearWindow Open";
VAL_ 1411 IRUE_Active 0 "unscharf" 1 "scharf";
VAL_ 1411 DWA_Active 0 "unscharf" 1 "scharf";
VAL_ 1411 HD_MainDetent 0 "Closed" 1 "Open";
VAL_ 1411 HD_PreDetent 0 "Closed" 1 "Open";
VAL_ 1411 FFB_CarFinder 0 "Not Active" 1 "Active";
VAL_ 1411 FFB_ComfortOpen 0 "No_ComfortOpen_Received" 1 "ComfortOpen Over Radio Received";
VAL_ 1411 FFB_ComfortClose 0 "No_ComfortClose_Received" 1 "ComfortClose Over Radio Received";
VAL_ 1411 ZV_Key_Zugang 0 "No_auth_Key_Detected" 1 "Active_RemoteKey_Nr_01" 2 "Active_RemoteKey_Nr_02" 3 "Active_RemoteKey_Nr_03" 4 "Active_RemoteKey_Nr_04" 5 "Active_RemoteKey_Nr_05" 6 "Active_RemoteKey_Nr_06" 7 "Active_RemoteKey_Nr_07" 8 "Active_RemoteKey_Nr_08" 9 "Invalid_09" 10 "Invalid_10" 11 "Invalid_11" 12 "Invalid_12" 13 "Invalid_13" 14 "Invalid_14" 15 "Invalid_15";
VAL_ 1411 ZV_SafeFunction_Active 0 "Inactive" 1 "Active";
VAL_ 1411 FBS_Warn_Key_Batt 0 "i.O." 1 "Defective";
VAL_ 1411 ZV_OpeningMode 0 "globale_Opening" 1 "ZV_With_Einzeltuerentr" 2 "ZV_individuell_selektiv" 3 "ZV_seitenselektiv";
VAL_ 1411 HFS_Locked 0 "Not_Locked" 1 "Locked";
VAL_ 1411 HFS_Safed 0 "Not_Safed" 1 "Safed";
VAL_ 1411 HBFS_Locked 0 "Not_Locked" 1 "Locked";
VAL_ 1411 HBFS_Safed 0 "Not_Safed" 1 "Safed";
VAL_ 1411 ZV_Actual_State_Available 0 "Not_Available" 1 "Available_All_TSGs_At_Bus";
VAL_ 1411 IRUE_PushButton_Fkts_LED 0 "LED_Off" 1 "LED_On";
VAL_ 1411 ZV_FuelFlap_Open 0 "FuelFlap_Closed" 1 "FuelFlap_Open";
VAL_ 1411 ZV_Blind_Open 0 "Inactive" 1 "Active";
VAL_ 1411 ZV_Blind_Closed 0 "Inactive" 1 "Active";
VAL_ 1411 ZV_SAD_Open 0 "Inactive" 1 "Active";
VAL_ 1411 ZV_SAD_Closed 0 "Inactive" 1 "Active";
VAL_ 1411 BCM_FuelFlapActuator_Error 0 "No_Error" 1 "Error";
VAL_ 1411 ZV_Locked_Target 0 "Init" 1 "Not_Locked" 2 "Locked";
VAL_ 1413 SI_Collective_ECU_Error 61 "Reserved" 62 "Overflow" 63 "Invalid";
VAL_ 1413 SI_Diagnostics_Active 0 "Inactive" 1 "Active";
VAL_ 1413 SI_QRS_Mode 0 "QRS_MeasureMode_Not_Active" 1 "QRS_MeasureMode_Active";
VAL_ 1413 SI_T_Mode 0 "TransportMode_Not_Active" 1 "TransportMode_Active";
VAL_ 1413 SI_NWDF 0 "Monitoring_Not_Enabled" 1 "Monitoring_Enabled";
VAL_ 1413 SI_NWDF_Valid 0 "NWDF_Is_Not_Supported" 1 "NWDF_Is_Supported";
VAL_ 1413 SI_GeneralFault 0 "No_GeneralFault" 1 "GeneralFault";
VAL_ 1413 GW_KD_Error 0 "No_KD_Error" 1 "KD_Error";
VAL_ 1413 SI_T_Protection 0 "Transportschutz_Not_Active" 1 "Transportschutz_Active";
VAL_ 1413 SI_BUS_01 0 "No_BusIdle" 1 "BusIdle";
VAL_ 1413 SI_BUS_02 0 "No_BusIdle" 1 "BusIdle";
VAL_ 1413 SI_BUS_03 0 "No_BusIdle" 1 "BusIdle";
VAL_ 1413 SI_BUS_04 0 "No_BusIdle" 1 "BusIdle";
VAL_ 1413 SI_BUS_05 0 "No_BusIdle" 1 "BusIdle";
VAL_ 1413 SI_BUS_06 0 "No_BusIdle" 1 "BusIdle";
VAL_ 1413 SI_BUS_07 0 "No_BusIdle" 1 "BusIdle";
VAL_ 1413 SI_BUS_08 0 "No_BusIdle" 1 "BusIdle";
VAL_ 1413 SI_BUS_09 0 "No_BusIdle" 1 "BusIdle";
VAL_ 1413 SI_BUS_10 0 "No_BusIdle" 1 "BusIdle";
VAL_ 1413 SI_BUS_11 0 "No_BusIdle" 1 "BusIdle";
VAL_ 1413 SI_BUS_12 0 "No_BusIdle" 1 "BusIdle";
VAL_ 1413 SI_BUS_13 0 "No_BusIdle" 1 "BusIdle";
VAL_ 1413 SI_BUS_14 0 "No_BusIdle" 1 "BusIdle";
VAL_ 1413 SI_BUS_15 0 "No_BusIdle" 1 "BusIdle";
VAL_ 1413 SI_Bus_Identifikation 16 "CAN_Diagnostics" 17 "CAN_Drive" 18 "CAN_Comfort" 19 "CAN_Infotainment" 20 "CAN_Chassis" 21 "CAN_Extended" 22 "CAN_Hybrid" 23 "CAN_Charge" 24 "CAN_Cluster" 25 "CAN_Comfort_2" 26 "CAN_AFS" 33 "CAN_DriverAssistenzSysteme" 34 "CAN_Migration" 35 "CAN_Connect" 36 "CAN_DisplayOperation" 37 "CAN_ElectricalVehicle" 40 "CAN_Telematics" 41 "CAN_MFL" 42 "CAN_DriverAssistenzSysteme_2" 48 "FlexRay_A" 49 "FlexRay_B" 97 "VLAN_FAS" 98 "VLAN_Infotainment" 99 "VLAN_Connect" 100 "VLAN_Comfort" 101 "VLAN_Drive" 102 "VLAN_Diagnostics" 103 "VLAN_Internet" 104 "VLAN_Gateway" 105 "VLAN_Remote_FC" 106 "VLAN_Connect_2" 107 "VLAN_Light" 108 "VLAN_Charge" 109 "VLAN_Cockpit" 176 "HCP1_CANFD01" 177 "HCP1_CANFD02" 178 "HCP1_CANFD03" 179 "HCP1_CANFD04" 180 "HCP1_CANFD05" 181 "HCP1_CANFD06" 182 "HCP1_CANFD07" 183 "HCP1_CANFD08" 186 "HCP4_CANFD03" 187 "HCP4_CANFD04" 188 "HCP1_CANFD09" 189 "HCP4_CANFD06" 190 "HCP4_CANFD07" 191 "HCP4_CANFD08" 192 "HCP4_CANFD09" 193 "HCP4_CANFD10" 194 "HCP1_CANFD10" 195 "ICAS1_CANFD2_HCP5_CANFD02" 196 "HCP1_CANFD11" 197 "WU_HCP1_CANFD" 198 "WU_HCP2_1_CANFD" 199 "WU_HCP_2_CANFD" 200 "WU_HCP_3_CANFD" 201 "WU_HCP4_CANFD" 202 "WU_HCP3_CANFD02" 204 "ESC_CANFD" 205 "HCP4_CANFD11" 206 "HCP4_CANFD12" 207 "HCP5_CANFD04" 208 "HCP5_CANFD05" 212 "WU_ConMod_CANFD" 213 "WU_PASD_CANFD";
VAL_ 1413 SI_CAB 0 "Inactive" 1 "CAB_01__Doors" 2 "CAB_02__Trailer" 4 "CAB_03__Nightvision" 8 "CAB_04__SeatAdjustment" 16 "CAB_05__Fold" 32 "CAB_06__Infotainment" 64 "CAB_07__Sub_Infotainment" 128 "CAB_08__Display" 256 "CAB_09__Charging" 512 "CAB_10__Climate" 1024 "CAB_11__FlexRay" 262144 "CAB_19_VLAN_Remote_FC" 524288 "CAB_20_VLAN_Comfort";
VAL_ 1420 KST_Txt_P_Gear 0 "Off" 1 "On";
VAL_ 1420 KST_Txt_PanicShutdown 0 "Off" 1 "On";
VAL_ 1420 KST_Req_TerminalsEnable_ELV 0 "Not_Requested" 1 "Requested";
VAL_ 1420 KST_Txt_ComfortShutdown 0 "Inactive" 1 "Active";
VAL_ 1420 KST_ZAT_Pressed 0 "Off" 1 "On";
VAL_ 1420 KST_Unterdr_IgnitionReport 0 "No_Unterdr_The_IgnitionReport" 1 "Unterdr_The_IgnitionReport_Active";
VAL_ 1420 KST_aut_Shutdown_Ignition 0 "Ignition_Is_At_Verl_Not_Deactivated" 1 "Ignition_Is_At_Verl_Deactivated";
VAL_ 1420 KST_Req_ZV_Locking 0 "Inactive" 1 "Active";
VAL_ 1420 Relay_VoKo_Actuated 0 "Not_Actuated" 1 "Actuated";
VAL_ 1420 RSt_Request_HMS 0 "No_Request" 1 "Hold" 2 "Parking" 3 "Hold_Standby" 4 "PullAway" 5 "Release_Over_Ramp" 6 "Parking_With_P";
VAL_ 1440 LS_Brightness_IR 254 "Init" 255 "Error";
VAL_ 1440 LS_Brightness_FW 1022 "Init" 1023 "Error";
VAL_ 1440 LS_Defective 0 "OK" 1 "Defective";
VAL_ 1440 LS_Fitment 0 "Init" 1 "Lichtsensor_Fitted";
VAL_ 1440 RS_RainQuantity 14 "Init" 15 "Error";
VAL_ 1440 RS_Fitment 0 "Init" 1 "Regensensor Fitted";
VAL_ 1440 RS_Glazing_Close 0 "Glazing Not Close" 1 "Glazing Close";
VAL_ 1440 RS_Defective 0 "OK" 1 "Defective";
VAL_ 1440 RS_WiperSpeed 0 "No Wipe" 1 "42 Strokes/min" 2 "45 Strokes/min" 3 "48 Strokes/min" 4 "51 Strokes/min" 5 "54 Strokes/min" 6 "57 Strokes/min" 7 "60 Strokes/min";
VAL_ 1440 RLS_BeforeFieldBrightness_Boost 0 "Greater_24413_Lux" 1 "To_24413_Lux" 2 "To_22193_Lux" 3 "To_20176_Lux" 4 "To_18342_Lux" 5 "To_16647_Lux" 6 "To_15158_Lux" 7 "To_13780_Lux" 8 "To_12527_Lux" 9 "To_11388_Lux" 10 "To_10353_Lux" 11 "To_9412_Lux" 12 "To_8556_Lux" 13 "To_7778_Lux" 14 "To_7071_Lux" 15 "To_6428_Lux";
VAL_ 1442 BMS_Status_ServiceDisconnect 0 "Inserted" 1 "gezogen";
VAL_ 1442 BMS_Status_Spgfreiheit 0 "Init" 1 "HV_Component_VoltageFree" 2 "HV_Compressor_Not_VoltageFree" 3 "Error_Not_VoltageFree";
VAL_ 1442 BMS_OBD_Lamp_Req 0 "No_MIL_Request" 1 "MIL_Request";
VAL_ 1442 BMS_ActualMode 0 "HV_Inactive" 1 "Drive_HV_Active" 2 "StBalancing" 3 "externes_Charging" 4 "AC_Charging" 5 "Error_Batt" 6 "DC_Charging" 7 "Init";
VAL_ 1442 BMS_ErrorStatus 0 "Component_IO" 1 "Restricted_CompressorFunc_Isofehler_I" 2 "Restricted_CompressorFunc_Isofehler_II" 3 "Restricted_CompressorFunc_Interlock" 4 "Restricted_CompressorFunc_SD" 5 "Restricted_CompressorFunc_Leistungsred" 6 "No_ComponentFunction" 7 "Init";
VAL_ 1442 BMS_Kapazitaet_02 2047 "Init";
VAL_ 1442 BMS_Target_SOC_HiRes 2046 "Init" 2047 "Error";
VAL_ 1447 TM_Mirror_FoldIn 0 "Init" 1 "Mirror_FoldIn";
VAL_ 1447 TM_Only_Hupen 0 "Inactive" 1 "Active";
VAL_ 1447 TM_Door_Lock 0 "Init" 1 "door_lock";
VAL_ 1447 TM_Door_Unlock 0 "Init" 1 "door_unlock";
VAL_ 1447 TM_HazardFlash 0 "Init" 1 "HazardFlash_on";
VAL_ 1447 TM_Panic_Alarm 0 "Init" 1 "Panic_alarm_on";
VAL_ 1447 TM_ZV_Signature 0 "Init";
VAL_ 1452 HVEM_ActualCurrent_HVConsumer 4094 "Init" 4095 "Error";
VAL_ 1452 HVEM_Energy_Climate_Specification_HighR 6 "Init" 7 "Error";
VAL_ 1452 HVEM_ActualPowerNA 510 "Init" 511 "Error";
VAL_ 1452 HVEM_Power_Climate_Specification 254 "Init" 255 "Error";
VAL_ 1452 HVEM_Nutzbare_Energy 2045 "Max" 2046 "Init" 2047 "Error";
VAL_ 1452 HVEM_Energy_Climate_Specification 254 "Init" 255 "Error";
VAL_ 1452 HVEM_MO_MaxPowerIgnored 0 "Max_Power_Not_Ignored" 1 "Max_Power_Ignored";
VAL_ 1485 DC_ErrorStatus 0 "Component_IO" 1 "Restricted_CompressorFunc_Entlad_Defective" 3 "Restricted_CompressorFunc_Interlock" 6 "No_ComponentFunction" 7 "Init";
VAL_ 1485 DC_PeakCurrent_Available 0 "PeakCurrent_Not_Available" 1 "PeakCurrent_Available";
VAL_ 1485 DC_Limiting_Temperature 0 "No_Limiting" 1 "Limiting_Temp";
VAL_ 1485 DC_ActualMode_02 0 "Standby" 1 "HV_On_BeforeCharging" 2 "Lower" 3 "HighSet" 4 "Pruefimpuls_12V" 5 "Error" 7 "Initialisation";
VAL_ 1485 DC_HV_EKK_ActualMode 0 "Standby" 2 "Lower" 3 "HighSet" 5 "Error" 7 "Initialisation";
VAL_ 1485 DC_Status_Spgfreiheit_HV 0 "Init" 1 "HV_Component_VoltageFree" 2 "HV_Compressor_Not_VoltageFree" 3 "Error_Not_VoltageFree";
VAL_ 1485 DC_ActualVoltage_EKK_HV 255 "Init";
VAL_ 1485 DC_Temperature 254 "Init" 255 "Error";
VAL_ 1505 BCM1_Outside_Temp_Unfilt 253 "Not_Fitted" 254 "Initwert" 255 "Error";
VAL_ 1505 BCM_HeatingShutOffValve_Status 0 "HAV_Open" 1 "HAV_Closed" 2 "Init_Or_Not_Fitted" 3 "Error";
VAL_ 1505 BCM_HeatingPump_Status 0 "Pump_Off" 1 "Pump_Active_And_Stauts_iO" 2 "Init_Or_Not_Fitted" 3 "Error";
VAL_ 1505 BCM_CompressorClutch_Status 0 "Clutch_Open" 1 "Clutch_Closed" 2 "Init_Or_Not_Fitted" 3 "Error";
VAL_ 1505 BCM1_PTC_stufig_Status 0 "Off" 1 "Stage_1_Active" 2 "Stage_2_Active" 3 "Stage_3_Active" 6 "Init_Or_Not_Fitted" 7 "Error";
VAL_ 1505 BCM1_FStatus_OutsideTemp_Unfilt 0 "iO" 1 "niO";
VAL_ 1505 BCM1_CompressorCurrent_Actual 254 "Init, bzw. Not Available" 255 "Error";
VAL_ 1505 BCM1_OBD_FStatus_ATemp 0 "No Error / Init / Not Fitted" 1 "KS- (ShortCircuit After minus)" 2 "KS+ (ShortCircuit After plus)" 3 "OC (WireBreak)" 4 "OOR+ (Signal Closed Large)" 5 "OOR- (Signal Closed Small)" 6 "RC+ (Signal Implausible Closed Large)" 7 "RC- (Signal Implausible Closed Small)" 8 "KS+/OC (ShortCircuit After plus/OpenCircuit)" 9 "KS-/OC  (ShortCircuit After minus/OpenCircuit)" 10 "KS-/KS+  (ShortCircuit After minus/plus)" 11 "KS-/KS+/OC (ShortCircuit After minus/plus/OpenCircuit)" 12 "Free" 13 "Free" 14 "Free" 15 "Free";
VAL_ 1513 DS_Refrigerant_P 2046 "Init" 2047 "Error";
VAL_ 1513 DS_Status 0 "i.O." 1 "t.b.d." 2 "Init bzw. Not Available" 3 "Error";
VAL_ 1513 ION_Status 0 "HighVoltage_SwitchedOff" 1 "HighVoltage_SwitchedOn" 2 "Init";
VAL_ 1513 ION_Status_LED 0 "Off" 1 "On";
VAL_ 1513 AAU_Blower 126 "Init" 127 "Error";
VAL_ 1513 ION_Status_PushButton 0 "Not_Pressed" 1 "Pressed";
VAL_ 1520 DI_TERM_58xd 254 "Init" 255 "Error";
VAL_ 1520 DI_TERM_58xs 126 "Init" 127 "Error";
VAL_ 1520 DI_TERM_58xt 126 "Init" 127 "Error";
VAL_ 1524 IL_Bel_FS_Exit 0 "Inactive" 1 "Active";
VAL_ 1524 IL_Bel_BFS_Exit 0 "Inactive" 1 "Active";
VAL_ 1524 IL_Bel_HFS_Exit 0 "Inactive" 1 "Active";
VAL_ 1524 IL_Bel_HBFS_Exit 0 "Inactive" 1 "Active";
VAL_ 1524 BCM1_InsideLight_gedimmt_V 0 "100% InsideLight" 1 "gedimmtes InsideLight";
VAL_ 1524 BCM1_InsideLight_gedimmt_H 0 "100% InsideLight" 1 "gedimmtes InsideLight";
VAL_ 1524 IL_InsideLight_Active 0 "InsideLight Inactive" 1 "InsideLight Active";
VAL_ 1524 IL_Terminal_30G_Active 0 "Term_30G_SwitchedOff" 1 "SwitchedOn";
VAL_ 1524 BCM1_DI_Ramp_InsideLight 0 "DimRamp 0" 1 "DimRamp 1";
VAL_ 1524 BCM1_DI_Ramp_ReadingLight 0 "DimRamp 0" 1 "DimRamp 1";
VAL_ 1524 BCM1_InsideLight_H 0 "Off" 1 "On";
VAL_ 1524 BCM1_InsideLight_V 0 "Off" 1 "On";
VAL_ 1524 BCM1_ReadingLight_Req_hl 0 "Off" 1 "On";
VAL_ 1524 BCM1_ReadingLight_Req_hr 0 "Off" 1 "On";
VAL_ 1524 BCM1_ReadingLight_Req_vl 0 "Off" 1 "On";
VAL_ 1524 BCM1_ReadingLight_Req_vr 0 "Off" 1 "On";
VAL_ 1524 BCM1_Leuchten_Off 0 "No Aenderung" 1 "Off";
VAL_ 1524 AMB_Charisma_DrivePr 0 "No_Function" 1 "Programm_1" 2 "Programm_2" 3 "Programm_3" 4 "Programm_4" 5 "Programm_5" 6 "Programm_6" 7 "Programm_7" 8 "Programm_8" 9 "Programm_9" 10 "Programm_10" 11 "Programm_11" 12 "Programm_12" 13 "Programm_13" 14 "Programm_14" 15 "Programm_15";
VAL_ 1524 AMB_Charisma_Status 0 "Init" 1 "Available" 2 "Not_Available" 3 "Asynchronous_By_DriverDemand";
VAL_ 1600 MO_QBit_IntakeAir_Temp 0 "Valid_Value" 1 "Substitute_Init_Or_ErrorValue";
VAL_ 1600 MO_QBit_Oil_Temp 0 "Valid_Value" 1 "Substitute_Init_Or_ErrorValue";
VAL_ 1600 MO_QBit_Coolant_Temp 0 "Valid_Value" 1 "Substitute_Init_Or_ErrorValue";
VAL_ 1600 MO_HYB_Error_HV_Network 0 "i_O" 1 "No_Regenerative_Operation_Possible";
VAL_ 1600 MO_Active_GearboxHeat 0 "No_Valve_Actuate" 1 "Valve_muss_Actuated_Become";
VAL_ 1600 MO_ShutOffValve_Open 0 "Not_Available" 1 "Actuation_Valve_Permitted" 2 "Valve_Open_Or_Opened" 3 "Valve_Close_Or_Closed";
VAL_ 1600 MO_IntakeAir_Temp 254 "Init" 255 "Error";
VAL_ 1600 MO_Oil_Temp 253 "Not_Fitted" 254 "Init" 255 "Error";
VAL_ 1600 MO_Coolant_Temp 254 "Init" 255 "Error";
VAL_ 1600 MO_AltitudeInfo 255 "Error";
VAL_ 1600 MO_Kennfeldk 0 "No MapCooling Present" 1 "MapCooling Present";
VAL_ 1600 MO_Gearbox_Cool 0 "Not_Cool" 1 "Cool";
VAL_ 1600 MO_HeatingPumpActuation 13 "Error" 14 "Init" 15 "Not_Fitted";
VAL_ 1600 MO_VoltageReq 0 "No_Request" 1 "Request";
VAL_ 1601 MO_Factor_Torques_02 0 "Not_Occupied";
VAL_ 1601 MO_HybridVehicle 0 "No_HybridVehicle" 1 "Mild_Hybrid" 2 "Full_Hybrid" 3 "PlugIn_Hybrid";
VAL_ 1601 MO_Gearbox_Code 0 "Init" 2 "DL501" 3 "DL800" 4 "VL381" 5 "DL382_Front" 6 "DL382_AllWheelDrive" 7 "DL702" 8 "AL552_AllWheelDrive" 9 "AL552_Front" 10 "AL651" 11 "AL551__AL951__AL1000_8A" 12 "PDK_PAG" 13 "AL551_Hybrid" 15 "ManualGearbox_konventionell" 16 "AQ250_160" 17 "AQ450" 18 "DQ200" 19 "DQ250" 20 "DQ500" 21 "SQ100" 22 "SQ200" 23 "DQ400E" 24 "DQ381" 25 "AL550" 26 "AQ300" 31 "DL800E" 32 "Single_Gear__Without_GSG_WH_At_MSG" 33 "EQ550_2P";
VAL_ 1601 MO_StartStop_Coded 0 "Start_Stop_Not_Fitted" 1 "Start_Stop_Fitted";
VAL_ 1601 MO_Count_Cyl 0 "No_Cylinder" 1 "1_Cylinder" 2 "2_Cylinder" 3 "3_Cylinder" 4 "4_Cylinder" 5 "5_Cylinder" 6 "6_Cylinder" 7 "7_Cylinder" 8 "8_Cylinder" 9 "9_Cylinder" 10 "10_Cylinder" 11 "11_Cylinder" 12 "12_Cylinder" 13 "15_Cylinder" 14 "16_Cylinder" 15 "18_Cylinder";
VAL_ 1601 MO_FuelType 0 "Diesel" 1 "Petrol_inkl_E25_E85" 2 "CNG" 3 "LPG" 4 "Hydrogen" 5 "E100_Ethanol" 15 "No_Verbrennungskraftstoff";
VAL_ 1601 MO_IntakeSystem 0 "Turbo" 1 "Sauger";
VAL_ 1601 MO_DPF_Fitted 0 "No_DPF_Fitted" 1 "DPF_Fitted";
VAL_ 1601 TSK_Coding 0 "No_Fahrgeschwindigkeitsregler" 1 "GRA" 2 "GRA_Plus" 3 "Base_ACC" 4 "ACC_Follow_to_Stop" 5 "ACC_Stop_and_Go" 7 "Coding_in_Plausibilisierungsphase";
VAL_ 1603 KBI_Unit_Date 0 "Tag/Month/Year" 1 "Month/Tag/Year" 2 "Year/Month/Tag" 3 "Reserved";
VAL_ 1603 KBI_Unit_Pressure 0 "PressureInfo in bar" 1 "PressureInfo in psi" 2 "PressureInfo in kPa" 3 "tbd.";
VAL_ 1603 KBI_Unit_Streckenanz 0 "Kilometres" 1 "Miles";
VAL_ 1603 KBI_MFA_v_Unit_02 0 "kmh" 1 "mph";
VAL_ 1603 KBI_Unit_Temp 0 "Degree Celsius °C" 1 "Degree Fahrenheit °F";
VAL_ 1603 KBI_Unit_ClockTime 0 "24h" 1 "12h AT/PM";
VAL_ 1603 KBI_Unit_Consumption 0 "mpg UK" 1 "mpg USA" 2 "Litres/100km" 3 "km/Litres";
VAL_ 1603 KBI_Unit_Volume 0 "Litres" 1 "Gallons UK" 2 "Gallons USA" 3 "Reserved";
VAL_ 1603 KBI_Unit_Consumption_elektr 0 "kWh_pro_100km" 1 "km_pro_kWh" 2 "kWh_pro_100mls" 3 "mls_pro_kWh" 4 "MPGe";
VAL_ 1603 KBI_Unit_Consumption_Gas 0 "kg_per_100km" 1 "km_per_kg" 2 "m3_per_100km" 3 "km_per_m3" 4 "miles_per_lbs" 5 "miles_per_yard3" 6 "miles_per_kg" 7 "miles_per_m3" 8 "miles_per_gallon_equivalent_US";
VAL_ 1603 KBI_Unit_Mass 0 "kg" 1 "lbs" 2 "Reserved";
VAL_ 1622 ELV_Req_Terminal_S 0 "Off" 1 "On";
VAL_ 1622 ELV_Req_Terminal_15 0 "Off" 1 "On";
VAL_ 1622 ELV_Req_Terminal_50 0 "Off" 1 "On";
VAL_ 1622 ELV_01_SendStatus 0 "ELV_Sends_With_1000ms" 1 "ELV_Sends_With_50ms";
VAL_ 1622 ELV_Locked 0 "Not_Locked" 1 "Locked";
VAL_ 1622 ELV_Unlocked 0 "ELV_Not_Unlocked" 1 "ELV_Unlocked";
VAL_ 1622 ELV_ZAT_Pressed 0 "Not_Pressed" 1 "Pressed";
VAL_ 1622 ELV_LifeState 0 "LifeState_0" 1 "LifeState_4";
VAL_ 1622 ELV_Anlernmodus 0 "NormalOperation" 1 "Anlernmodus";
VAL_ 1622 ELV_TerminalsEnable 0 "No_Enable" 1 "Enable";
VAL_ 1622 ELV_Abort_Req_TerminalsEnable 0 "No_Abort" 1 "Abort";
VAL_ 1622 ELV_LED_Red 0 "Off" 1 "On";
VAL_ 1622 ELV_LED_Yellow 0 "Off" 1 "On";
VAL_ 1622 ELV_Txt_PanicShutdown 0 "Off" 1 "On";
VAL_ 1622 ELV_Txt_Lkg_Bewegen 0 "Off" 1 "On";
VAL_ 1622 ELV_Txt_Workshop 0 "Off" 1 "On";
VAL_ 1622 ELV_Txt_Defective 0 "Off" 1 "On";
VAL_ 1622 ELV_Txt_P_Gear 0 "Off" 1 "On";
VAL_ 1622 ELV_Txt_PN_Gear 0 "Off" 1 "On";
VAL_ 1622 ELV_Txt_Clutch 0 "Off" 1 "On";
VAL_ 1622 ELV_Txt_Brake 0 "Off" 1 "On";
VAL_ 1622 ELV_P_Locked 0 "Not_Locked" 1 "Locked";
VAL_ 1624 LV_SideLight_Display 0 "Not Active" 1 "Active";
VAL_ 1624 LV_LowBeam_Display 0 "Inactive" 1 "Active";
VAL_ 1624 LV_HighBeam_Display 0 "Not Active" 1 "Active";
VAL_ 1624 LV_FogLight_Display 0 "Not Active" 1 "Active";
VAL_ 1624 LV_RearFogLight_Display 0 "Not Active" 1 "Active";
VAL_ 1624 LV_DaytimeRunningLight_Display 0 "Not Active" 1 "Active";
VAL_ 1624 LV_AFL_Active_Display 0 "Not Active" 1 "Active";
VAL_ 1624 LV_AFL_Defective 0 "OK" 1 "Defective";
VAL_ 1624 LV_Indicator_Left_def 0 "OK" 1 "Defective";
VAL_ 1624 LV_SideLight_Left_def 0 "OK" 1 "Defective";
VAL_ 1624 LV_LowBeam_Left_def 0 "OK" 1 "Defective";
VAL_ 1624 LV_HighBeam_Left_def 0 "OK" 1 "Defective";
VAL_ 1624 LV_FogLight_Left_def 0 "OK" 1 "Defective";
VAL_ 1624 LV_Blk_Left_Side_def 0 "OK" 1 "Defective";
VAL_ 1624 LV_DaytimeRunningLight_Left_def 0 "OK" 1 "Defective";
VAL_ 1624 LV_FLA_Active_Display 0 "Off" 1 "On";
VAL_ 1624 LV_FLA_Defective 0 "i.O." 1 "FLA Defective";
VAL_ 1624 LV_FLA_Sensor_Blocked 0 "i.O." 1 "FLA-Sensor Blocked";
VAL_ 1624 LV_Indicator_Right_def 0 "OK" 1 "Defective";
VAL_ 1624 LV_SideLight_Right_def 0 "OK" 1 "Defective";
VAL_ 1624 LV_LowBeam_Right_def 0 "OK" 1 "Defective";
VAL_ 1624 LV_HighBeam_Right_def 0 "OK" 1 "Defective";
VAL_ 1624 LV_FogLight_Right_def 0 "OK" 1 "Defective";
VAL_ 1624 LV_Blk_Right_Side_def 0 "OK" 1 "Defective";
VAL_ 1624 LV_DaytimeRunningLight_Right_def 0 "OK" 1 "Defective";
VAL_ 1624 LV_OutsideLight_def 0 "OK" 1 "Defective";
VAL_ 1624 LV_LowBeam_TFL_Left_def 0 "OK" 1 "Defective";
VAL_ 1624 LV_FogLight_TFL_Left_def 0 "OK" 1 "Defective";
VAL_ 1624 LV_SideLight_TFL_Left_def 0 "OK" 1 "Defective";
VAL_ 1624 LV_Abblend_HighBeam_Left_def 0 "OK" 1 "Defective";
VAL_ 1624 LV_LowBeam_TFL_Right_def 0 "OK" 1 "Defective";
VAL_ 1624 LV_FogLight_TFL_Right_def 0 "OK" 1 "Defective";
VAL_ 1624 LV_SideLight_TFL_Right_def 0 "OK" 1 "Defective";
VAL_ 1624 LV_Abblend_HighBeam_Right_def 0 "OK" 1 "Defective";
VAL_ 1624 LV_TurnLight_Left_def 0 "OK" 1 "Defective";
VAL_ 1624 LV_TurnLight_Right_def 0 "OK" 1 "Defective";
VAL_ 1624 BCM1_LeftHandTraffic 0 "RightHandTraffic" 1 "LeftHandTraffic";
VAL_ 1624 BCM1_Light_Darkness_Active 0 "Inactive" 1 "Active";
VAL_ 1624 LV_LED_Scheinwerfer_Left_def 0 "OK" 1 "Defective";
VAL_ 1624 LV_LED_Scheinwerfer_Right_def 0 "OK" 1 "Defective";
VAL_ 1624 LV_Indicator_VL_Active 0 "Inactive" 1 "Active";
VAL_ 1624 LV_Indicator_VR_Active 0 "Inactive" 1 "Active";
VAL_ 1624 LV_MXB_Status_Display 0 "MXB_Off" 1 "MXB_Controls" 2 "MXB_volles_HighBeam" 3 "MXB_And_Laser_Active";
VAL_ 1629 BR_SystemType 0 "ABS" 1 "ABS_ASR" 2 "ESP" 3 "ESP_With_integrierter_EPB";
VAL_ 1629 ESP_VoltageReq_02 0 "No_Request" 1 "Request_Stage1" 2 "Request_Stage2" 3 "Request_Stage3";
VAL_ 1629 ESP_Charisma_DrivePr 0 "No_Function" 1 "Programm_1" 2 "Programm_2" 3 "Programm_3" 4 "Programm_4" 5 "Programm_5" 6 "Programm_6" 7 "Programm_7" 8 "Programm_8" 9 "Programm_9" 10 "Programm_10" 11 "Programm_11" 12 "Programm_12" 13 "Programm_13" 14 "Programm_14" 15 "Programm_15";
VAL_ 1629 ESP_Charisma_Status 0 "Init" 1 "Available" 2 "Not_Available" 3 "Asynchronous_By_DriverDemand";
VAL_ 1629 ESP_Restart_Disp_01 0 "No_Display" 1 "RollBack";
VAL_ 1629 ESP_Restart_Disp_02 0 "No_Display" 1 "AutoHold_Rutschen";
VAL_ 1629 ESP_Restart_Disp_03 0 "No_Display" 1 "Offroad_HDC";
VAL_ 1629 ESP_Restart_Disp_04 0 "No_Display" 1 "ESC_Off";
VAL_ 1629 ESP_StopInhibit_Disp_01 0 "No_Display" 1 "EmergencyBraking_Active";
VAL_ 1629 ESP_StopInhibit_Disp_02 0 "No_Display" 1 "AutoHold_AVH_Rutschen";
VAL_ 1629 ESP_StopInhibit_Disp_03 0 "No_Display" 1 "RollBack";
VAL_ 1629 ESP_StopInhibit_Disp_04 0 "No_Display" 1 "ESP_PumpRun";
VAL_ 1629 ESP_StopInhibit_Disp_05 0 "No_Display" 1 "ESP_OFF";
VAL_ 1629 ESP_StopInhibit_Disp_06 0 "No_Display" 1 "Offroad_HDC";
VAL_ 1629 ESP_StopInhibit_Disp_07 0 "No_Display" 1 "ESP_Haltefunktion_Not_Available";
VAL_ 1629 ESP_StopInhibit_Disp_Std 0 "No_Display" 1 "Standard_Stoppvetogrund";
VAL_ 1629 ESP_Dachrelingsensor 0 "Sensor_Not_Fitted" 1 "Quertraeger_montiert" 2 "Quertraeger_Not_montiert" 3 "Error";
VAL_ 1629 ESP_StopInhibit_Disp_08 0 "No_Display" 1 "InclinationLimit";
VAL_ 1629 HDC_Charisma_DrivePr 0 "No_Function" 1 "Programm_1" 2 "Programm_2" 3 "Programm_3" 4 "Programm_4" 5 "Programm_5" 6 "Programm_6" 7 "Programm_7" 8 "Programm_8" 9 "Programm_9" 10 "Programm_10" 11 "Programm_11" 12 "Programm_12" 13 "Programm_13" 14 "Programm_14" 15 "Programm_15";
VAL_ 1629 HDC_Charisma_Status 0 "Init" 1 "Available" 2 "Not_Available" 3 "Asynchronous_By_DriverDemand";
VAL_ 1629 BR_QBit_TyreCircumference 0 "Valid_Value" 1 "Substitute_Init_Or_ErrorValue";
VAL_ 1631 TSK_QBit_Gradient 0 "Valid_Value" 1 "Substitute_Init_Or_ErrorValue";
VAL_ 1631 TSK_QBit_VehicleMass 0 "Valid_Value" 1 "Substitute_Init_Or_ErrorValue";
VAL_ 1631 MO_VoltageReq_02 0 "No_Request" 1 "Request_Stage_1" 2 "Request_Stage_2" 3 "Request_Stage_3";
VAL_ 1631 MO_DPF_reg 0 "DPF_Regenerated_Not" 1 "DPF_Regenerated";
VAL_ 1631 MO_HeaterCurrent_EKAT 127 "Error";
VAL_ 1631 MO_HeaterCurrent_SCR 63 "Error";
VAL_ 1631 MO_Display_ColdLamp 0 "Lamp_Off" 1 "Lamp_On";
VAL_ 1631 MO_P_Alternator_Unfiltered_Req 0 "Not_Requested" 1 "Requested";
VAL_ 1631 TSK_GearboxInfo 0 "ManualGearbox" 1 "AL_AQ_Gearbox" 2 "DL_DQ_Gearbox" 3 "CVT_Gearbox";
VAL_ 1631 MO_EnergyContents_BMS 4094 "Init" 4095 "Error";
VAL_ 1631 TSK_VehicleMass_02 255 "Error";
VAL_ 1631 TSK_Gradient_02 0 "Init_Or_Not_Fitted" 255 "Error";
VAL_ 1640 TERM_LRH_PushButton 0 "Not_Pressed" 1 "Pressed";
VAL_ 1640 TERM_LRH_Stage 0 "Stage_Low" 1 "Stage_Average" 2 "Stage_High" 3 "OFF";
VAL_ 1640 HSH_PushButton 0 "Not_Pressed" 1 "short_push" 2 "long_push" 3 "tbd";
VAL_ 1640 FSH_PushButton 0 "Not_Pressed" 1 "Pressed";
VAL_ 1640 TERM_AuxHeater_Enable 0 "No_Enable_AuxHeater" 1 "AuxHeaterEnable";
VAL_ 1640 TERM_FoggingRisk 0 "No_FoggingRisk" 1 "FoggingRisk";
VAL_ 1640 KRH_Target_Left 0 "Off" 1 "Stage_1" 2 "Stage_2" 3 "Stage_3";
VAL_ 1640 KRH_Target_Right 0 "Off" 1 "Stage_1" 2 "Stage_2" 3 "Stage_3";
VAL_ 1640 TERM_Geblspng_Target 0 "0V_EngineVoltage" 252 "0V_sofort_SwitchOff" 253 "0V_senken_With_Ramp" 254 "Reserved" 255 "Error";
VAL_ 1640 TERM_Geblspng_Fond_Target 0 "0V_EngineVoltage" 252 "0V_sofort_SwitchOff" 253 "0V_senken_With_Ramp" 254 "Reserved" 255 "Error";
VAL_ 1640 TERM_I_Blower 255 "Error";
VAL_ 1640 TERM_CompressorCurrent_Target 1022 "Init" 1023 "Error";
VAL_ 1640 TERM_RecirculationFlap_Status 0 "Frischluft" 1 "PartRecirculation_10" 2 "PartRecirculation_20" 3 "PartRecirculation_30" 4 "PartRecirculation_40" 5 "PartRecirculation_50" 6 "PartRecirculation_60" 7 "PartRecirculation_70" 8 "PartRecirculation_80" 9 "PartRecirculation_90" 10 "Umluft" 14 "Init" 15 "Error";
VAL_ 1640 TERM_PTC_FitmentInfo 0 "No_PTC" 1 "600W_geschaltet" 2 "1000W_geschaltet" 3 "1400W_LIN";
VAL_ 1648 MO_ANC_Map_Req 0 "Map_1" 1 "OverGear_Map_2_After_1" 2 "OverGear_Map_1_After_2" 3 "Map_2";
VAL_ 1648 MO_BrakeLight_Recup 0 "Off" 1 "On";
VAL_ 1648 MO_StartStop_PopUp 0 "Statuswechsel_Without_PushButton (Init)" 1 "StSt_per_PushButton_Deactivated" 2 "StSt_per_PushButton_Activated" 3 "Not Used";
VAL_ 1648 MO1_Lock_Info_WFS 0 "Not_Locked" 1 "Locked";
VAL_ 1648 MO1_Enable_Info_WFS 0 "Invalid" 1 "Valid";
VAL_ 1648 MO_EPCL 0 "EPCL_Off_No_Text" 1 "EPCL_Yellow_Malfunction" 2 "EPCL_Yellow_Leistungsbeschraenkung" 3 "EPCL_Red_Veh_Safe_abstellen";
VAL_ 1648 MO_CylDeact_Texte_02 0 "On_ZAS_generell_No_ZAS_Display" 1 "ZAS_In_VMB" 2 "ZAS_In_ASB_1_Cyl_Active" 3 "ZAS_In_ASB_2_Cyl_Active" 4 "ZAS_In_ASB_3_Cyl_Active" 5 "ZAS_In_ASB_4_Cyl_Active" 6 "ZAS_In_ASB_5_Cyl_Active" 7 "ZAS_In_ASB_6_Cyl_Active" 8 "ZAS_In_ASB_8_Cyl_Active" 9 "ZAS_In_ASB_12_Cyl_Active" 13 "OverGearOperation" 14 "No_ZAS_Display_ggf_Stop_Overrun_Operation" 15 "ZAS_Stoerungs_Display";
VAL_ 1648 MO_VehicleType 0 "Verbrenner_Vehicle" 1 "Hybrid" 2 "E_Vehicle" 3 "E_Vehicle_With_Range_Extender" 4 "Brennstoffzellenfahrzeug" 5 "tbd" 6 "tbd" 7 "tbd";
VAL_ 1648 MO_ParkedTime 254 "Init" 255 "Reserved";
VAL_ 1648 MO_ParkedTime_Status 0 "ParkedTime_Not_Calculated" 1 "ParkedTime_Calculated" 2 "ParkedTime_Minimalwert" 3 "ParkedTime_Invalid";
VAL_ 1648 MO1_Enable_ExpiryInfo_WFS 0 "verfaellt_Not" 1 "verfaellt";
VAL_ 1648 MO_Hybrid_StartStop_LED 0 "LED_Off_And_Flash_Off" 1 "LED_On_And_Flash_Off" 2 "LED_On_And_Flash_On_50_percent" 3 "Reserved";
VAL_ 1648 MO_Error_CylDeact 0 "No_Error" 1 "LimpHome_FullEngineOperation" 2 "LimpHome_AtLeast_einem_abgesch_Cylinder";
VAL_ 1648 MO_Count_Abgesch_Cyl 0 "FullEngineOperation" 1 "1_Cylinder_SwitchedOff" 2 "2_Cylinder_SwitchedOff" 3 "3_Cylinder_SwitchedOff" 4 "4_Cylinder_SwitchedOff" 5 "5_Cylinder_SwitchedOff" 6 "6_Cylinder_SwitchedOff" 7 "8_Cylinder_SwitchedOff";
VAL_ 1648 MO_CylDeact_Texte 0 "No_Texte" 1 "CylinderDeactivation_Deactivate" 2 "CylinderDeactivation_Activate" 3 "CylinderDeactivation_unruhig";
VAL_ 1648 MO_Ethanol_BS_Texte 0 "No_Text" 1 "E85_Warm_Up" 2 "FlexFuel_Warning_Stage_3" 3 "WarmDriveRecommendation_MQB__FlexFuel_Warning_Stage_1" 4 "FlexFuel_Warning_Stage_2" 5 "FlexFuel_Warning_Stage_4" 6 "E25_Warm_Up";
VAL_ 1648 MO_Rpm_Warning 0 "No_WarningNote_Display" 1 "WarningNote_Display";
VAL_ 1648 MO_Upper_RpmLimit 0 "Init";
VAL_ 1710 SP_FT_Top 0 "Not_Pressed" 1 "Pressed";
VAL_ 1710 SP_FT_Bottom 0 "Not_Pressed" 1 "Pressed";
VAL_ 1710 SP_FT_Left 0 "Not_Pressed" 1 "Pressed";
VAL_ 1710 SP_FT_Right 0 "Not_Pressed" 1 "Pressed";
VAL_ 1710 SP_BT_Top 0 "Not_Pressed" 1 "Pressed";
VAL_ 1710 SP_BT_Bottom 0 "Not_Pressed" 1 "Pressed";
VAL_ 1710 SP_BT_Left 0 "Not_Pressed" 1 "Pressed";
VAL_ 1710 SP_BT_Right 0 "Not_Pressed" 1 "Pressed";
VAL_ 1710 SP_FoldDown 0 "Mirror_FoldDown_Not_Active" 1 "Mirror_FoldDown_Active";
VAL_ 1710 SP_FoldIn 0 "Spiegle_FoldIn_Not_Active" 1 "Mirror_FoldIn_Active";
VAL_ 1710 SP_normieren 0 "Mirror_Not_Normalised" 1 "Mirror_Normalised";
VAL_ 1710 SP_Hzg_PushButton 0 "Not_Pressed" 1 "Pressed";
VAL_ 1710 SP_S_Top 1 "MirrorSwitch in Position Top";
VAL_ 1710 SP_S_Bottom 1 "MirrorSwitch in Position Bottom";
VAL_ 1710 SP_S_Left 1 "MirrorSwitch in Position Left";
VAL_ 1710 SP_S_Right 1 "MirrorSwitch in Position Right";
VAL_ 1710 SP_Selection_Left 1 "MirrorSwitch in Position Selection Left";
VAL_ 1710 SP_Selection_Right 1 "MirrorSwitch in Position Selection Right";
VAL_ 1710 SP_ARA_Status 0 "DoorECU Not In ARA-Mode" 1 "DoorECU In ARA-Mode";
VAL_ 1710 SP_S_Fold 1 "MirrorSwitch in Position Fold";
VAL_ 1710 SP_Verstellschalter_Error 0 "No_Error" 1 "Error";
VAL_ 1711 RV_Video_on 0 "CameraImage Is Not Displayed" 1 "CameraImage Is Displayed";
VAL_ 1711 RV_Dark_Screen 0 "CameraImage Not verdunkeln" 1 "CameraImage verdunkeln";
VAL_ 1711 RV_HMI_Mode 0 "Parkluecke  (Mode 1)" 1 "Parallel To Roadߥ (Mode 2)" 2 "Reserved" 3 "Calibration (Only Diagnostics)";
VAL_ 1711 RV_GL_side 0 "Guidelines_SwitchedOff" 1 "Guidelines_Display_Right_Side" 2 "Guiedelines_Display_Left_Side" 3 "Guiedelines_Display_Both_Side";
VAL_ 1711 RV_System_Active 0 "System Not Operational" 1 "System Operational";
VAL_ 1711 RV_Reinigung_Req 0 "Not_Clean" 1 "Clean";
VAL_ 1711 RV_Settings_enabled 0 "Menu 'Einstellungen' Not Activated" 1 "Menu 'Einstellungen' Activated";
VAL_ 1711 RV_Menu_Item 0 "HMI Mode As Selected Marked" 1 "Brightness As Selected Marked" 2 "Kontrast As Selected Marked" 3 "Farbsaettigung As Selected Marked";
VAL_ 1711 SV_Video_on 0 "SideView_Off_/_Not_Fitted" 1 "SideView_On";
VAL_ 1711 RV_Calib_Error 0 "Calibration_i.O." 1 "RearView_Not_Calibrated";
VAL_ 1711 RV_GL_Trailer_connect 0 "Guidelines_Become_Displayed" 1 "Guidelines_DueTo_angekoppeltem_Trailer䮧er_Deactivated";
VAL_ 1711 RV_GL_Trunk_open 0 "Guidelines_Become_Displayed" 1 "Guidelines_DueTo_geffneter_Heckklappe_Deactivated";
VAL_ 1711 RV_GL_LWS_Error 0 "Guidelines_Become_Displayed" 1 "Guidelines_DueTo_Not_kalibriertem_Lenkwinkelsensor_Deactivated";
VAL_ 1711 ZFAS_Umfeldbeleuchtung_Req 0 "Not_Requested" 1 "Requested";
VAL_ 1714 DGN_UnlearnCounter 255 "Invalid Z䨬erstand Or No Valid DriveCycle";
VAL_ 1714 UH_Month 0 "Init" 14 "Relatives_Date" 15 "Error";
VAL_ 1714 UH_Tag 0 "Init";
VAL_ 1714 Cluster_02_Old 0 "Current" 1 "Outdated";
VAL_ 1714 ClockTime_01_Old 0 "Current" 1 "Outdated";
VAL_ 441800114 Temperature_Status_Charge 0 "init" 1 "temp under Optimal" 2 "temp Optimal" 3 "temp over Optimal" 7 "fault";
VAL_ 316495015 VZE_DisplayMode 0 "EU_RDW" 1 "USA" 2 "Canada" 3 "China";
VAL_ 316495015 VZE_DisplaySuppress_Sign_3 0 "DisplayRelevant" 1 "Not_DisplayRelevant";
VAL_ 316495015 VZE_DisplaySuppress_Sign_2 0 "DisplayRelevant" 1 "Not_DisplayRelevant";
VAL_ 316495015 VZE_TrafficSign_1 0 "No_TrafficSign" 520 "Unlimited";
VAL_ 316495015 VZE_TrafficSign_2 0 "No_TrafficSign" 520 "Unlimited";
VAL_ 316495015 VZE_TrafficSign_3 0 "No_TrafficSign" 520 "Unlimited";
VAL_ 316495015 VZE_Warning_TrafficSign_1 0 "No_Warning_InitialValue_ErrorValue" 1 "Warning";
VAL_ 316495015 VZE_Warning_TrafficSign_2 0 "No_Warning_InitialValue_ErrorValue" 1 "Warning";
VAL_ 316495015 VZE_Warning_TrafficSign_3 0 "No_Warning_InitialValue_ErrorValue" 1 "Warning";
VAL_ 316495015 VZE_SupplementarySign_1 0 "No_SupplementarySign_InitialValue_ErrorValue";
VAL_ 316495015 VZE_SupplementarySign_2 0 "No_SupplementarySign_InitialValue_ErrorValue";
VAL_ 316495015 VZE_SupplementarySign_3 0 "No_SupplementarySign_InitialValue_ErrorValue";
VAL_ 316495015 VZE_DisplaySuppress_Sign_1 0 "DisplayRelevant" 1 "Not_DisplayRelevant";
VAL_ 316495015 VZE_Sign_01_CameraWied 0 "Inactive" 1 "Active";
VAL_ 316495015 VZE_Sign_02_CameraWied 0 "Inactive" 1 "Active";
VAL_ 316495015 VZE_Sign_03_CameraWied 0 "Inactive" 1 "Active";
VAL_ 316495015 VZE_Sign_01_Camera 0 "Not_Detected" 1 "Detected";
VAL_ 316495015 VZE_Sign_01_Map 0 "Inactive" 1 "Active";
VAL_ 316495015 VZE_Sign_01_Law 0 "Not_Detected" 1 "Detected";
VAL_ 316495015 VZE_Sign_02_Camera 0 "Not_Detected" 1 "Detected";
VAL_ 316495015 VZE_Sign_02_Map 0 "Inactive" 1 "Active";
VAL_ 316495015 VZE_Sign_02_Law 0 "Not_Detected" 1 "Detected";
VAL_ 316495015 VZE_Sign_03_Camera 0 "Not_Detected" 1 "Detected";
VAL_ 316495015 VZE_Sign_03_Map 0 "Inactive" 1 "Active";
VAL_ 316495015 VZE_Sign_03_Law 0 "Not_Detected" 1 "Detected";
VAL_ 316495015 VZE_Chime 0 "Chime_Deactivated" 1 "Chime_Active";
VAL_ 380196013 AWV_Status 0 "Init" 1 "Available" 2 "Unavailable";

BO_ 190 MEB_HVEM_01: 48 XXX
 SG_ CRC : 0|8@1+ (1,0) [0|255] "" XXX
 SG_ CNT : 8|4@1+ (1,0) [0|15] "" XXX
 SG_ Engine_RPM_Max : 12|14@1+ (2,-9658) [0|15] "RPM" XXX
 SG_ Engine_RPM_Min : 26|14@1+ (2,-10300) [0|63] "RPM" XXX
 SG_ In_Motion_04 : 48|3@1+ (1,0) [0|7] "" XXX
 SG_ In_Motion_03 : 52|1@0+ (1,0) [0|1] "" XXX
 SG_ In_Motion_02 : 54|1@0+ (1,0) [0|1] "" XXX
 SG_ Engine_Power : 56|12@1+ (0.5,-1023) [0|255] "kW" XXX
 SG_ In_Motion : 68|1@1+ (1,0) [0|3] "" XXX
 SG_ Standstill : 71|1@0+ (1,0) [0|1] "" XXX
 SG_ Voltage : 86|12@1+ (0.24,0) [0|3] "V" XXX
 SG_ Battery_Voltage : 113|13@1+ (0.065,0) [0|127] "V" XXX
 SG_ Engine_Status : 296|2@1+ (1,0) [0|3] "" XXX
 SG_ Inactive : 300|1@0+ (1,0) [0|1] "" XXX
 SG_ Inactive_02 : 303|1@0+ (1,0) [0|1] "" XXX

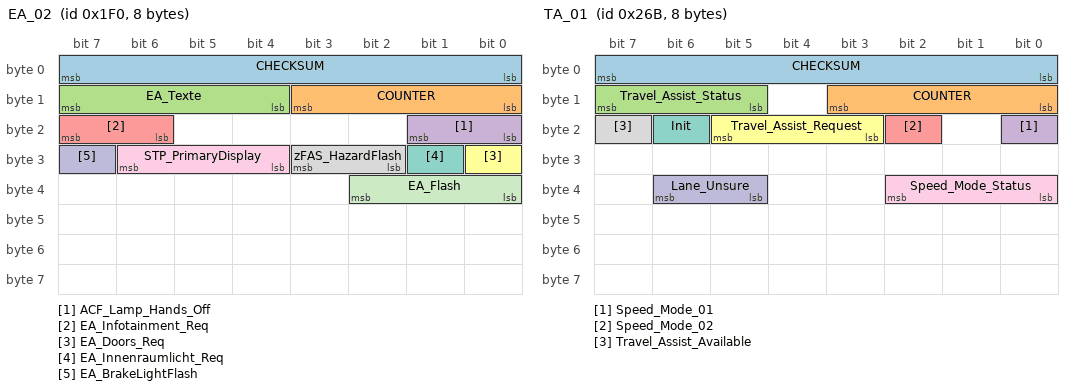
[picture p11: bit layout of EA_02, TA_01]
BO_ 496 EA_02: 8 Gateway
 SG_ CHECKSUM : 0|8@1+ (1,0) [0|255] "" Vector__XXX
 SG_ COUNTER : 8|4@1+ (1,0) [0|15] "" Vector__XXX
 SG_ EA_Texte : 12|4@1+ (1,0) [0|15] "" ZR_High
 SG_ ACF_Lamp_Hands_Off : 16|2@1+ (1,0) [0|3] "" Vector__XXX
 SG_ EA_Infotainment_Req : 22|2@1+ (1,0) [0|3] "" ZR_High,ZR_LIMU,ZR_MIB_TOP_ab_Gen3,ZR_Standard
 SG_ EA_Doors_Req : 24|1@1+ (1,0) [0|1] "" ZR_High
 SG_ EA_Innenraumlicht_Req : 25|1@1+ (1,0) [0|1] "" ZR_High
 SG_ zFAS_HazardFlash : 26|2@1+ (1,0) [0|3] "" ZR_High
 SG_ STP_PrimaryDisplay : 28|3@1+ (1,0) [0|7] "" Vector__XXX
 SG_ EA_BrakeLightFlash : 31|1@1+ (1,0) [0|1] "" Vector__XXX
 SG_ EA_Flash : 32|3@1+ (1,0) [0|7] "" Vector__XXX

BO_ 768 ACC_19: 48 XXX
 SG_ ACC_SpeedLimit : 64|5@1+ (1,0) [0|31] "" OTA_FC
 SG_ ACC_SetSpeed_Colour : 69|1@1+ (1,0) [0|1] "" Vector__XXX
 SG_ ACC_Warning_TrafficSign_1 : 70|1@1+ (1,0) [0|1] "" Vector__XXX
 SG_ ACA_LateralGuidance : 71|2@1+ (1,0) [0|3] "" Vector__XXX
 SG_ ACC_Control_AIO : 75|1@1+ (1,0) [0|1] "" ZR_High,ZR_LIMU,ZR_MIB_TOP_ab_Gen3
 SG_ ACC_SetSpeed_02 : 76|10@1+ (0.32,0) [0|327.04] "Unit_KiloMeterPerHour" Vector__XXX
 SG_ ACC_DistanceIndex_02 : 86|10@1+ (1,0) [1|1021] "" Vector__XXX
 SG_ ACC_Display_Prio : 96|2@1+ (1,0) [0|3] "" Vector__XXX
 SG_ ACC_rel_Object_AuxDisplay : 98|2@1+ (1,0) [0|3] "" Vector__XXX
 SG_ ACC_Set_TimeGap : 101|3@1+ (1,0) [0|7] "" Vector__XXX
 SG_ ACC_Optical_DriverNotice : 104|1@1+ (1,0) [0|1] "" Vector__XXX
 SG_ ACC_WarningNote : 105|1@1+ (1,0) [0|1] "" Vector__XXX
 SG_ ACC_EGO_Vehicle : 106|3@1+ (1,0) [0|7] "" Vector__XXX
 SG_ ACC_Relevant_Object_02 : 109|2@1+ (1,0) [0|3] "" OTA_FC,ZR_High,ZR_LIMU,ZR_MIB_TOP_ab_Gen3
 SG_ ACC_SetSpeed_Reached : 112|1@1+ (1,0) [0|1] "" OTA_FC
 SG_ ACC_Display_TimeGap : 113|1@1+ (1,0) [0|1] "" Vector__XXX
 SG_ ACC_Texte_PrimaryDisplay_02 : 114|6@1+ (1,0) [0|63] "" Vector__XXX
 SG_ ACC_Texte_AuxDisplay_02 : 120|6@1+ (1,0) [0|63] "" Vector__XXX
 SG_ Status_PrimaryDisplay : 126|2@1+ (1,0) [0|3] "" Vector__XXX
 SG_ ACC_Event_SetSpeed : 140|10@1+ (0.32,0) [0|15] "" XXX
 SG_ Heartbeat : 150|9@1+ (1,0) [0|3] "" XXX
 SG_ SET_ME_0XFFFF : 160|16@1+ (1,0) [0|65535] "" XXX
 SG_ ACC_Enabled : 186|1@0+ (1,0) [0|1] "" XXX
 SG_ TimeGap_Colour : 189|1@0+ (1,0) [0|1] "" XXX
 SG_ SET_ME_0X1 : 199|1@0+ (1,0) [0|1] "" XXX
 SG_ ACC_Status_ACC : 208|3@1+ (1,0) [0|7] "" XXX
 SG_ ACC_Akustischer_DriverNotice : 211|2@1+ (1,0) [0|1] "" XXX
 SG_ SET_ME_0X7FFF : 240|16@1+ (1,0) [0|65535] "" XXX
 SG_ Lead_Type_Detected : 265|1@0+ (1,0) [0|1] "" XXX
 SG_ ACC_Standby_Override : 266|1@0+ (1,0) [0|1] "" XXX
 SG_ Street_Color : 267|1@0+ (1,0) [0|1] "" XXX
 SG_ ACC_Limiter_Mode : 268|1@0+ (1,0) [0|1] "" XXX
 SG_ Lead_Brightness : 269|4@1+ (1,0) [0|7] "" XXX
 SG_ SET_ME_0X6A : 273|8@1+ (1,0) [0|7] "" XXX
 SG_ Lead_Position : 281|2@1+ (1,0) [0|1] "" XXX
 SG_ Lead_Type : 287|3@1+ (1,0) [0|3] "" XXX
 SG_ Lead_Distance : 290|10@1+ (0.2,0) [0|7] "Unit_Meter" XXX
 SG_ Lead_Distance_Right : 300|10@1+ (0.2,0) [0|15] "Unit_Meter" XXX
 SG_ Lead_Distance_Left : 310|10@1+ (0.2,0) [0|3] "Unit_Meter" XXX
 SG_ ACC_Events : 332|4@0+ (1,0) [0|3] "Unit_Meter" XXX
 SG_ TimeGap_1 : 334|9@1+ (0.171,0) [0|100] "Unit_Meter" XXX
 SG_ TimeGap_2 : 344|9@1+ (0.171,0) [0|100] "Unit_Meter" XXX
 SG_ TimeGap_3 : 354|9@1+ (0.171,0) [0|100] "Unit_Meter" XXX
 SG_ TimeGap_4 : 364|9@1+ (0.171,0) [0|100] "Unit_Meter" XXX
 SG_ TimeGap_5 : 374|9@1+ (0.171,0) [0|100] "Unit_Meter" XXX

VAL_ 768 ACC_Event_SetSpeed 1023 "None";
VAL_ 768 ACC_Events 3 "Starting_Available" 0 "None" 5 "Speed_Limit_Detected" 9 "Crossing" 4 "Speed_Limit_Ahead" 10 "Roundabout" 6 "Curve";

BO_ 252 ESC_51: 64 XXX
 SG_ CHECKSUM : 0|8@1+ (1,0) [0|255] "" XXX
 SG_ COUNTER : 8|4@1+ (1,0) [0|15] "" XXX
 SG_ AEB_Breaking_01 : 24|8@1+ (1,0) [0|255] "" XXX
 SG_ AEB_Breaking_02 : 32|8@1+ (1,0) [0|255] "" XXX
 SG_ Accelerator_Higher_Speed : 40|1@0+ (1,0) [0|1] "" XXX
 SG_ Brake_Pressure : 42|9@1+ (0.195,0) [0|100] "Unit_Percent" XXX
 SG_ HL_WheelSpeed : 64|16@1+ (0.0075,0) [0|491.5125] "Unit_KilometerPerHour" XXX
 SG_ HR_WheelSpeed : 80|16@1+ (0.0075,0) [0|491.5125] "Unit_KilometerPerHour" XXX
 SG_ VL_WheelSpeed : 96|16@1+ (0.0075,0) [0|491.5125] "Unit_KilometerPerHour" XXX
 SG_ VR_WheelSpeed : 112|16@1+ (0.0075,0) [0|491.5125] "Unit_KilometerPerHour" XXX
 SG_ HL_Brake_Pressure : 152|8@1+ (1,0) [0|100] "" XXX
 SG_ HR_Brake_Pressure : 160|8@1+ (1,0) [0|100] "" XXX
 SG_ VL_Brake_Pressure : 168|8@1+ (1,0) [0|100] "" XXX
 SG_ VR_Brake_Pressure : 176|8@1+ (1,0) [0|100] "" XXX
 SG_ Steering_Wheel_CW : 184|8@1+ (1.67,0) [0|255] "" XXX
 SG_ Steering_Wheel_CCW : 192|8@1+ (1.67,0) [0|255] "" XXX
 SG_ ESC_v_Signal : 328|13@1+ (0.052,-107.016) [0|63] "" XXX

BO_ 267 Engine_51: 48 XXX
 SG_ CHECKSUM : 0|8@1+ (1,0) [0|255] "" XXX
 SG_ COUNTER : 8|4@1+ (1,0) [0|15] "" XXX
 SG_ Accel_Pedal_Pressure : 12|9@1+ (0.4,0) [0|255] "" XXX
 SG_ Accel_Low_Pressed_Support : 21|1@1+ (1,0) [0|7] "" XXX
 SG_ TSK_Status : 88|3@1+ (1,0) [0|7] "" XXX
 SG_ TSK_Limiter_Selected : 95|1@1+ (1,0) [0|3] "" XXX

BO_ 619 TA_01: 8 XXX
 SG_ CHECKSUM : 0|8@1+ (1,0) [0|255] "" XXX
 SG_ COUNTER : 8|4@1+ (1,0) [0|15] "" XXX
 SG_ Travel_Assist_Status : 13|3@1+ (1,0) [0|3] "" XXX
 SG_ Speed_Mode_01 : 16|1@0+ (1,0) [0|1] "" XXX
 SG_ Speed_Mode_02 : 18|1@0+ (1,0) [0|1] "" XXX
 SG_ Travel_Assist_Request : 19|3@1+ (1,0) [0|7] "" XXX
 SG_ Init : 22|1@0+ (1,0) [0|1] "" XXX
 SG_ Travel_Assist_Available : 23|1@1+ (1,0) [0|1] "" XXX
 SG_ Speed_Mode_Status : 32|3@1+ (1,0) [0|7] "" XXX
 SG_ Lane_Unsure : 37|2@1+ (1,0) [0|3] "" XXX

CM_ SG_ 987 BCM_01_Old "[DE: BCM_01_alt]";
CM_ SG_ 987 SMLS_01_Old "[DE: SMLS_01_alt]";
CM_ SG_ 987 ZV_02_Old "[DE: ZV_02_alt]";
CM_ SG_ 987 Wiper_01_Old "[DE: Wischer_01_alt]";
CM_ SG_ 987 Trailer_01_Old "[DE: Anhaenger_01_alt]";
CM_ SG_ 987 Climate_Sensor_02_Old "[DE: Klima_Sensor_02_alt]";
CM_ SG_ 987 VSG_01_Old "[DE: VSG_01_alt]";
CM_ SG_ 987 Climate_01_Old "[DE: Klima_01_alt]";
CM_ SG_ 987 WFS_01_Old "[DE: WFS_01_alt]";
CM_ SG_ 987 Light_Req_01_Old "[DE: Licht_Anf_01_alt]";
CM_ SG_ 987 ZV_HFS_Open "[DE: ZV_HFS_offen]";
CM_ SG_ 987 ZV_HBFS_Open "[DE: ZV_HBFS_offen]";
CM_ SG_ 987 VS_VD_Open_ver "[DE: VS_VD_offen_ver]";
CM_ SG_ 987 VS_VD_Closed_ver "[DE: VS_VD_zu_ver]";
CM_ SG_ 987 ZV_BT_Open "[DE: ZV_BT_offen]";
CM_ SG_ 987 BCM1_ReversingLight_Switch "[DE: BCM1_Rueckfahrlicht_Schalter]";
CM_ SG_ 987 ZV_FT_Open "[DE: ZV_FT_offen]";
CM_ SG_ 987 Wiper_Front_Active "[DE: Wischer_vorne_aktiv]";
CM_ SG_ 987 AAG_Trailer_Detected "[DE: AAG_Anhaenger_erkannt]";
CM_ SG_ 987 BCM1_MH_Switch "[DE: BCM1_MH_Schalter]";
CM_ SG_ 987 ZV_HD_Open "[DE: ZV_HD_offen]";
CM_ SG_ 987 Wash_Front_Active "[DE: Waschen_vorne_aktiv]";
CM_ SG_ 987 TERM_ThermalManagement "[DE: KL_Thermomanagement]";
CM_ SG_ 987 WFS_Key_DriveAuthorisation "[DE: WFS_Schluessel_Fahrberecht]";
CM_ SG_ 987 BCM1_RHeadlights_Veh_Req "[DE: BCM1_RFahrlicht_Fzg_Anf]";
CM_ SG_ 987 BCM1_RHeadlights_Ahg_Req "[DE: BCM1_RFahrlicht_Ahg_Anf]";
CM_ SG_ 987 BH_HighBeam "[DE: BH_Fernlicht]";
CM_ SG_ 987 BH_Indicator_Left "[DE: BH_Blinker_li]";
CM_ SG_ 987 BH_Indicator_Right "[DE: BH_Blinker_re]";
CM_ SG_ 987 BCM1_Outside_Temp_Unfilt "[DE: BCM1_Aussen_Temp_ungef]";
CM_ SG_ 988 GE_DriveRange "[DE: GE_Fahrstufe]";
CM_ SG_ 997 DoorECU_FT_02_CRC "[DE: TSG_FT_02_CRC]";
CM_ SG_ 997 DoorECU_FT_02_BZ "[DE: TSG_FT_02_BZ]";
CM_ SG_ 997 FT_Door_Status "[DE: FT_Tuer_Status]";
CM_ SG_ 997 FT_Door_Status_QBit "[DE: FT_Tuer_Status_QBit]";
CM_ SG_ 997 FT_Lock_PushButton_02 "[DE: FT_Lock_Taster_02]";
CM_ SG_ 997 FT_KeySwitch_Closed_02 "[DE: FT_Schluesselschalter_zu_02]";
CM_ SG_ 997 FT_BFS_Door_Status "[DE: FT_BFS_Tuer_Status]";
CM_ SG_ 997 FT_HBFS_Door_Status "[DE: FT_HBFS_Tuer_Status]";
CM_ SG_ 997 FT_HFS_Door_Status "[DE: FT_HFS_Tuer_Status]";
CM_ SG_ 997 FT_DoorOpen_Warning "[DE: FT_Tueroeffnen_Warnung]";
CM_ SG_ 997 FT_SP_Heating_On "[DE: FT_SP_Heizung_ein]";
CM_ SG_ 997 FT_ChildSeat_PushButton_Left_02 "[DE: FT_Kisi_Taster_li_02]";
CM_ SG_ 997 FT_ChildSeat_PushButton_Right_02 "[DE: FT_Kisi_Taster_re_02]";
CM_ SG_ 997 FT_TD_Key_Status "[DE: FT_TD_Taste_Status]";
CM_ SG_ 997 FT_TCR_Mode_Active "[DE: FT_TCR_Mode_aktiv]";
CM_ SG_ 997 FS_Push_DoorHandle "[DE: FS_Push_Tuergriff]";
CM_ SG_ 1122 PSD_Predecessor_Segment_ID "[DE: PSD_Vorgaenger_Segment_ID]";
CM_ SG_ 1122 PSD_SegmentLength "[DE: PSD_Segmentlaenge]";
CM_ SG_ 1122 PSD_EndCurvature "[DE: PSD_Endkruemmung]";
CM_ SG_ 1122 PSD_EndCurvature_Sign "[DE: PSD_Endkruemmung_Vorz]";
CM_ SG_ 1122 PSD_ADAS_Quality "[DE: PSD_ADAS_Qualitaet]";
CM_ SG_ 1122 PSD_MostLikely_Path "[DE: PSD_wahrscheinlichster_Pfad]";
CM_ SG_ 1122 PSD_Straightest_Path "[DE: PSD_Geradester_Pfad]";
CM_ SG_ 1122 PSD_Lanes_Count "[DE: PSD_Fahrspuren_Anzahl]";
CM_ SG_ 1122 PSD_Segment_Complete "[DE: PSD_Segment_Komplett]";
CM_ SG_ 1122 PSD_Ramp "[DE: PSD_Rampe]";
CM_ SG_ 1122 PSD_StartCurvature "[DE: PSD_Anfangskruemmung]";
CM_ SG_ 1122 PSD_StartCurvature_Sign "[DE: PSD_Anfangskruemmung_Vorz]";
CM_ SG_ 1123 PSD_Pos_SegmentLength "[DE: PSD_Pos_Segmentlaenge]";
CM_ SG_ 1123 PSD_Pos_Location_Eindeutig "[DE: PSD_Pos_Standort_Eindeutig]";
CM_ SG_ 1123 PSD_Pos_Error_Laengsrichtung "[DE: PSD_Pos_Fehler_Laengsrichtung]";
CM_ SG_ 1123 PSD_Pos_Lane "[DE: PSD_Pos_Fahrspur]";
CM_ SG_ 1123 PSD_Attribut_1_Value "[DE: PSD_Attribut_1_Wert]";
CM_ SG_ 1123 PSD_Attribut_2_Value "[DE: PSD_Attribut_2_Wert]";
CM_ SG_ 1123 PSD_Attribute_Complete_05 "[DE: PSD_Attribute_Komplett_05]";
CM_ SG_ 1124 PSD_Sys_Speed_Unit "[DE: PSD_Sys_Geschwindigkeit_Einheit]";
CM_ SG_ 1124 PSD_Sys_Age_Map "[DE: PSD_Sys_Alter_Karte]";
CM_ SG_ 1124 PSD_Sys_RouteGuidance "[DE: PSD_Sys_Zielfuehrung]";
CM_ SG_ 1124 PSD_Sys_Quali_LocationInfo "[DE: PSD_Sys_Quali_Ortsinfo]";
CM_ SG_ 1124 PSD_Sys_Quali_Available "[DE: PSD_Sys_Quali_verfuegbar]";
CM_ SG_ 1124 PSD_Sys_RouteGuidance_Changed "[DE: PSD_Sys_Zielfuehrung_geaendert]";
CM_ SG_ 1124 PSD_Sys_Geometrieguete_Extended "[DE: PSD_Sys_Geometrieguete_erweitert]";
CM_ SG_ 1124 PSD_Sys_Quali_Other_Attribute "[DE: PSD_Sys_Quali_sonstige_Attribute]";
CM_ SG_ 1124 PSD_Sys_Quali_Gradients "[DE: PSD_Sys_Quali_Steigungen]";
CM_ SG_ 1124 PSD_Sys_Quali_BeforeJourneyControl "[DE: PSD_Sys_Quali_Vorfahrtsregelung]";
CM_ SG_ 1124 PSD_Attribut_3_Value "[DE: PSD_Attribut_3_Wert]";
CM_ SG_ 1124 PSD_Attribut_4_Value "[DE: PSD_Attribut_4_Wert]";
CM_ SG_ 1124 PSD_Attribut_5_Value "[DE: PSD_Attribut_5_Wert]";
CM_ SG_ 1124 PSD_Attribute_Complete_06 "[DE: PSD_Attribute_Komplett_06]";
CM_ SG_ 1124 PSD_Total_Segment_ID "[DE: PSD_Ges_Segment_ID]";
CM_ SG_ 1124 PSD_Total_Offset "[DE: PSD_Ges_Offset]";
CM_ SG_ 1124 PSD_Total_Speed "[DE: PSD_Ges_Geschwindigkeit]";
CM_ SG_ 1124 PSD_Total_Type "[DE: PSD_Ges_Typ]";
CM_ SG_ 1124 PSD_Total_Lane_Speed_Limit "[DE: PSD_Ges_Spur_Geschw_Begrenzung]";
CM_ SG_ 1124 PSD_Total_Speed_TrailerCombo "[DE: PSD_Ges_Geschwindigkeit_Gespann]";
CM_ SG_ 1124 PSD_Total_Speed_Witter "[DE: PSD_Ges_Geschwindigkeit_Witter]";
CM_ SG_ 1124 PSD_Total_Speed_Tag_Req "[DE: PSD_Ges_Geschwindigkeit_Tag_Anf]";
CM_ SG_ 1124 PSD_Total_Speed_Tag_End "[DE: PSD_Ges_Geschwindigkeit_Tag_Ende]";
CM_ SG_ 1124 PSD_Total_Speed_Std_Req "[DE: PSD_Ges_Geschwindigkeit_Std_Anf]";
CM_ SG_ 1124 PSD_Total_Speed_Std_End "[DE: PSD_Ges_Geschwindigkeit_Std_Ende]";
CM_ SG_ 1124 PSD_Total_NoOvertaking "[DE: PSD_Ges_Ueberholverbot]";
CM_ SG_ 1124 PSD_Total_VariableTrafficSign "[DE: PSD_Ges_Wechselverkehrszeichen]";
CM_ SG_ 1124 PSD_VariableTrafficSign_Type "[DE: PSD_Wechselverkehrszeichen_Typ]";
CM_ SG_ 1124 PSD_Total_Gesetzlich_Kategorie "[DE: PSD_Ges_Gesetzlich_Kategorie]";
CM_ SG_ 1124 PSD_Total_Gesetzlich_Additional "[DE: PSD_Ges_Gesetzlich_Zusatz]";
CM_ SG_ 1124 PSD_Total_TrafficSign_Source "[DE: PSD_Ges_Verkehrszeichen_Quelle]";
CM_ SG_ 1124 PSD_Total_Attribute_Complete "[DE: PSD_Ges_Attribute_Komplett]";
CM_ SG_ 1124 PSD_Tree_Length_VZ "[DE: PSD_Baum_Laenge_VZ]";
CM_ SG_ 1124 PSD_Tree_Length "[DE: PSD_Baum_Laenge]";
CM_ SG_ 1124 PSD_Tree_Width_VZ "[DE: PSD_Baum_Breite_VZ]";
CM_ SG_ 1124 PSD_Tree_Width "[DE: PSD_Baum_Breite]";
CM_ SG_ 1124 PSD_Tree_OffDirection "[DE: PSD_Baum_Ausrichtung]";
CM_ SG_ 1124 PSD_Gradient_1_Segment_ID "[DE: PSD_Steigung_1_Segment_ID]";
CM_ SG_ 1124 PSD_Gradient_1_A_Gradient "[DE: PSD_Steigung_1_A_Steigung]";
CM_ SG_ 1124 PSD_Gradient_1_A_Sign "[DE: PSD_Steigung_1_A_Vorz]";
CM_ SG_ 1124 PSD_Gradient_1_A_Offset "[DE: PSD_Steigung_1_A_Offset]";
CM_ SG_ 1124 PSD_Gradient_1_B_Gradient "[DE: PSD_Steigung_1_B_Steigung]";
CM_ SG_ 1124 PSD_Gradient_1_B_Sign "[DE: PSD_Steigung_1_B_Vorz]";
CM_ SG_ 1124 PSD_Gradient_1_B_Offset "[DE: PSD_Steigung_1_B_Offset]";
CM_ SG_ 1124 PSD_Gradient_1_Attribute_kompl "[DE: PSD_Steigung_1_Attribute_kompl]";
CM_ SG_ 1124 PSD_Gradient_2_Segment_ID "[DE: PSD_Steigung_2_Segment_ID]";
CM_ SG_ 1124 PSD_Gradient_2_Gradient "[DE: PSD_Steigung_2_Steigung]";
CM_ SG_ 1124 PSD_Gradient_2_Sign "[DE: PSD_Steigung_2_Vorz]";
CM_ SG_ 1124 PSD_Gradient_2_Offset "[DE: PSD_Steigung_2_Offset]";
CM_ SG_ 1124 PSD_Gradient_2_Attribute_kompl "[DE: PSD_Steigung_2_Attribute_kompl]";
CM_ SG_ 1153 ZR_LoGeWa_Event_ClusterWarning "[DE: ZR_LoGeWa_Event_Kombiwarnung]";
CM_ SG_ 1153 MIB_ToneAlternator_PH_Available "[DE: MIB_Tongenerator_PH_verfuegbar]";
CM_ SG_ 1153 ZR_RSE_Activate "[DE: ZR_RSE_aktivieren]";
CM_ SG_ 1153 MMI_SDS_Active "[DE: MMI_SDS_aktiv]";
CM_ SG_ 1153 MMI_Phone_Active "[DE: MMI_Telefon_aktiv]";
CM_ SG_ 1153 MMI_Belt_Mic_ref "[DE: MMI_Gurt_Mic_ref]";
CM_ SG_ 1153 ZR_Status_Staging "[DE: ZR_Sta_Inszenierung]";
CM_ SG_ 1153 ZR_MXB_Manoever_Announcement "[DE: ZR_MXB_Manoever_Ansage]";
CM_ SG_ 1153 ZR_LAPP_SpecialMode_Status "[DE: ZR_LAPP_Sondermodus_Status]";
CM_ SG_ 1153 MMI_StartStop_Info "[DE: MMI_StartStopp_Info]";
CM_ SG_ 1153 ZR_Parking_SpecialMode "[DE: ZR_Parken_Sondermodus]";
CM_ SG_ 1155 Mo_Powermeter_Limit "[DE: Mo_Powermeter_Grenze]";
CM_ SG_ 1155 MO_Text_Activation_Drive "[DE: MO_Text_Aktivierung_Antrieb]";
CM_ SG_ 1155 MO_Powermeter_Staging_Active "[DE: MO_Powermeter_Inszenierung_aktiv]";
CM_ SG_ 1155 MO_Powermeter_Charge_Limit "[DE: MO_Powermeter_Charge_Grenze]";
CM_ SG_ 1155 MO_Powermeter_Limit_strategisch "[DE: MO_Powermeter_Grenze_strategisch]";
CM_ SG_ 1155 MO_Powermeter_untere_E_Limit "[DE: MO_Powermeter_untere_E_Grenze]";
CM_ SG_ 1155 MO_Powermeter_Upper_E_Limit "[DE: MO_Powermeter_obere_E_Grenze]";
CM_ SG_ 1175 PDC_Tonausgabe_Rear "[DE: PDC_Tonausgabe_Heck]";
CM_ SG_ 1175 PH_Retrofit_Stop_Req "[DE: PH_nachtr_Stopp_Anf]";
CM_ SG_ 1175 PH_ShutoffCause "[DE: PH_Abschaltursache]";
CM_ SG_ 1175 PH_Opt_Display_V_On "[DE: PH_Opt_Anzeige_V_ein]";
CM_ SG_ 1175 PH_Opt_Display_H_On "[DE: PH_Opt_Anzeige_H_ein]";
CM_ SG_ 1175 PH_Opt_Disp_V_Obstacle "[DE: PH_Opt_Anz_V_Hindernis]";
CM_ SG_ 1175 PH_Opt_Disp_H_Obstacle "[DE: PH_Opt_Anz_H_Hindernis]";
CM_ SG_ 1175 PH_ToneSender_V_Active "[DE: PH_Tongeber_V_aktiv]";
CM_ SG_ 1175 PH_ToneSender_H_Active "[DE: PH_Tongeber_H_aktiv]";
CM_ SG_ 1175 PH_ToneSender_Mute "[DE: PH_Tongeber_mute]";
CM_ SG_ 1175 PH_Req_AudioDucking "[DE: PH_Anf_Audioabsenkung]";
CM_ SG_ 1175 PH_ToneSender_H_Available "[DE: PH_Tongeber_H_verfuegbar]";
CM_ SG_ 1175 PLA_Req_OpenShift_RVC "[DE: PLA_Anf_Aufschaltung_RVC]";
CM_ SG_ 1175 PH_PushButton "[DE: PH_Taster]";
CM_ SG_ 1175 PH_Req_Roof "[DE: PH_Anf_Verdeck]";
CM_ SG_ 1175 PH_Frequency_Rear "[DE: PH_Frequenz_hinten]";
CM_ SG_ 1175 PH_Volume_Rear "[DE: PH_Lautstaerke_hinten]";
CM_ SG_ 1175 PH_Frequency_Front "[DE: PH_Frequenz_vorn]";
CM_ SG_ 1175 PH_Volume_Front "[DE: PH_Lautstaerke_vorn]";
CM_ SG_ 1175 PH_StartStop_Info "[DE: PH_StartStopp_Info]";
CM_ SG_ 1175 PH_Defective "[DE: PH_defekt]";
CM_ SG_ 1175 PH_Disturbed "[DE: PH_gestoert]";
CM_ SG_ 1283 HVK_ActualMode_Req "[DE: HVK_Istmodus_Anf]";
CM_ SG_ 1283 HVK_TN1_TargetMode "[DE: HVK_TN1_Sollmodus]";
CM_ SG_ 1283 HVK_MO_EmTargetState "[DE: HVK_MO_EmSollzustand]";
CM_ SG_ 1283 HVK_BMS_TargetMode "[DE: HVK_BMS_Sollmodus]";
CM_ SG_ 1283 HVK_DCDC_TargetMode "[DE: HVK_DCDC_Sollmodus]";
CM_ SG_ 1283 HVK_EKK_TargetMode "[DE: HVK_EKK_Sollmodus]";
CM_ SG_ 1283 HVK_HVPTC_TargetMode "[DE: HVK_HVPTC_Sollmodus]";
CM_ SG_ 1283 HVK_HVLM_TargetMode "[DE: HVK_HVLM_Sollmodus]";
CM_ SG_ 1283 HVK_HV_Network_Warnings "[DE: HVK_HV_Netz_Warnungen]";
CM_ SG_ 1283 HV_VehicleElectrics_Active "[DE: HV_Bordnetz_aktiv]";
CM_ SG_ 1283 HV_VehicleElectrics_Error "[DE: HV_Bordnetz_Fehler]";
CM_ SG_ 1283 HVK_ActiveEntladung_Req "[DE: HVK_AktiveEntladung_Anf]";
CM_ SG_ 1283 HVK_Iso_Measurement_Start "[DE: HVK_Iso_Messung_Start]";
CM_ SG_ 1283 HVK_DCDC_EKK_TargetMode "[DE: HVK_DCDC_EKK_Sollmodus]";
CM_ SG_ 1312 LoGeWa_Event_ClusterWarning "[DE: LoGeWa_Event_Kombiwarnung]";
CM_ SG_ 1312 FROM_Request_eCall "[DE: AB_Anforderung_eCall]";
CM_ SG_ 1312 FROM_Impact_Side_Passenger "[DE: AB_Anprall_Seite_Beifahrer]";
CM_ SG_ 1312 FROM_Impact_Rollover "[DE: AB_Anprall_Rollover]";
CM_ SG_ 1312 FROM_Impact_FGS "[DE: AB_Anprall_FGS]";
CM_ SG_ 1312 FROM_Impact_Front_Passenger "[DE: AB_Anprall_Front_Beifahrer]";
CM_ SG_ 1312 FROM_Impact_Front_Driver "[DE: AB_Anprall_Front_Fahrer]";
CM_ SG_ 1312 FROM_Impact_Rear_Passenger "[DE: AB_Anprall_Heck_Beifahrer]";
CM_ SG_ 1312 FROM_Impact_Rear_Driver "[DE: AB_Anprall_Heck_Fahrer]";
CM_ SG_ 1312 FROM_WrapFold_Row2_MI "[DE: AB_Wickelklappung_Reihe2_MI]";
CM_ SG_ 1312 FROM_Occupancy_VB "[DE: AB_Belegung_VB]";
CM_ SG_ 1312 FROM_ShutoffReq_SIH_BF "[DE: AB_Abschaltanf_SIH_BF]";
CM_ SG_ 1312 FROM_Impact_Side_Driver "[DE: AB_Anprall_Seite_Fahrer]";
CM_ SG_ 1312 SC_PAO_Schriftzug_Req "[DE: SC_PAO_Schriftzug_Anf]";
CM_ SG_ 1312 SC_PAO_ON_Req "[DE: SC_PAO_ON_Anf]";
CM_ SG_ 1312 SC_PAO_OFF_Req "[DE: SC_PAO_OFF_Anf]";
CM_ SG_ 1312 FROM_CrashSeverity "[DE: AB_Crashschwere]";
CM_ SG_ 1312 FROM_Request_USM "[DE: AB_Anforderung_USM]";
CM_ SG_ 1312 FROM_BeltBuckle_FA "[DE: AB_Gurtschloss_FA]";
CM_ SG_ 1312 FROM_BeltBuckle_BF "[DE: AB_Gurtschloss_BF]";
CM_ SG_ 1312 FROM_BeltBuckle_Row2_FA "[DE: AB_Gurtschloss_Reihe2_FA]";
CM_ SG_ 1312 FROM_BeltBuckle_Row2_MI "[DE: AB_Gurtschloss_Reihe2_MI]";
CM_ SG_ 1312 FROM_BeltBuckle_Row2_BF "[DE: AB_Gurtschloss_Reihe2_BF]";
CM_ SG_ 1312 FROM_BeltBuckle_Row3_FA "[DE: AB_Gurtschloss_Reihe3_FA]";
CM_ SG_ 1312 FROM_BeltBuckle_Row3_MI "[DE: AB_Gurtschloss_Reihe3_MI]";
CM_ SG_ 1312 FROM_BeltBuckle_Row3_BF "[DE: AB_Gurtschloss_Reihe3_BF]";
CM_ SG_ 1312 FROM_SeatPos_Sens_FA "[DE: AB_Sitzpos_Sens_FA]";
CM_ SG_ 1312 FROM_SeatPos_Sens_BF "[DE: AB_Sitzpos_Sens_BF]";
CM_ SG_ 1312 FROM_WrapFold_Row2_BF "[DE: AB_Wickelklappung_Reihe2_BF]";
CM_ SG_ 1312 FROM_WrapFold_Row2_FA "[DE: AB_Wickelklappung_Reihe2_FA]";
CM_ SG_ 1349 FROM_BeltWarn_Row2_FA "[DE: AB_Gurtwarn_Reihe2_FA]";
CM_ SG_ 1349 FROM_BeltWarn_Row2_BF "[DE: AB_Gurtwarn_Reihe2_BF]";
CM_ SG_ 1349 AbstWarn_MV_FAS_Func_Status "[DE: AbstWarn_MV_FAS_Fkt_Status]";
CM_ SG_ 1349 WarnBrake_Charisma_Status "[DE: WarnBrems_Charisma_Status]";
CM_ SG_ 1349 WarnBrake_Charisma_DrivePr "[DE: WarnBrems_Charisma_FahrPr]";
CM_ SG_ 1349 FROM_BeltWarn_Row2_MI "[DE: AB_Gurtwarn_Reihe2_MI]";
CM_ SG_ 1349 FROM_BeltWarn_Row3_FA "[DE: AB_Gurtwarn_Reihe3_FA]";
CM_ SG_ 1349 FROM_BeltWarn_Row3_MI "[DE: AB_Gurtwarn_Reihe3_MI]";
CM_ SG_ 1349 FROM_BeltWarn_Row3_BF "[DE: AB_Gurtwarn_Reihe3_BF]";
CM_ SG_ 1349 LGI_FAS_Func_Status "[DE: LGI_FAS_Fkt_Status]";
CM_ SG_ 1349 PreCrash_FAS_Func_Status "[DE: PreCrash_FAS_Fkt_Status]";
CM_ SG_ 1349 FROM_SBR_Rear_Fitment "[DE: AB_SBR_hinten_verbau]";
CM_ SG_ 1349 AWV_OnPosition_System_ASG "[DE: AWV_Einstellung_System_ASG]";
CM_ SG_ 1349 AWV_OnPosition_Warning_ASG "[DE: AWV_Einstellung_Warnung_ASG]";
CM_ SG_ 1349 SC_PreSense_Mode_Warning_NV "[DE: SC_PreSense_Modus_Warnung_NV]";
CM_ SG_ 1349 SC_PreSense_Mode_Warning_MV "[DE: SC_PreSense_Modus_Warnung_MV]";
CM_ SG_ 1349 SC_PreSense_Mode_System_MV "[DE: SC_PreSense_Modus_System_MV]";
CM_ SG_ 1349 SC_PreSense_Mode_System_NV "[DE: SC_PreSense_Modus_System_NV]";
CM_ SG_ 1349 SC_PreSense_Mode_System_KAS "[DE: SC_PreSense_Modus_System_KAS]";
CM_ SG_ 1355 PH_OpenShiftCause "[DE: PH_Aufschaltursache]";
CM_ SG_ 1355 PH_Tone_Ausgabe "[DE: PH_Ton_Ausgabe]";
CM_ SG_ 1355 PH_Tone_Pausenlaenge "[DE: PH_Ton_Pausenlaenge]";
CM_ SG_ 1355 PH_Tone_Direction "[DE: PH_Ton_Richtung]";
CM_ SG_ 1355 PH_Tone_Volume "[DE: PH_Ton_Lautstaerke]";
CM_ SG_ 1355 PDC_Charisma_DrivePr "[DE: PDC_Charisma_FahrPr]";
CM_ SG_ 1361 WFS_Key_DriveAuthorisation "[DE: WFS_Schluessel_Fahrberecht]";
CM_ SG_ 1361 WFS_ID_Geb_Authorised "[DE: WFS_ID_Geb_autorisiert]";
CM_ SG_ 1361 WFS_ID_Geb_Authorised_in_Term15 "[DE: WFS_ID_Geb_autorisiert_in_Kl15]";
CM_ SG_ 1361 WFS_ID_Geb_Inserted "[DE: WFS_ID_Geb_steckt]";
CM_ SG_ 1361 WFS_Key_Target "[DE: WFS_Schluessel_Soll]";
CM_ SG_ 1361 WFS_Key_Actual "[DE: WFS_Schluessel_Ist]";
CM_ SG_ 1361 WFS_ELV_Authorised "[DE: WFS_ELV_authorisiert]";
CM_ SG_ 1361 WFS_LF_Active "[DE: WFS_LF_Aktiv]";
CM_ SG_ 1361 WFS_Operation_ReadCoil "[DE: WFS_Betrieb_Lesespule]";
CM_ SG_ 1361 WFS_TerminalsEnable "[DE: WFS_Klemmenfreigabe]";
CM_ SG_ 1361 WFS_DriverNotices "[DE: WFS_Fahrerhinweise]";
CM_ SG_ 1361 WFS_Parking_Status "[DE: WFS_Parken_Status]";
CM_ SG_ 1385 PTC_On_02 "[DE: PTC_ein_02]";
CM_ SG_ 1385 PTC_On_03 "[DE: PTC_ein_03]";
CM_ SG_ 1385 PTC_On_04 "[DE: PTC_ein_04]";
CM_ SG_ 1411 BCM_FH_Enable "[DE: BCM_FH_Freigabe]";
CM_ SG_ 1411 BCM_ComfortFunc_Enable "[DE: BCM_Komfortfkt_Freigabe]";
CM_ SG_ 1411 BCM_HSK_Enable "[DE: BCM_HSK_Freigabe]";
CM_ SG_ 1411 BCM_Roof_Enable "[DE: BCM_Verdeck_Freigabe]";
CM_ SG_ 1411 ZV_Locked_Internal_Actual "[DE: ZV_verriegelt_intern_ist]";
CM_ SG_ 1411 ZV_Locked_External_Actual "[DE: ZV_verriegelt_extern_ist]";
CM_ SG_ 1411 ZV_Locked_Internal_Target "[DE: ZV_verriegelt_intern_soll]";
CM_ SG_ 1411 ZV_Locked_External_Target "[DE: ZV_verriegelt_extern_soll]";
CM_ SG_ 1411 ZV_Safed_External_Actual "[DE: ZV_gesafet_extern_ist]";
CM_ SG_ 1411 ZV_Safed_External_Target "[DE: ZV_gesafet_extern_soll]";
CM_ SG_ 1411 ZV_FT_Open "[DE: ZV_FT_offen]";
CM_ SG_ 1411 ZV_BT_Open "[DE: ZV_BT_offen]";
CM_ SG_ 1411 ZV_HFS_Open "[DE: ZV_HFS_offen]";
CM_ SG_ 1411 ZV_HBFS_Open "[DE: ZV_HBFS_offen]";
CM_ SG_ 1411 ZV_HD_Open "[DE: ZV_HD_offen]";
CM_ SG_ 1411 ZV_HS_Open "[DE: ZV_HS_offen]";
CM_ SG_ 1411 IRUE_Active "[DE: IRUE_aktiv]";
CM_ SG_ 1411 DWA_Active "[DE: DWA_aktiv]";
CM_ SG_ 1411 HD_MainDetent "[DE: HD_Hauptraste]";
CM_ SG_ 1411 HD_PreDetent "[DE: HD_Vorraste]";
CM_ SG_ 1411 FFB_ComfortOpen "[DE: FFB_Komfortoeffnen]";
CM_ SG_ 1411 FFB_ComfortClose "[DE: FFB_Komfortschliessen]";
CM_ SG_ 1411 ZV_Key_Zugang "[DE: ZV_Schluessel_Zugang]";
CM_ SG_ 1411 ZV_SafeFunction_Active "[DE: ZV_SafeFunktion_aktiv]";
CM_ SG_ 1411 FBS_Warn_Key_Batt "[DE: FBS_Warn_Schluessel_Batt]";
CM_ SG_ 1411 ZV_OpeningMode "[DE: ZV_Oeffnungsmodus]";
CM_ SG_ 1411 HFS_Locked "[DE: HFS_verriegelt]";
CM_ SG_ 1411 HFS_Safed "[DE: HFS_gesafet]";
CM_ SG_ 1411 HBFS_Locked "[DE: HBFS_verriegelt]";
CM_ SG_ 1411 HBFS_Safed "[DE: HBFS_gesafet]";
CM_ SG_ 1411 ZV_Actual_State_Available "[DE: ZV_ist_Zustand_verfuegbar]";
CM_ SG_ 1411 IRUE_PushButton_Fkts_LED "[DE: IRUE_Taster_Fkts_LED]";
CM_ SG_ 1411 ZV_FuelFlap_Open "[DE: ZV_Tankklappe_offen]";
CM_ SG_ 1411 ZV_Blind_Open "[DE: ZV_Rollo_auf]";
CM_ SG_ 1411 ZV_Blind_Closed "[DE: ZV_Rollo_zu]";
CM_ SG_ 1411 ZV_SAD_Open "[DE: ZV_SAD_auf]";
CM_ SG_ 1411 ZV_SAD_Closed "[DE: ZV_SAD_zu]";
CM_ SG_ 1411 BCM_FuelFlapActuator_Error "[DE: BCM_Tankklappensteller_Fehler]";
CM_ SG_ 1411 ZV_Locked_Target "[DE: ZV_verriegelt_soll]";
CM_ SG_ 1413 SI_Collective_ECU_Error "[DE: SI_Sammel_SG_Fehler]";
CM_ SG_ 1413 SI_Diagnostics_Active "[DE: SI_Diagnose_Aktiv]";
CM_ SG_ 1413 SI_NWDF_Valid "[DE: SI_NWDF_gueltig]";
CM_ SG_ 1413 SI_GeneralFault "[DE: SI_Sammelfehler]";
CM_ SG_ 1413 GW_KD_Error "[DE: GW_KD_Fehler]";
CM_ SG_ 1413 SI_T_Protection "[DE: SI_T_Schutz]";
CM_ SG_ 1420 Terminals_Control_01_CRC "[DE: Klemmen_Steuerung_01_CRC]";
CM_ SG_ 1420 Terminals_Control_01_BZ "[DE: Klemmen_Steuerung_01_BZ]";
CM_ SG_ 1420 KST_Txt_P_Gear "[DE: KST_Txt_P_Gang]";
CM_ SG_ 1420 KST_Txt_PanicShutdown "[DE: KST_Txt_Panikabschaltung]";
CM_ SG_ 1420 KST_Req_TerminalsEnable_ELV "[DE: KST_Anf_Klemmenfreigabe_ELV]";
CM_ SG_ 1420 KST_Txt_ComfortShutdown "[DE: KST_Txt_Komfortabschaltung]";
CM_ SG_ 1420 KST_ZAT_Pressed "[DE: KST_ZAT_betaetigt]";
CM_ SG_ 1420 KST_Unterdr_IgnitionReport "[DE: KST_Unterdr_Zuendungsmeldung]";
CM_ SG_ 1420 KST_aut_Shutdown_Ignition "[DE: KST_aut_Abschaltung_Zuendung]";
CM_ SG_ 1420 KST_Req_ZV_Locking "[DE: KST_Anf_ZV_Verriegelung]";
CM_ SG_ 1420 Relay_VoKo_Actuated "[DE: Relais_VoKo_angesteuert]";
CM_ SG_ 1420 RSt_Request_HMS "[DE: RSt_Anforderung_HMS]";
CM_ SG_ 1440 LS_Brightness_IR "[DE: LS_Helligkeit_IR]";
CM_ SG_ 1440 LS_Brightness_FW "[DE: LS_Helligkeit_FW]";
CM_ SG_ 1440 LS_Defective "[DE: LS_defekt]";
CM_ SG_ 1440 LS_Fitment "[DE: LS_Verbau]";
CM_ SG_ 1440 RS_RainQuantity "[DE: RS_Regenmenge]";
CM_ SG_ 1440 RS_Fitment "[DE: RS_Verbau]";
CM_ SG_ 1440 RS_Glazing_Close "[DE: RS_Verglasung_schliessen]";
CM_ SG_ 1440 RS_Defective "[DE: RS_defekt]";
CM_ SG_ 1440 RS_WiperSpeed "[DE: RS_Wischergeschwindigkeit]";
CM_ SG_ 1440 RLS_BeforeFieldBrightness_Boost "[DE: RLS_Vorfeldhelligkeit_Boost]";
CM_ SG_ 1442 BMS_OBD_Lamp_Req "[DE: BMS_OBD_Lampe_Anf]";
CM_ SG_ 1442 BMS_ActualMode "[DE: BMS_IstModus]";
CM_ SG_ 1442 BMS_ErrorStatus "[DE: BMS_Fehlerstatus]";
CM_ SG_ 1442 BMS_Target_SOC_HiRes "[DE: BMS_Soll_SOC_HiRes]";
CM_ SG_ 1447 TM_Mirror_FoldIn "[DE: TM_Spiegel_Anklappen]";
CM_ SG_ 1447 TM_Only_Hupen "[DE: TM_Nur_Hupen]";
CM_ SG_ 1447 TM_HazardFlash "[DE: TM_Warnblinken]";
CM_ SG_ 1447 TM_Panic_Alarm "[DE: TM_Panik_Alarm]";
CM_ SG_ 1447 TM_ZV_Signature "[DE: TM_ZV_Signatur]";
CM_ SG_ 1452 HVEM_ActualCurrent_HVConsumer "[DE: HVEM_IstStrom_HVVerbraucher]";
CM_ SG_ 1452 HVEM_Energy_Climate_Specification_HighR "[DE: HVEM_Energie_Klima_Vorgabe_HighR]";
CM_ SG_ 1452 HVEM_ActualPowerNA "[DE: HVEM_IstLeistungNA]";
CM_ SG_ 1452 HVEM_Power_Climate_Specification "[DE: HVEM_Leistung_Klima_Vorgabe]";
CM_ SG_ 1452 HVEM_Nutzbare_Energy "[DE: HVEM_Nutzbare_Energie]";
CM_ SG_ 1452 HVEM_Energy_Climate_Specification "[DE: HVEM_Energie_Klima_Vorgabe]";
CM_ SG_ 1452 HVEM_MO_MaxPowerIgnored "[DE: HVEM_MO_MaxLeistungIgnoriert]";
CM_ SG_ 1485 DC_ErrorStatus "[DE: DC_Fehlerstatus]";
CM_ SG_ 1485 DC_PeakCurrent_Available "[DE: DC_Peakstrom_verfuegbar]";
CM_ SG_ 1485 DC_Limiting_Temperature "[DE: DC_Abregelung_Temperatur]";
CM_ SG_ 1485 DC_ActualMode_02 "[DE: DC_IstModus_02]";
CM_ SG_ 1485 DC_HV_EKK_ActualMode "[DE: DC_HV_EKK_IstModus]";
CM_ SG_ 1485 DC_ActualVoltage_EKK_HV "[DE: DC_IstSpannung_EKK_HV]";
CM_ SG_ 1485 DC_Temperature "[DE: DC_Temperatur]";
CM_ SG_ 1505 BCM1_Outside_Temp_Unfilt "[DE: BCM1_Aussen_Temp_ungef]";
CM_ SG_ 1505 BCM_HeatingShutOffValve_Status "[DE: BCM_Heizungsabsperrventil_Status]";
CM_ SG_ 1505 BCM_HeatingPump_Status "[DE: BCM_Heizungspumpe_Status]";
CM_ SG_ 1505 BCM_CompressorClutch_Status "[DE: BCM_Kompressorkupplung_Status]";
CM_ SG_ 1505 BCM1_FStatus_OutsideTemp_Unfilt "[DE: BCM1_FStatus_Aussentemp_ungef]";
CM_ SG_ 1505 BCM1_CompressorCurrent_Actual "[DE: BCM1_Kompressorstrom_ist]";
CM_ SG_ 1513 DS_Refrigerant_P "[DE: DS_Kaeltemittel_P]";
CM_ SG_ 1513 AAU_Blower "[DE: AAU_Geblaese]";
CM_ SG_ 1513 ION_Status_PushButton "[DE: ION_Status_Taster]";
CM_ SG_ 1520 DI_TERM_58xd "[DE: DI_KL_58xd]";
CM_ SG_ 1520 DI_TERM_58xs "[DE: DI_KL_58xs]";
CM_ SG_ 1520 DI_Display_NightDesign "[DE: DI_Display_Nachtdesign]";
CM_ SG_ 1520 DI_TERM_58xt "[DE: DI_KL_58xt]";
CM_ SG_ 1520 DI_PhotoSensor "[DE: DI_Fotosensor]";
CM_ SG_ 1524 IL_Dimming_V_Tuerkontur "[DE: IL_Dimmung_V_Tuerkontur]";
CM_ SG_ 1524 IL_Dimming_H_Tuerkontur "[DE: IL_Dimmung_H_Tuerkontur]";
CM_ SG_ 1524 IL_Dimming_DoorInsideHandle "[DE: IL_Dimmung_Tuerinnengriff]";
CM_ SG_ 1524 IL_Dimming_Umfeldbel "[DE: IL_Dimmung_Umfeldbel]";
CM_ SG_ 1524 IL_Bel_FS_Exit "[DE: IL_Bel_FS_Ausstieg]";
CM_ SG_ 1524 IL_Bel_BFS_Exit "[DE: IL_Bel_BFS_Ausstieg]";
CM_ SG_ 1524 IL_Bel_HFS_Exit "[DE: IL_Bel_HFS_Ausstieg]";
CM_ SG_ 1524 IL_Bel_HBFS_Exit "[DE: IL_Bel_HBFS_Ausstieg]";
CM_ SG_ 1524 BCM1_InsideLight_gedimmt_V "[DE: BCM1_Innenlicht_gedimmt_V]";
CM_ SG_ 1524 BCM1_InsideLight_gedimmt_H "[DE: BCM1_Innenlicht_gedimmt_H]";
CM_ SG_ 1524 IL_InsideLight_Active "[DE: IL_Innenlicht_aktiv]";
CM_ SG_ 1524 IL_Terminal_30G_Active "[DE: IL_Klemme_30G_aktiv]";
CM_ SG_ 1524 BCM1_DI_Ramp_InsideLight "[DE: BCM1_DI_Rampe_Innenlicht]";
CM_ SG_ 1524 BCM1_DI_Ramp_ReadingLight "[DE: BCM1_DI_Rampe_Leselicht]";
CM_ SG_ 1524 BCM1_InsideLight_H "[DE: BCM1_Innenlicht_H]";
CM_ SG_ 1524 BCM1_InsideLight_V "[DE: BCM1_Innenlicht_V]";
CM_ SG_ 1524 BCM1_ReadingLight_Req_hl "[DE: BCM1_Leselicht_Anf_hl]";
CM_ SG_ 1524 BCM1_ReadingLight_Req_hr "[DE: BCM1_Leselicht_Anf_hr]";
CM_ SG_ 1524 BCM1_ReadingLight_Req_vl "[DE: BCM1_Leselicht_Anf_vl]";
CM_ SG_ 1524 BCM1_ReadingLight_Req_vr "[DE: BCM1_Leselicht_Anf_vr]";
CM_ SG_ 1524 BCM1_Leuchten_Off "[DE: BCM1_Leuchten_Aus]";
CM_ SG_ 1524 AMB_Charisma_DrivePr "[DE: AMB_Charisma_FahrPr]";
CM_ SG_ 1524 IL_Dimming_Lautspr "[DE: IL_Dimmung_Lautspr]";
CM_ SG_ 1600 MO_QBit_IntakeAir_Temp "[DE: MO_QBit_Ansaugluft_Temp]";
CM_ SG_ 1600 MO_QBit_Oil_Temp "[DE: MO_QBit_Oel_Temp]";
CM_ SG_ 1600 MO_QBit_Coolant_Temp "[DE: MO_QBit_Kuehlmittel_Temp]";
CM_ SG_ 1600 MO_ActuatorTest_SoundActuator "[DE: MO_Stellgliedtest_Soundaktuator]";
CM_ SG_ 1600 MO_HYB_Error_HV_Network "[DE: MO_HYB_Fehler_HV_Netz]";
CM_ SG_ 1600 MO_Active_GearboxHeat "[DE: MO_aktives_Getriebeheizen]";
CM_ SG_ 1600 MO_ShutOffValve_Open "[DE: MO_Absperrventil_oeffnen]";
CM_ SG_ 1600 MO_IntakeAir_Temp "[DE: MO_Ansaugluft_Temp]";
CM_ SG_ 1600 MO_Oil_Temp "[DE: MO_Oel_Temp]";
CM_ SG_ 1600 MO_Coolant_Temp "[DE: MO_Kuehlmittel_Temp]";
CM_ SG_ 1600 MO_AltitudeInfo "[DE: MO_Hoeheninfo]";
CM_ SG_ 1600 MO_VersionInfo "[DE: MO_Versionsinfo]";
CM_ SG_ 1600 MO_Gearbox_Cool "[DE: MO_Getriebe_kuehlen]";
CM_ SG_ 1600 MO_Torque_Inertia_02 "[DE: MO_Mom_Traegheit_02]";
CM_ SG_ 1600 MO_HeatingPumpActuation "[DE: MO_Heizungspumpenansteuerung]";
CM_ SG_ 1600 MO_VoltageReq "[DE: MO_SpannungsAnf]";
CM_ SG_ 1600 MO_RunOnTime_HeatingPump "[DE: MO_Nachlaufzeit_Heizungspumpe]";
CM_ SG_ 1601 Engine_Code_01_CRC "[DE: Motor_Code_01_CRC]";
CM_ SG_ 1601 Engine_Code_01_BZ "[DE: Motor_Code_01_BZ]";
CM_ SG_ 1601 MO_Factor_Torques_02 "[DE: MO_Faktor_Momente_02]";
CM_ SG_ 1601 MO_HybridVehicle "[DE: MO_Hybridfahrzeug]";
CM_ SG_ 1601 MO_Gearbox_Code "[DE: MO_Getriebe_Code]";
CM_ SG_ 1601 MO_StartStop_Coded "[DE: MO_StartStopp_Codiert]";
CM_ SG_ 1601 MO_Count_Cyl "[DE: MO_Anzahl_Zyl]";
CM_ SG_ 1601 MO_FuelType "[DE: MO_Kraftstoffart]";
CM_ SG_ 1601 MO_Displacement "[DE: MO_Hubraum]";
CM_ SG_ 1601 MO_IntakeSystem "[DE: MO_Ansaugsystem]";
CM_ SG_ 1601 MO_Power "[DE: MO_Leistung]";
CM_ SG_ 1601 MO_ExhaustType_EOBD "[DE: MO_Abgastyp_EOBD]";
CM_ SG_ 1601 MO_ExhaustType_OBD "[DE: MO_Abgastyp_OBD]";
CM_ SG_ 1601 MO_DPF_Fitted "[DE: MO_DPF_verbaut]";
CM_ SG_ 1601 TSK_Coding "[DE: TSK_Codierung]";
CM_ SG_ 1601 MO_InjectionType "[DE: MO_Einspritzart]";
CM_ SG_ 1603 KBI_Unit_Date "[DE: KBI_Einheit_Datum]";
CM_ SG_ 1603 KBI_Unit_Pressure "[DE: KBI_Einheit_Druck]";
CM_ SG_ 1603 KBI_Unit_Streckenanz "[DE: KBI_Einheit_Streckenanz]";
CM_ SG_ 1603 KBI_MFA_v_Unit_02 "[DE: KBI_MFA_v_Einheit_02]";
CM_ SG_ 1603 KBI_Unit_Temp "[DE: KBI_Einheit_Temp]";
CM_ SG_ 1603 KBI_Unit_ClockTime "[DE: KBI_Einheit_Uhrzeit]";
CM_ SG_ 1603 KBI_Unit_Consumption "[DE: KBI_Einheit_Verbrauch]";
CM_ SG_ 1603 KBI_Unit_Volume "[DE: KBI_Einheit_Volumen]";
CM_ SG_ 1603 KBI_Unit_Consumption_elektr "[DE: KBI_Einheit_Verbrauch_elektr]";
CM_ SG_ 1603 KBI_Unit_Language "[DE: KBI_Einheit_Sprache]";
CM_ SG_ 1603 KBI_Unit_Consumption_Gas "[DE: KBI_Einheit_Verbrauch_Gas]";
CM_ SG_ 1603 KBI_Unit_Mass "[DE: KBI_Einheit_Masse]";
CM_ SG_ 1622 ELV_Req_Terminal_S "[DE: ELV_Anf_Klemme_S]";
CM_ SG_ 1622 ELV_Req_Terminal_15 "[DE: ELV_Anf_Klemme_15]";
CM_ SG_ 1622 ELV_Req_Terminal_50 "[DE: ELV_Anf_Klemme_50]";
CM_ SG_ 1622 ELV_01_SendStatus "[DE: ELV_01_Sendestatus]";
CM_ SG_ 1622 ELV_Locked "[DE: ELV_Verriegelt]";
CM_ SG_ 1622 ELV_Unlocked "[DE: ELV_Entriegelt]";
CM_ SG_ 1622 ELV_ZAT_Pressed "[DE: ELV_ZAT_betaetigt]";
CM_ SG_ 1622 ELV_LifeState "[DE: ELV_Lebenszustand]";
CM_ SG_ 1622 ELV_TerminalsEnable "[DE: ELV_Klemmenfreigabe]";
CM_ SG_ 1622 ELV_Abort_Req_TerminalsEnable "[DE: ELV_Abbruch_Anf_Klemmenfreigabe]";
CM_ SG_ 1622 ELV_LED_Red "[DE: ELV_LED_Rot]";
CM_ SG_ 1622 ELV_LED_Yellow "[DE: ELV_LED_Gelb]";
CM_ SG_ 1622 ELV_Txt_PanicShutdown "[DE: ELV_Txt_Panikabschaltung]";
CM_ SG_ 1622 ELV_Txt_Workshop "[DE: ELV_Txt_Werkstatt]";
CM_ SG_ 1622 ELV_Txt_Defective "[DE: ELV_Txt_Defekt]";
CM_ SG_ 1622 ELV_Txt_P_Gear "[DE: ELV_Txt_P_Gang]";
CM_ SG_ 1622 ELV_Txt_PN_Gear "[DE: ELV_Txt_PN_Gang]";
CM_ SG_ 1622 ELV_Txt_Clutch "[DE: ELV_Txt_Kupplung]";
CM_ SG_ 1622 ELV_Txt_Brake "[DE: ELV_Txt_Bremse]";
CM_ SG_ 1622 ELV_P_Locked "[DE: ELV_P_verriegelt]";
CM_ SG_ 1624 Light_Front_01_CRC "[DE: Licht_Vorne_01_CRC]";
CM_ SG_ 1624 Light_Front_01_BZ "[DE: Licht_Vorne_01_BZ]";
CM_ SG_ 1624 LV_SideLight_Display "[DE: LV_Standlicht_Anzeige]";
CM_ SG_ 1624 LV_LowBeam_Display "[DE: LV_Abblendlicht_Anzeige]";
CM_ SG_ 1624 LV_HighBeam_Display "[DE: LV_Fernlicht_Anzeige]";
CM_ SG_ 1624 LV_FogLight_Display "[DE: LV_Nebellicht_Anzeige]";
CM_ SG_ 1624 LV_RearFogLight_Display "[DE: LV_Nebelschlusslicht_Anzeige]";
CM_ SG_ 1624 LV_DaytimeRunningLight_Display "[DE: LV_Tagfahrlicht_Anzeige]";
CM_ SG_ 1624 LV_AFL_Active_Display "[DE: LV_AFL_aktiv_Anzeige]";
CM_ SG_ 1624 LV_AFL_Defective "[DE: LV_AFL_defekt]";
CM_ SG_ 1624 LV_Indicator_Left_def "[DE: LV_Blinker_li_def]";
CM_ SG_ 1624 LV_SideLight_Left_def "[DE: LV_Standlicht_li_def]";
CM_ SG_ 1624 LV_LowBeam_Left_def "[DE: LV_Abblendlicht_li_def]";
CM_ SG_ 1624 LV_HighBeam_Left_def "[DE: LV_Fernlicht_li_def]";
CM_ SG_ 1624 LV_FogLight_Left_def "[DE: LV_Nebellicht_li_def]";
CM_ SG_ 1624 LV_Blk_Left_Side_def "[DE: LV_Blk_li_Seite_def]";
CM_ SG_ 1624 LV_DaytimeRunningLight_Left_def "[DE: LV_Tagfahrlicht_li_def]";
CM_ SG_ 1624 LV_FLA_Active_Display "[DE: LV_FLA_aktiv_Anzeige]";
CM_ SG_ 1624 LV_FLA_Defective "[DE: LV_FLA_defekt]";
CM_ SG_ 1624 LV_FLA_Sensor_Blocked "[DE: LV_FLA_Sensor_blockiert]";
CM_ SG_ 1624 LV_Indicator_Right_def "[DE: LV_Blinker_re_def]";
CM_ SG_ 1624 LV_SideLight_Right_def "[DE: LV_Standlicht_re_def]";
CM_ SG_ 1624 LV_LowBeam_Right_def "[DE: LV_Abblendlicht_re_def]";
CM_ SG_ 1624 LV_HighBeam_Right_def "[DE: LV_Fernlicht_re_def]";
CM_ SG_ 1624 LV_FogLight_Right_def "[DE: LV_Nebellicht_re_def]";
CM_ SG_ 1624 LV_Blk_Right_Side_def "[DE: LV_Blk_re_Seite_def]";
CM_ SG_ 1624 LV_DaytimeRunningLight_Right_def "[DE: LV_Tagfahrlicht_re_def]";
CM_ SG_ 1624 LV_OutsideLight_def "[DE: LV_Aussenlicht_def]";
CM_ SG_ 1624 LV_LowBeam_TFL_Left_def "[DE: LV_Abblendlicht_TFL_li_def]";
CM_ SG_ 1624 LV_FogLight_TFL_Left_def "[DE: LV_Nebellicht_TFL_li_def]";
CM_ SG_ 1624 LV_SideLight_TFL_Left_def "[DE: LV_Standlicht_TFL_li_def]";
CM_ SG_ 1624 LV_Abblend_HighBeam_Left_def "[DE: LV_Abblend_Fernlicht_li_def]";
CM_ SG_ 1624 LV_LowBeam_TFL_Right_def "[DE: LV_Abblendlicht_TFL_re_def]";
CM_ SG_ 1624 LV_FogLight_TFL_Right_def "[DE: LV_Nebellicht_TFL_re_def]";
CM_ SG_ 1624 LV_SideLight_TFL_Right_def "[DE: LV_Standlicht_TFL_re_def]";
CM_ SG_ 1624 LV_Abblend_HighBeam_Right_def "[DE: LV_Abblend_Fernlicht_re_def]";
CM_ SG_ 1624 LV_TurnLight_Left_def "[DE: LV_Abbiegelicht_li_def]";
CM_ SG_ 1624 LV_TurnLight_Right_def "[DE: LV_Abbiegelicht_re_def]";
CM_ SG_ 1624 BCM1_LeftHandTraffic "[DE: BCM1_Linksverkehr]";
CM_ SG_ 1624 BCM1_Light_Darkness_Active "[DE: BCM1_Licht_Dunkelheit_aktiv]";
CM_ SG_ 1624 LV_LED_Scheinwerfer_Left_def "[DE: LV_LED_Scheinwerfer_li_def]";
CM_ SG_ 1624 LV_LED_Scheinwerfer_Right_def "[DE: LV_LED_Scheinwerfer_re_def]";
CM_ SG_ 1624 LV_Indicator_VL_Active "[DE: LV_Blinker_VL_aktiv]";
CM_ SG_ 1624 LV_Indicator_VR_Active "[DE: LV_Blinker_VR_aktiv]";
CM_ SG_ 1624 LV_MXB_Status_Display "[DE: LV_MXB_Status_Anzeige]";
CM_ SG_ 1629 BR_SystemType "[DE: BR_Systemart]";
CM_ SG_ 1629 ESP_VoltageReq_02 "[DE: ESP_SpannungsAnf_02]";
CM_ SG_ 1629 ESP_ToothCount "[DE: ESP_Zaehnezahl]";
CM_ SG_ 1629 ESP_Charisma_DrivePr "[DE: ESP_Charisma_FahrPr]";
CM_ SG_ 1629 ESP_Restart_Disp_01 "[DE: ESP_Wiederstart_Anz_01]";
CM_ SG_ 1629 ESP_Restart_Disp_02 "[DE: ESP_Wiederstart_Anz_02]";
CM_ SG_ 1629 ESP_Restart_Disp_03 "[DE: ESP_Wiederstart_Anz_03]";
CM_ SG_ 1629 ESP_Restart_Disp_04 "[DE: ESP_Wiederstart_Anz_04]";
CM_ SG_ 1629 ESP_StopInhibit_Disp_01 "[DE: ESP_Stoppverbot_Anz_01]";
CM_ SG_ 1629 ESP_StopInhibit_Disp_02 "[DE: ESP_Stoppverbot_Anz_02]";
CM_ SG_ 1629 ESP_StopInhibit_Disp_03 "[DE: ESP_Stoppverbot_Anz_03]";
CM_ SG_ 1629 ESP_StopInhibit_Disp_04 "[DE: ESP_Stoppverbot_Anz_04]";
CM_ SG_ 1629 ESP_StopInhibit_Disp_05 "[DE: ESP_Stoppverbot_Anz_05]";
CM_ SG_ 1629 ESP_StopInhibit_Disp_06 "[DE: ESP_Stoppverbot_Anz_06]";
CM_ SG_ 1629 ESP_StopInhibit_Disp_07 "[DE: ESP_Stoppverbot_Anz_07]";
CM_ SG_ 1629 ESP_StopInhibit_Disp_Std "[DE: ESP_Stoppverbot_Anz_Std]";
CM_ SG_ 1629 ESP_StopInhibit_Disp_08 "[DE: ESP_Stoppverbot_Anz_08]";
CM_ SG_ 1629 HDC_Charisma_DrivePr "[DE: HDC_Charisma_FahrPr]";
CM_ SG_ 1629 BR_QBit_TyreCircumference "[DE: BR_QBit_Reifenumfang]";
CM_ SG_ 1629 BR_TyreCircumference "[DE: BR_Reifenumfang]";
CM_ SG_ 1631 TSK_QBit_Gradient "[DE: TSK_QBit_Steigung]";
CM_ SG_ 1631 TSK_QBit_VehicleMass "[DE: TSK_QBit_Fahrzeugmasse]";
CM_ SG_ 1631 MO_VoltageReq_02 "[DE: MO_SpannungsAnf_02]";
CM_ SG_ 1631 MO_HeaterCurrent_EKAT "[DE: MO_Heizstrom_EKAT]";
CM_ SG_ 1631 MO_HeaterCurrent_SCR "[DE: MO_Heizstrom_SCR]";
CM_ SG_ 1631 MO_Display_ColdLamp "[DE: MO_Anzeige_Kaltleuchte]";
CM_ SG_ 1631 MO_P_Alternator_Unfiltered_Req "[DE: MO_P_Generator_ungefiltert_Anf]";
CM_ SG_ 1631 TSK_GearboxInfo "[DE: TSK_Getriebeinfo]";
CM_ SG_ 1631 MO_EnergyContents_BMS "[DE: MO_Energieinhalt_BMS]";
CM_ SG_ 1631 TSK_VehicleMass_02 "[DE: TSK_Fahrzeugmasse_02]";
CM_ SG_ 1631 TSK_Gradient_02 "[DE: TSK_Steigung_02]";
CM_ SG_ 1640 TERM_LRH_PushButton "[DE: KL_LRH_Taster]";
CM_ SG_ 1640 TERM_LRH_Stage "[DE: KL_LRH_Stufe]";
CM_ SG_ 1640 HSH_PushButton "[DE: HSH_Taster]";
CM_ SG_ 1640 FSH_PushButton "[DE: FSH_Taster]";
CM_ SG_ 1640 TERM_AuxHeater_Enable "[DE: KL_Zuheizer_Freigabe]";
CM_ SG_ 1640 TERM_FoggingRisk "[DE: KL_Beschlagsgefahr]";
CM_ SG_ 1640 TERM_SIH_Target_Left "[DE: KL_SIH_Soll_li]";
CM_ SG_ 1640 TERM_SIH_Target_Right "[DE: KL_SIH_Soll_re]";
CM_ SG_ 1640 KRH_Target_Left "[DE: KRH_Soll_li]";
CM_ SG_ 1640 TERM_SIL_Target_Left "[DE: KL_SIL_Soll_li]";
CM_ SG_ 1640 TERM_SIL_Target_Right "[DE: KL_SIL_Soll_re]";
CM_ SG_ 1640 KRH_Target_Right "[DE: KRH_Soll_re]";
CM_ SG_ 1640 TERM_Geblspng_Target "[DE: KL_Geblspng_Soll]";
CM_ SG_ 1640 TERM_Geblspng_Fond_Target "[DE: KL_Geblspng_Fond_Soll]";
CM_ SG_ 1640 TERM_I_Blower "[DE: KL_I_Geblaese]";
CM_ SG_ 1640 TERM_CompressorCurrent_Target "[DE: KL_Kompressorstrom_soll]";
CM_ SG_ 1640 TERM_RecirculationFlap_Status "[DE: KL_Umluftklappe_Status]";
CM_ SG_ 1640 TERM_PTC_FitmentInfo "[DE: KL_PTC_Verbauinfo]";
CM_ SG_ 1648 MO_max_BoostPressure "[DE: MO_max_Ladedruck]";
CM_ SG_ 1648 MO_ANC_Map_Req "[DE: MO_ANC_Kennfeld_Anf]";
CM_ SG_ 1648 MO_BrakeLight_Recup "[DE: MO_Bremslicht_Reku]";
CM_ SG_ 1648 MO_StartStop_PopUp "[DE: MO_StartStopp_PopUp]";
CM_ SG_ 1648 MO1_Lock_Info_WFS "[DE: MO1_Sperr_Info_WFS]";
CM_ SG_ 1648 MO1_Enable_Info_WFS "[DE: MO1_Freigabe_Info_WFS]";
CM_ SG_ 1648 MO_CylDeact_Texte_02 "[DE: MO_Zylabsch_Texte_02]";
CM_ SG_ 1648 MO_VehicleType "[DE: MO_Fahrzeugtyp]";
CM_ SG_ 1648 MO_NMAX_ShiftDisplay "[DE: MO_NMAX_Schaltanzeige]";
CM_ SG_ 1648 MO_ParkedTime "[DE: MO_Abstellzeit]";
CM_ SG_ 1648 MO_ParkedTime_Status "[DE: MO_Abstellzeit_Status]";
CM_ SG_ 1648 MO1_Enable_ExpiryInfo_WFS "[DE: MO1_Freigabe_Verfallsinfo_WFS]";
CM_ SG_ 1648 MO_Hybrid_StartStop_LED "[DE: MO_Hybrid_StartStopp_LED]";
CM_ SG_ 1648 MO_Error_CylDeact "[DE: MO_Fehler_Zylabsch]";
CM_ SG_ 1648 MO_Count_Abgesch_Cyl "[DE: MO_Anzahl_Abgesch_Zyl]";
CM_ SG_ 1648 MO_CylDeact_Texte "[DE: MO_Zylabsch_Texte]";
CM_ SG_ 1648 MO_Rpm_Warning "[DE: MO_Drehzahl_Warnung]";
CM_ SG_ 1648 MO_Upper_RpmLimit "[DE: MO_obere_Drehzahlgrenze]";
CM_ SG_ 1710 SP_FT_Top "[DE: SP_FT_oben]";
CM_ SG_ 1710 SP_FT_Bottom "[DE: SP_FT_unten]";
CM_ SG_ 1710 SP_FT_Left "[DE: SP_FT_links]";
CM_ SG_ 1710 SP_FT_Right "[DE: SP_FT_rechts]";
CM_ SG_ 1710 SP_BT_Top "[DE: SP_BT_oben]";
CM_ SG_ 1710 SP_BT_Bottom "[DE: SP_BT_unten]";
CM_ SG_ 1710 SP_BT_Left "[DE: SP_BT_links]";
CM_ SG_ 1710 SP_BT_Right "[DE: SP_BT_rechts]";
CM_ SG_ 1710 SP_FoldDown "[DE: SP_abklappen]";
CM_ SG_ 1710 SP_FoldIn "[DE: SP_anklappen]";
CM_ SG_ 1710 SP_Hzg_PushButton "[DE: SP_Hzg_Taster]";
CM_ SG_ 1710 SP_S_Top "[DE: SP_S_oben]";
CM_ SG_ 1710 SP_S_Bottom "[DE: SP_S_unten]";
CM_ SG_ 1710 SP_S_Left "[DE: SP_S_links]";
CM_ SG_ 1710 SP_S_Right "[DE: SP_S_rechts]";
CM_ SG_ 1710 SP_Selection_Left "[DE: SP_Auswahl_li]";
CM_ SG_ 1710 SP_Selection_Right "[DE: SP_Auswahl_re]";
CM_ SG_ 1710 SP_S_Fold "[DE: SP_S_Klappen]";
CM_ SG_ 1710 SP_Verstellschalter_Error "[DE: SP_Verstellschalter_Fehler]";
CM_ SG_ 1711 RV_System_Active "[DE: RV_System_aktiv]";
CM_ SG_ 1711 RV_Reinigung_Req "[DE: RV_Reinigung_Anf]";
CM_ SG_ 1711 RV_Calib_Error "[DE: RV_Calib_Fehler]";
CM_ SG_ 1711 RV_GL_LWS_Error "[DE: RV_GL_LWS_Fehler]";
CM_ SG_ 1711 RV_Brightness "[DE: RV_Helligkeit]";
CM_ SG_ 1711 ZFAS_Umfeldbeleuchtung_Req "[DE: ZFAS_Umfeldbeleuchtung_Anf]";
CM_ SG_ 1711 RV_Colour "[DE: RV_Farbe]";
CM_ SG_ 1714 DGN_UnlearnCounter "[DE: DGN_Verlernzaehler]";
CM_ SG_ 1714 KBI_Odometer "[DE: KBI_Kilometerstand]";
CM_ SG_ 1714 UH_Year "[DE: UH_Jahr]";
CM_ SG_ 1714 UH_Month "[DE: UH_Monat]";
CM_ SG_ 1714 UH_Hour "[DE: UH_Stunde]";
CM_ SG_ 1714 UH_Second "[DE: UH_Sekunde]";
CM_ SG_ 1714 Cluster_02_Old "[DE: Kombi_02_alt]";
CM_ SG_ 1714 ClockTime_01_Old "[DE: Uhrzeit_01_alt]";
CM_ SG_ 1716 KS_Secret_1 "[DE: KS_Geheimnis_1]";
CM_ SG_ 1716 KS_Secret_2 "[DE: KS_Geheimnis_2]";
CM_ SG_ 1716 KS_Secret_3 "[DE: KS_Geheimnis_3]";
CM_ SG_ 1716 KS_Secret_4 "[DE: KS_Geheimnis_4]";
CM_ SG_ 316495015 VZE_DisplayMode "[DE: VZE_Anzeigemodus]";
CM_ SG_ 316495015 VZE_DisplaySuppress_Sign_3 "[DE: VZE_Anzeigeunterdrueck_Zeichen_3]";
CM_ SG_ 316495015 VZE_DisplaySuppress_Sign_2 "[DE: VZE_Anzeigeunterdrueck_Zeichen_2]";
CM_ SG_ 316495015 VZE_TrafficSign_1 "[DE: VZE_Verkehrszeichen_1]";
CM_ SG_ 316495015 VZE_TrafficSign_2 "[DE: VZE_Verkehrszeichen_2]";
CM_ SG_ 316495015 VZE_TrafficSign_3 "[DE: VZE_Verkehrszeichen_3]";
CM_ SG_ 316495015 VZE_Warning_TrafficSign_1 "[DE: VZE_Warnung_Verkehrszeichen_1]";
CM_ SG_ 316495015 VZE_Warning_TrafficSign_2 "[DE: VZE_Warnung_Verkehrszeichen_2]";
CM_ SG_ 316495015 VZE_Warning_TrafficSign_3 "[DE: VZE_Warnung_Verkehrszeichen_3]";
CM_ SG_ 316495015 VZE_SupplementarySign_1 "[DE: VZE_Zusatzschild_1]";
CM_ SG_ 316495015 VZE_SupplementarySign_2 "[DE: VZE_Zusatzschild_2]";
CM_ SG_ 316495015 VZE_SupplementarySign_3 "[DE: VZE_Zusatzschild_3]";
CM_ SG_ 316495015 VZE_DisplaySuppress_Sign_1 "[DE: VZE_Anzeigeunterdrueck_Zeichen_1]";
CM_ SG_ 316495015 VZE_Sign_01_CameraWied "[DE: VZE_Zeichen_01_KameraWied]";
CM_ SG_ 316495015 VZE_Sign_02_CameraWied "[DE: VZE_Zeichen_02_KameraWied]";
CM_ SG_ 316495015 VZE_Sign_03_CameraWied "[DE: VZE_Zeichen_03_KameraWied]";
CM_ SG_ 316495015 VZE_Sign_01_Camera "[DE: VZE_Zeichen_01_Kamera]";
CM_ SG_ 316495015 VZE_Sign_01_Map "[DE: VZE_Zeichen_01_Karte]";
CM_ SG_ 316495015 VZE_Sign_01_Law "[DE: VZE_Zeichen_01_Gesetz]";
CM_ SG_ 316495015 VZE_Sign_02_Camera "[DE: VZE_Zeichen_02_Kamera]";
CM_ SG_ 316495015 VZE_Sign_02_Map "[DE: VZE_Zeichen_02_Karte]";
CM_ SG_ 316495015 VZE_Sign_02_Law "[DE: VZE_Zeichen_02_Gesetz]";
CM_ SG_ 316495015 VZE_Sign_03_Camera "[DE: VZE_Zeichen_03_Kamera]";
CM_ SG_ 316495015 VZE_Sign_03_Map "[DE: VZE_Zeichen_03_Karte]";
CM_ SG_ 316495015 VZE_Sign_03_Law "[DE: VZE_Zeichen_03_Gesetz]";
CM_ SG_ 316495015 VZE_Chime "[DE: VZE_Gong]";
CM_ SG_ 316495015 VZE_TrafficSign_4 "[DE: VZE_Verkehrszeichen_4]";
CM_ SG_ 316495015 VZE_TrafficSign_6 "[DE: VZE_Verkehrszeichen_6]";
CM_ SG_ 316495015 VZE_Roadworks "[DE: VZE_Baustelle]";
CM_ SG_ 316495049 Right_Indicator "[DE: Right_Blinker]";
CM_ SG_ 316495049 Left_Indicator "[DE: Left_Blinker]";
CM_ SG_ 316495049 Right_Indicator_02 "[DE: Right_Blinker_02]";
CM_ SG_ 316495049 Left_Indicator_02 "[DE: Left_Blinker_02]";
CM_ SG_ 496 ACF_Lamp_Hands_Off "[DE: ACF_Lampe_Hands_Off]";
CM_ SG_ 496 EA_Infotainment_Req "[DE: EA_Infotainment_Anf]";
CM_ SG_ 496 EA_Doors_Req "[DE: EA_Tueren_Anf]";
CM_ SG_ 496 EA_Innenraumlicht_Req "[DE: EA_Innenraumlicht_Anf]";
CM_ SG_ 496 zFAS_HazardFlash "[DE: zFAS_Warnblinken]";
CM_ SG_ 496 STP_PrimaryDisplay "[DE: STP_Primaeranz]";
CM_ SG_ 496 EA_BrakeLightFlash "[DE: EA_Bremslichtblinken]";
CM_ SG_ 496 EA_Flash "[DE: EA_Blinken]";
CM_ SG_ 768 ACC_SpeedLimit "[DE: ACC_Tempolimit]";
CM_ SG_ 768 ACC_SetSpeed_Colour "[DE: ACC_Wunschgeschw_Farbe]";
CM_ SG_ 768 ACC_Warning_TrafficSign_1 "[DE: ACC_Warnung_Verkehrszeichen_1]";
CM_ SG_ 768 ACA_LateralGuidance "[DE: ACA_Querfuehrung]";
CM_ SG_ 768 ACC_Control_AIO "[DE: ACC_Regelung_AIO]";
CM_ SG_ 768 ACC_SetSpeed_02 "[DE: ACC_Wunschgeschw_02]";
CM_ SG_ 768 ACC_DistanceIndex_02 "[DE: ACC_Abstandsindex_02]";
CM_ SG_ 768 ACC_rel_Object_AuxDisplay "[DE: ACC_rel_Objekt_Zusatzanz]";
CM_ SG_ 768 ACC_Set_TimeGap "[DE: ACC_Gesetzte_Zeitluecke]";
CM_ SG_ 768 ACC_Optical_DriverNotice "[DE: ACC_Optischer_Fahrerhinweis]";
CM_ SG_ 768 ACC_WarningNote "[DE: ACC_Warnhinweis]";
CM_ SG_ 768 ACC_EGO_Vehicle "[DE: ACC_EGO_Fahrzeug]";
CM_ SG_ 768 ACC_Relevant_Object_02 "[DE: ACC_Relevantes_Objekt_02]";
CM_ SG_ 768 ACC_SetSpeed_Reached "[DE: ACC_Wunschgeschw_erreicht]";
CM_ SG_ 768 ACC_Display_TimeGap "[DE: ACC_Anzeige_Zeitluecke]";
CM_ SG_ 768 ACC_Texte_PrimaryDisplay_02 "[DE: ACC_Texte_Primaeranz_02]";
CM_ SG_ 768 ACC_Texte_AuxDisplay_02 "[DE: ACC_Texte_Zusatzanz_02]";
CM_ SG_ 768 Status_PrimaryDisplay "[DE: STA_Primaeranz]";
CM_ SG_ 768 ACC_Event_SetSpeed "[DE: ACC_Event_Wunschgeschw]";
CM_ SG_ 768 TimeGap_Colour "[DE: Zeitluecke_Farbe]";
CM_ SG_ 768 ACC_Akustischer_DriverNotice "[DE: ACC_Akustischer_Fahrerhinweis]";
CM_ SG_ 768 TimeGap_1 "[DE: Zeitluecke_1]";
CM_ SG_ 768 TimeGap_2 "[DE: Zeitluecke_2]";
CM_ SG_ 768 TimeGap_3 "[DE: Zeitluecke_3]";
CM_ SG_ 768 TimeGap_4 "[DE: Zeitluecke_4]";
CM_ SG_ 768 TimeGap_5 "[DE: Zeitluecke_5]";
CM_ SG_ 252 HL_WheelSpeed "[DE: HL_Radgeschw]";
CM_ SG_ 252 HR_WheelSpeed "[DE: HR_Radgeschw]";
CM_ SG_ 252 VL_WheelSpeed "[DE: VL_Radgeschw]";
CM_ SG_ 252 VR_WheelSpeed "[DE: VR_Radgeschw]";
CM_ SG_ 267 TSK_Limiter_Selected "[DE: TSK_Limiter_ausgewaehlt]";
CM_ BO_ 997 "[DE: TSG_FT_02]";
CM_ BO_ 1155 "[DE: Motor_Hybrid_06]";
CM_ BO_ 1175 "[DE: Parkhilfe_01]";
CM_ BO_ 1355 "[DE: Parkhilfe_04]";
CM_ BO_ 1413 "[DE: Systeminfo_01]";
CM_ BO_ 1420 "[DE: Klemmen_Steuerung_01]";
CM_ BO_ 1505 "[DE: Klima_Sensor_02]";
CM_ BO_ 1513 "[DE: Klima_Sensor_04]";
CM_ BO_ 1520 "[DE: Dimmung_01]";
CM_ BO_ 1524 "[DE: Innenlicht_11]";
CM_ BO_ 1600 "[DE: Motor_07]";
CM_ BO_ 1601 "[DE: Motor_Code_01]";
CM_ BO_ 1603 "[DE: Einheiten_01]";
CM_ BO_ 1624 "[DE: Licht_vorne_01]";
CM_ BO_ 1631 "[DE: Motor_16]";
CM_ BO_ 1640 "[DE: Klima_12]";
CM_ BO_ 1648 "[DE: Motor_18]";
CM_ BO_ 1710 "[DE: Spiegel_01]";
CM_ BO_ 1714 "[DE: Diagnose_01]";
CM_ BO_ 267 "[DE: Motor_51]";
